[part 2 of 4: packages /Cluster to /NmConfig]
AUTOSAR XML (schema 4-3-0)
package /Cluster
  lin cluster Zone_VR_LIN12: baudrate=19200, protocol-name=LIN, protocol-version=2.0
    lin physical channel CHNL: comm-connectors=CN_Zone_VR_LIN12
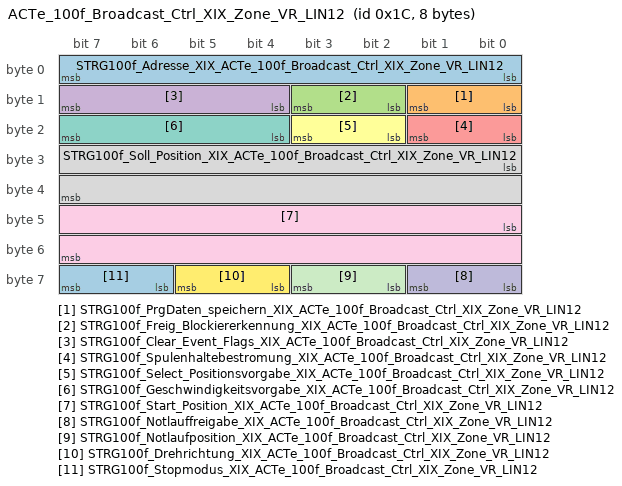
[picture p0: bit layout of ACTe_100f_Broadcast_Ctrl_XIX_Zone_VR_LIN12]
      frame ACTe_100f_Broadcast_Ctrl_XIX_Zone_VR_LIN12: id 0x1C, from Zone_VR, frame-length=8, lin-checksum=ENHANCED
        pdu ACTe_100f_Broadcast_Ctrl_XIX_Zone_VR_LIN12: length=8, unused-bit-pattern=0
          signal STRG100f_Adresse_XIX_ACTe_100f_Broadcast_Ctrl_XIX_Zone_VR_LIN12: start 0, 8 bit, little-endian, data-type-policy=OVERRIDE, i-signal-type=PRIMITIVE, init-value=0, base-type=BT_STRG100f_Adresse, invalid-value=Invalid_STRG100f_Adresse_XIX_ACTe_100f_Broadcast_Ctrl_XIX_Zone_VR_LIN12:255, compu {phys=raw for raw 0..253, 255=Cxff_Fehler, 254=Cxfe_IDLE_INIT; unit Unit_None}, range phys 0..253 Unit_None, raw 0..255, unit=Unit_None, transfer-property=PENDING  # Knotenadresse des Empfängers, 127(dez) ist "Broadcast", 128.....159 (dez) sind Gruppenadressen
          signal STRG100f_PrgDaten_speichern_XIX_ACTe_100f_Broadcast_Ctrl_XIX_Zone_VR_LIN12: start 8, 2 bit, little-endian, data-type-policy=OVERRIDE, i-signal-type=PRIMITIVE, init-value=0, base-type=BT_STRG100f_PrgDaten_speichern, invalid-value=Invalid_STRG100f_PrgDaten_speichern_XIX_ACTe_100f_Broadcast_Ctrl_XIX_Zone_VR_LIN12:3, compu {3=Cx3_Fehler, 2=Cx2_reserviert, 0=Cx0_nicht_speichern, 1=Cx1_speichern}, range raw 0..3, transfer-property=PENDING  # Speicherung der Programmierdaten
          signal STRG100f_Freig_Blockiererkennung_XIX_ACTe_100f_Broadcast_Ctrl_XIX_Zone_VR_LIN12: start 10, 2 bit, little-endian, data-type-policy=OVERRIDE, i-signal-type=PRIMITIVE, init-value=0, base-type=BT_STRG100f_Freig_Blockiererkennung, invalid-value=Invalid_STRG100f_Freig_Blockiererkennung_XIX_ACTe_100f_Broadcast_Ctrl_XIX_Zone_VR_LIN12:3, compu {3=Cx3_Fehler, 1=Cx1_Blockiererkennung_ein, 0=Cx0_Blockiererkennung_aus, 2=Cx2_reserviert}, range raw 0..3, transfer-property=PENDING  # Das Master-SG gibt eine aktive oder inaktive Blockiererkennung vor
          signal STRG100f_Clear_Event_Flags_XIX_ACTe_100f_Broadcast_Ctrl_XIX_Zone_VR_LIN12: start 12, 4 bit, little-endian, data-type-policy=OVERRIDE, i-signal-type=PRIMITIVE, init-value=0, base-type=BT_STRG100f_Clear_Event_Flags, invalid-value=Invalid_STRG100f_Clear_Event_Flags_XIX_ACTe_100f_Broadcast_Ctrl_XIX_Zone_VR_LIN12:15, compu {15=Cxf_Fehler, 4=Cx4_Clear_BL, 12=Cxc_Clear_BL_Reset, 0=Cx0_Event_Flags_nicht_zuruecksetzen, 14=Cxe_Clear_NL_BL_Reset, 6=Cx6_Clear_NL_BL, 8=Cx8_Clear_Reset, 2=Cx2_Clear_NL, 10=Cxa_Clear_NL_Reset}, range raw 0..15, transfer-property=PENDING  # Das Steuergerät löscht die Event-Flags NL: Notlauf aufgetreten, BL: Blockierung aufgetreten
          signal STRG100f_Spulenhaltebestromung_XIX_ACTe_100f_Broadcast_Ctrl_XIX_Zone_VR_LIN12: start 16, 2 bit, little-endian, data-type-policy=OVERRIDE, i-signal-type=PRIMITIVE, init-value=0, base-type=BT_STRG100f_Spulenhaltebestromung, invalid-value=Invalid_STRG100f_Spulenhaltebestromung_XIX_ACTe_100f_Broadcast_Ctrl_XIX_Zone_VR_LIN12:3, compu {3=Cx3_Fehler, 1=Cx1_Motorspulen_bestromt, 0=Cx0_Motorspulen_unbestromt, 2=Cx2_reserviert}, range raw 0..3, transfer-property=PENDING  # Vorgabe für die Spulenhaltebestromung im STOP-Mode
          signal STRG100f_Select_Positionsvorgabe_XIX_ACTe_100f_Broadcast_Ctrl_XIX_Zone_VR_LIN12: start 18, 2 bit, little-endian, data-type-policy=OVERRIDE, i-signal-type=PRIMITIVE, init-value=0, base-type=BT_STRG100f_Select_Positionsvorgabe, invalid-value=Invalid_STRG100f_Select_Positionsvorgabe_XIX_ACTe_100f_Broadcast_Ctrl_XIX_Zone_VR_LIN12:3, compu {3=Cx3_Fehler, 2=Cx2_keine_Positionsvorgabe_gueltig, 1=Cx1_Start_Position_gueltig, 0=Cx0_Soll_Position_gueltig}, range raw 0..3, transfer-property=PENDING  # Vorgabe der Gültigkeit der Positionsvorgaben
          signal STRG100f_Geschwindigkeitsvorgabe_XIX_ACTe_100f_Broadcast_Ctrl_XIX_Zone_VR_LIN12: start 20, 4 bit, little-endian, data-type-policy=OVERRIDE, i-signal-type=PRIMITIVE, init-value=0, base-type=BT_STRG100f_Geschwindigkeitsvorgabe, invalid-value=Invalid_STRG100f_Geschwindigkeitsvorgabe_XIX_ACTe_100f_Broadcast_Ctrl_XIX_Zone_VR_LIN12:15, compu {15=Cxf_Fehler, 4=Cx4_Geschwindigkeitsstufe_4, 3=Cx3_Geschwindigkeitsstufe_3, 2=Cx2_Geschwindigkeitsstufe_2, 1=Cx1_Geschwindigkeitsstufe_1, 5=Cx5_Autospeed, 0=Cx0_reserviert}, range raw 0..15, transfer-property=PENDING  # Vorgabe der Geschwindigkeitsstufe
          signal STRG100f_Soll_Position_XIX_ACTe_100f_Broadcast_Ctrl_XIX_Zone_VR_LIN12: start 24, 16 bit, little-endian, data-type-policy=OVERRIDE, i-signal-type=PRIMITIVE, init-value=0, base-type=BT_STRG100f_Soll_Position, invalid-value=Invalid_STRG100f_Soll_Position_XIX_ACTe_100f_Broadcast_Ctrl_XIX_Zone_VR_LIN12:65535, compu {phys=raw for raw 0..65534, 65535=Cxffff_Fehler; unit Unit_None}, range phys 0..65534 Unit_None, raw 0..65535, unit=Unit_None, transfer-property=PENDING  # Vorgabe der Sollposition
          signal STRG100f_Start_Position_XIX_ACTe_100f_Broadcast_Ctrl_XIX_Zone_VR_LIN12: start 40, 16 bit, little-endian, data-type-policy=OVERRIDE, i-signal-type=PRIMITIVE, init-value=0, base-type=BT_STRG100f_Start_Position, invalid-value=Invalid_STRG100f_Start_Position_XIX_ACTe_100f_Broadcast_Ctrl_XIX_Zone_VR_LIN12:65535, compu {phys=raw for raw 0..65534, 65535=Cxffff_Fehler; unit Unit_None}, range phys 0..65534 Unit_None, raw 0..65535, unit=Unit_None, transfer-property=PENDING  # Vorgabe der Startposition
          signal STRG100f_Notlauffreigabe_XIX_ACTe_100f_Broadcast_Ctrl_XIX_Zone_VR_LIN12: start 56, 2 bit, little-endian, data-type-policy=OVERRIDE, i-signal-type=PRIMITIVE, init-value=0, base-type=BT_STRG100f_Notlauffreigabe, invalid-value=Invalid_STRG100f_Notlauffreigabe_XIX_ACTe_100f_Broadcast_Ctrl_XIX_Zone_VR_LIN12:3, compu {3=Cx3_Fehler, 2=Cx2_reserviert, 0=Cx0_Notlauf_aus, 1=Cx1_Notlauf_ein}, range raw 0..3, transfer-property=PENDING  # Freigabe des Notlaufs
          signal STRG100f_Notlaufposition_XIX_ACTe_100f_Broadcast_Ctrl_XIX_Zone_VR_LIN12: start 58, 2 bit, little-endian, data-type-policy=OVERRIDE, i-signal-type=PRIMITIVE, init-value=0, base-type=BT_STRG100f_Notlaufposition, invalid-value=Invalid_STRG100f_Notlaufposition_XIX_ACTe_100f_Broadcast_Ctrl_XIX_Zone_VR_LIN12:3, compu {3=Cx3_Fehler, 1=Cx1_oberer_Anschlag, 2=Cx2_reserviert, 0=Cx0_unterer_Anschlag}, range raw 0..3, transfer-property=PENDING  # Positionsvorgabe, welche bei aktiven Notlauf angelaufen wird
          signal STRG100f_Drehrichtung_XIX_ACTe_100f_Broadcast_Ctrl_XIX_Zone_VR_LIN12: start 60, 2 bit, little-endian, data-type-policy=OVERRIDE, i-signal-type=PRIMITIVE, init-value=0, base-type=BT_STRG100f_Drehrichtung, invalid-value=Invalid_STRG100f_Drehrichtung_XIX_ACTe_100f_Broadcast_Ctrl_XIX_Zone_VR_LIN12:3, compu {3=Cx3_Fehler, 2=Cx2_reserviert, 0=Cx0_Bewegung_in_Richtung_CW, 1=Cx1_Bewegung_in_Richtung_CCW}, range raw 0..3, transfer-property=PENDING  # Vorgabe der Drehrichtung
          signal STRG100f_Stopmodus_XIX_ACTe_100f_Broadcast_Ctrl_XIX_Zone_VR_LIN12: start 62, 2 bit, little-endian, data-type-policy=OVERRIDE, i-signal-type=PRIMITIVE, init-value=0, base-type=BT_STRG100f_Stopmodus, invalid-value=Invalid_STRG100f_Stopmodus_XIX_ACTe_100f_Broadcast_Ctrl_XIX_Zone_VR_LIN12:3, compu {3=Cx3_Fehler, 0=Cx0_normal_mode, 1=Cx1_stop_mode, 2=Cx2_Status_Adresse_als_Gruppenadr}, range raw 0..3, transfer-property=PENDING  # Vorgabe des StopModus
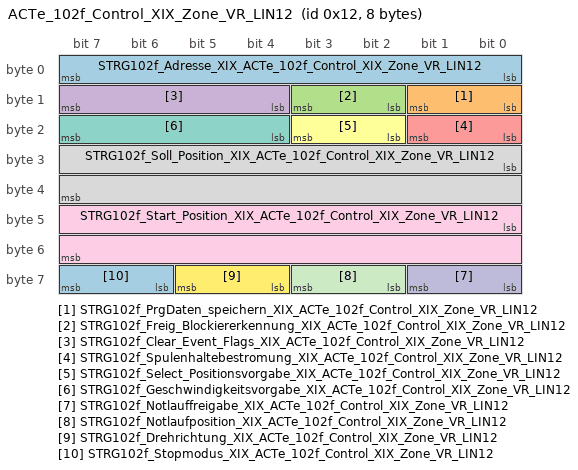
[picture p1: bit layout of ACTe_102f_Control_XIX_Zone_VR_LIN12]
      frame ACTe_102f_Control_XIX_Zone_VR_LIN12: id 0x12, from Zone_VR, frame-length=8, lin-checksum=ENHANCED
        pdu ACTe_102f_Control_XIX_Zone_VR_LIN12: length=8, unused-bit-pattern=0
          signal STRG102f_Adresse_XIX_ACTe_102f_Control_XIX_Zone_VR_LIN12: start 0, 8 bit, little-endian, data-type-policy=OVERRIDE, i-signal-type=PRIMITIVE, init-value=254, base-type=BT_STRG102f_Adresse, invalid-value=Invalid_STRG102f_Adresse_XIX_ACTe_102f_Control_XIX_Zone_VR_LIN12:255, compu {phys=raw for raw 0..253, 255=Cxff_Fehler, 254=Cxfe_IDLE_INIT; unit Unit_None}, range phys 0..253 Unit_None, raw 0..255, unit=Unit_None, transfer-property=PENDING  # Knotenadresse des Empfängers, 127(dez) ist "Broadcast", 128.....159 (dez) sind Gruppenadressen
          signal STRG102f_PrgDaten_speichern_XIX_ACTe_102f_Control_XIX_Zone_VR_LIN12: start 8, 2 bit, little-endian, data-type-policy=OVERRIDE, i-signal-type=PRIMITIVE, init-value=0, base-type=BT_STRG102f_PrgDaten_speichern, compu {2=Cx2_reserviert, 0=Cx0_nicht_speichern, 1=Cx1_speichern}, range raw 0..2, transfer-property=PENDING  # Speicherung der Programmierdaten
          signal STRG102f_Freig_Blockiererkennung_XIX_ACTe_102f_Control_XIX_Zone_VR_LIN12: start 10, 2 bit, little-endian, data-type-policy=OVERRIDE, i-signal-type=PRIMITIVE, init-value=0, base-type=BT_STRG102f_Freig_Blockiererkennung, compu {1=Cx1_Blockiererkennung_ein, 2=Cx2_reserviert, 0=Cx0_Blockiererkennung_aus}, range raw 0..2, transfer-property=PENDING  # Das Master-SG gibt eine aktive oder inaktive Blockiererkennung vor
          signal STRG102f_Clear_Event_Flags_XIX_ACTe_102f_Control_XIX_Zone_VR_LIN12: start 12, 4 bit, little-endian, data-type-policy=OVERRIDE, i-signal-type=PRIMITIVE, init-value=0, base-type=BT_STRG102f_Clear_Event_Flags, compu {6=Cx6_Clear_NL_BL, 14=Cxe_Clear_NL_BL_Reset, 0=Cx0_Event_Flags_nicht_zuruecksetzen, 2=Cx2_Clear_NL, 4=Cx4_Clear_BL, 12=Cxc_Clear_BL_Reset, 10=Cxa_Clear_NL_Reset, 8=Cx8_Clear_Reset}, range raw 0..14, transfer-property=PENDING  # Das Steuergerät löscht die Event-Flags NL: Notlauf aufgetreten, BL: Blockierung aufgetreten
          signal STRG102f_Spulenhaltebestromung_XIX_ACTe_102f_Control_XIX_Zone_VR_LIN12: start 16, 2 bit, little-endian, data-type-policy=OVERRIDE, i-signal-type=PRIMITIVE, init-value=0, base-type=BT_STRG102f_Spulenhaltebestromung, compu {1=Cx1_Motorspulen_bestromt, 0=Cx0_Motorspulen_unbestromt, 2=Cx2_reserviert}, range raw 0..2, transfer-property=PENDING  # Vorgabe für die Spulenhaltebestromung im STOP-Mode
          signal STRG102f_Select_Positionsvorgabe_XIX_ACTe_102f_Control_XIX_Zone_VR_LIN12: start 18, 2 bit, little-endian, data-type-policy=OVERRIDE, i-signal-type=PRIMITIVE, init-value=0, base-type=BT_STRG102f_Select_Positionsvorgabe, compu {0=Cx0_Soll_Position_gueltig, 2=Cx2_keine_Positionsvorgabe_gueltig, 1=Cx1_Start_Position_gueltig}, range raw 0..2, transfer-property=PENDING  # Vorgabe der Gültigkeit der Positionsvorgaben
          signal STRG102f_Geschwindigkeitsvorgabe_XIX_ACTe_102f_Control_XIX_Zone_VR_LIN12: start 20, 4 bit, little-endian, data-type-policy=OVERRIDE, i-signal-type=PRIMITIVE, init-value=0, base-type=BT_STRG102f_Geschwindigkeitsvorgabe, compu {2=Cx2_Geschwindigkeitsstufe_2, 4=Cx4_Geschwindigkeitsstufe_4, 3=Cx3_Geschwindigkeitsstufe_3, 1=Cx1_Geschwindigkeitsstufe_1, 5=Cx5_Autospeed, 0=Cx0_reserviert}, range raw 0..5, transfer-property=PENDING  # Vorgabe der Geschwindigkeitsstufe
          signal STRG102f_Soll_Position_XIX_ACTe_102f_Control_XIX_Zone_VR_LIN12: start 24, 16 bit, little-endian, data-type-policy=OVERRIDE, i-signal-type=PRIMITIVE, init-value=0, base-type=BT_STRG102f_Soll_Position, compu {phys=raw for raw 0..65534; unit Unit_None}, range phys 0..65534 Unit_None, raw 0..65534, unit=Unit_None, transfer-property=PENDING  # Vorgabe der Sollposition
          signal STRG102f_Start_Position_XIX_ACTe_102f_Control_XIX_Zone_VR_LIN12: start 40, 16 bit, little-endian, data-type-policy=OVERRIDE, i-signal-type=PRIMITIVE, init-value=0, base-type=BT_STRG102f_Start_Position, compu {phys=raw for raw 0..65534; unit Unit_None}, range phys 0..65534 Unit_None, raw 0..65534, unit=Unit_None, transfer-property=PENDING  # Vorgabe der Startposition
          signal STRG102f_Notlauffreigabe_XIX_ACTe_102f_Control_XIX_Zone_VR_LIN12: start 56, 2 bit, little-endian, data-type-policy=OVERRIDE, i-signal-type=PRIMITIVE, init-value=0, base-type=BT_STRG102f_Notlauffreigabe, compu {2=Cx2_reserviert, 1=Cx1_Notlauf_ein, 0=Cx0_Notlauf_aus}, range raw 0..2, transfer-property=PENDING  # Freigabe des Notlaufs
          signal STRG102f_Notlaufposition_XIX_ACTe_102f_Control_XIX_Zone_VR_LIN12: start 58, 2 bit, little-endian, data-type-policy=OVERRIDE, i-signal-type=PRIMITIVE, init-value=0, base-type=BT_STRG102f_Notlaufposition, compu {0=Cx0_unterer_Anschlag, 2=Cx2_reserviert, 1=Cx1_oberer_Anschlag}, range raw 0..2, transfer-property=PENDING  # Positionsvorgabe, welche bei aktiven Notlauf angelaufen wird
          signal STRG102f_Drehrichtung_XIX_ACTe_102f_Control_XIX_Zone_VR_LIN12: start 60, 2 bit, little-endian, data-type-policy=OVERRIDE, i-signal-type=PRIMITIVE, init-value=0, base-type=BT_STRG102f_Drehrichtung, compu {2=Cx2_reserviert, 0=Cx0_Bewegung_in_Richtung_CW, 1=Cx1_Bewegung_in_Richtung_CCW}, range raw 0..2, transfer-property=PENDING  # Vorgabe der Drehrichtung
          signal STRG102f_Stopmodus_XIX_ACTe_102f_Control_XIX_Zone_VR_LIN12: start 62, 2 bit, little-endian, data-type-policy=OVERRIDE, i-signal-type=PRIMITIVE, init-value=0, base-type=BT_STRG102f_Stopmodus, compu {0=Cx0_normal_mode, 1=Cx1_stop_mode, 2=Cx2_Status_Adresse_als_Gruppenadr}, range raw 0..2, transfer-property=PENDING  # Vorgabe des StopModus
      frame ACTs_102f_Status_XIX_Zone_VR_LIN12: id 0x19, to Zone_VR, frame-length=8, lin-checksum=ENHANCED
        pdu ACTs_102f_Status_XIX_Zone_VR_LIN12: length=8, unused-bit-pattern=0
          signal ACT102f_ResponseError_XIX_ACTs_102f_Status_XIX_Zone_VR_LIN12: start 0, 1 bit, little-endian, data-type-policy=OVERRIDE, i-signal-type=PRIMITIVE, init-value=0, base-type=BT_ACT102f_ResponseError, invalid-value=Invalid_ACT102f_ResponseError_XIX_ACTs_102f_Status_XIX_Zone_VR_LIN12:1, compu {1=Cx1_Fehler, 0=Cx0_normal}, range raw 0..1, transfer-property=PENDING  # siehe LIN2.0-Specification (Darf nicht über ein Fehlergueltigkeitsbit abgesichtert werden!)
          signal ACT102f_Uebertemperatur_XIX_ACTs_102f_Status_XIX_Zone_VR_LIN12: start 2, 2 bit, little-endian, data-type-policy=OVERRIDE, i-signal-type=PRIMITIVE, init-value=0, base-type=BT_ACT102f_Uebertemperatur, invalid-value=Invalid_ACT102f_Uebertemperatur_XIX_ACTs_102f_Status_XIX_Zone_VR_LIN12:3, compu {3=Cx3_Fehler, 1=Cx1_Uebertemperatur, 0=Cx0_keine_Uebertemperatur, 2=Cx2_reserviert}, range raw 0..3, transfer-property=PENDING, to Zone_VR(timeout 3.5 s)  # Anzeige einer Übertemperatur im Stellmotoren-ASIC
          signal ACT102f_el_Defekt_XIX_ACTs_102f_Status_XIX_Zone_VR_LIN12: start 4, 2 bit, little-endian, data-type-policy=OVERRIDE, i-signal-type=PRIMITIVE, init-value=0, base-type=BT_ACT102f_el_Defekt, invalid-value=Invalid_ACT102f_el_Defekt_XIX_ACTs_102f_Status_XIX_Zone_VR_LIN12:3, compu {3=Cx3_Fehler, 1=Cx1_el_Fehler_1, 0=Cx0_kein_Fehler, 2=Cx2_el_Fehler_2}, range raw 0..3, transfer-property=PENDING, to Zone_VR(timeout 3.5 s)  # Anzeige für einen elektrischen Fehler im Stellmotor
          signal ACT102f_Versorgungsspannung_XIX_ACTs_102f_Status_XIX_Zone_VR_LIN12: start 6, 2 bit, little-endian, data-type-policy=OVERRIDE, i-signal-type=PRIMITIVE, init-value=0, base-type=BT_ACT102f_Versorgungsspannung, invalid-value=Invalid_ACT102f_Versorgungsspannung_XIX_ACTs_102f_Status_XIX_Zone_VR_LIN12:3, compu {3=Cx3_Fehler, 0=Cx0_Spannung_im_zulaessigen_Bereich, 1=Cx1_Unterspannung, 2=Cx2_Ueberspanung}, range raw 0..3, transfer-property=PENDING, to Zone_VR(timeout 3.5 s)  # Versorgungsspannung des Aktuators
          signal ACT102f_Notlauf_aufgetreten_XIX_ACTs_102f_Status_XIX_Zone_VR_LIN12: start 8, 2 bit, little-endian, data-type-policy=OVERRIDE, i-signal-type=PRIMITIVE, init-value=0, base-type=BT_ACT102f_Notlauf_aufgetreten, invalid-value=Invalid_ACT102f_Notlauf_aufgetreten_XIX_ACTs_102f_Status_XIX_Zone_VR_LIN12:3, compu {3=Cx3_Fehler, 0=Cx0_kein_Notlauf_aufgetreten, 2=Cx2_reserviert, 1=Cx1_Notlauf_aufgetreten}, range raw 0..3, transfer-property=PENDING, to Zone_VR(timeout 3.5 s)  # Anzeige eines aufgetretenen Notlaufs seit dem letzten Reset oder "Clear Notlauf aufgetreten"
          signal ACT102f_Blockierung_aufgetreten_XIX_ACTs_102f_Status_XIX_Zone_VR_LIN12: start 12, 2 bit, little-endian, data-type-policy=OVERRIDE, i-signal-type=PRIMITIVE, init-value=0, base-type=BT_ACT102f_Blockierung_aufgetreten, invalid-value=Invalid_ACT102f_Blockierung_aufgetreten_XIX_ACTs_102f_Status_XIX_Zone_VR_LIN12:3, compu {3=Cx3_Fehler, 0=Cx0_keine_Blockierung, 2=Cx2_reserviert, 1=Cx1_Blockierung_erkannt}, range raw 0..3, transfer-property=PENDING, to Zone_VR(timeout 3.5 s)  # Anzeige einer aufgetretenen Blockierung seit dem letzten Reset oder "Clear Blockierung aufgetreten"
          signal ACT102f_Reset_XIX_ACTs_102f_Status_XIX_Zone_VR_LIN12: start 14, 2 bit, little-endian, data-type-policy=OVERRIDE, i-signal-type=PRIMITIVE, init-value=0, base-type=BT_ACT102f_Reset, invalid-value=Invalid_ACT102f_Reset_XIX_ACTs_102f_Status_XIX_Zone_VR_LIN12:3, compu {3=Cx3_Fehler, 1=Cx1_Reset_durchgefuehrt, 0=Cx0_kein_Reset, 2=Cx2_reserviert}, range raw 0..3, transfer-property=PENDING, to Zone_VR(timeout 3.5 s)  # Anzeige eines aufgetretenen Reset seit dem letzten ¿Clear Reset"
          signal ACT102f_Spulenbestromung_XIX_ACTs_102f_Status_XIX_Zone_VR_LIN12: start 16, 2 bit, little-endian, data-type-policy=OVERRIDE, i-signal-type=PRIMITIVE, init-value=0, base-type=BT_ACT102f_Spulenbestromung, invalid-value=Invalid_ACT102f_Spulenbestromung_XIX_ACTs_102f_Status_XIX_Zone_VR_LIN12:3, compu {3=Cx3_Fehler, 1=Cx1_Motorspulen_bestromt, 0=Cx0_Motorspulen_unbestromt, 2=Cx2_reserviert}, range raw 0..3, transfer-property=PENDING, to Zone_VR(timeout 3.5 s)  # Spulenbestromung im Haltezustand des Aktuators
          signal ACT102f_Positionsvorgabe_Status_XIX_ACTs_102f_Status_XIX_Zone_VR_LIN12: start 18, 2 bit, little-endian, data-type-policy=OVERRIDE, i-signal-type=PRIMITIVE, init-value=0, base-type=BT_ACT102f_Positionsvorgabe_Status, invalid-value=Invalid_ACT102f_Positionsvorgabe_Status_XIX_ACTs_102f_Status_XIX_Zone_VR_LIN12:3, compu {3=Cx3_Fehler, 1=Cx1_Start_Position_gueltig, 2=Cx2_keine_Positionsvorgabe_gueltig, 0=Cx0_Soll_Position_gueltig}, range raw 0..3, transfer-property=PENDING, to Zone_VR(timeout 3.5 s)  # Position des Aktuators
          signal ACT102f_Geschwindigkeitsstatus_XIX_ACTs_102f_Status_XIX_Zone_VR_LIN12: start 20, 4 bit, little-endian, data-type-policy=OVERRIDE, i-signal-type=PRIMITIVE, init-value=0, base-type=BT_ACT102f_Geschwindigkeitsstatus, invalid-value=Invalid_ACT102f_Geschwindigkeitsstatus_XIX_ACTs_102f_Status_XIX_Zone_VR_LIN12:15, compu {15=Cxf_Fehler, 3=Cx3_Geschwindigkeitsstufe_3, 5=Cx5_Autospeed, 0=Cx0_Motor_steht, 2=Cx2_Geschwindigkeitsstufe_2, 4=Cx4_Geschwindigkeitsstufe_4, 1=Cx1_Geschwindigkeitsstufe_1}, range raw 0..15, transfer-property=PENDING, to Zone_VR(timeout 3.5 s)  # Geschwindigkeitsstufe mit der die aktuelle Verfahrbewegung durchgeführt wird
          signal ACT102f_Ist_Position_Aktuator_XIX_ACTs_102f_Status_XIX_Zone_VR_LIN12: start 24, 16 bit, little-endian, data-type-policy=OVERRIDE, i-signal-type=PRIMITIVE, init-value=32767, base-type=BT_ACT102f_Ist_Position_Aktuator, invalid-value=Invalid_ACT102f_Ist_Position_Aktuator_XIX_ACTs_102f_Status_XIX_Zone_VR_LIN12:65535, compu {phys=raw for raw 0..65534, 65535=Cxffff_Fehler; unit Unit_None}, range phys 0..65534 Unit_None, raw 0..65535, unit=Unit_None, transfer-property=PENDING, to Zone_VR(timeout 3.5 s)  # IST-Position des Aktuators
          signal ACT102f_Verfahrrichtung_XIX_ACTs_102f_Status_XIX_Zone_VR_LIN12: start 40, 2 bit, little-endian, data-type-policy=OVERRIDE, i-signal-type=PRIMITIVE, init-value=2, base-type=BT_ACT102f_Verfahrrichtung, invalid-value=Invalid_ACT102f_Verfahrrichtung_XIX_ACTs_102f_Status_XIX_Zone_VR_LIN12:3, compu {3=Cx3_Fehler, 0=Cx0_Richtung_kl_Schrittpositionen, 1=Cx1_Richtung_gr_Schrittpositionen, 2=Cx2_Init}, range raw 0..3, transfer-property=PENDING, to Zone_VR(timeout 3.5 s)  # Verfahrrichtung der aktuellen oder zuletzt stattgefundenen Bewegung des Aktuators
          signal ACT102f_Selbsthaltemoment_XIX_ACTs_102f_Status_XIX_Zone_VR_LIN12: start 42, 2 bit, little-endian, data-type-policy=OVERRIDE, i-signal-type=PRIMITIVE, init-value=0, base-type=BT_ACT102f_Selbsthaltemoment, invalid-value=Invalid_ACT102f_Selbsthaltemoment_XIX_ACTs_102f_Status_XIX_Zone_VR_LIN12:3, compu {3=Cx3_Fehler, 0=Cx0_ohne_Selbsthaltemoment, 1=Cx1_mit_Selbsthaltemoment, 2=Cx2_reserviert}, range raw 0..3, transfer-property=PENDING, to Zone_VR(timeout 3.5 s)  # Das Signal gibt an ob ein selbsthemmendes Getriebe verbaut ist oder die SHB eingeschaltet ist
          signal ACT102f_Sonderfunktionen_XIX_ACTs_102f_Status_XIX_Zone_VR_LIN12: start 44, 2 bit, little-endian, data-type-policy=OVERRIDE, i-signal-type=PRIMITIVE, init-value=0, base-type=BT_ACT102f_Sonderfunktionen, invalid-value=Invalid_ACT102f_Sonderfunktionen_XIX_ACTs_102f_Status_XIX_Zone_VR_LIN12:3, compu {3=Cx3_Fehler, 0=Cx0_Keine_Sonderfunktion_aktiv, 1=Cx1_Sonderfunktion1_aktiv, 2=Cx2_Sonderfunktion2_aktiv}, range raw 0..3, transfer-property=PENDING, to Zone_VR(timeout 3.5 s)  # Funktionen des Aktuators
          signal ACT102f_Variante_XIX_ACTs_102f_Status_XIX_Zone_VR_LIN12: start 46, 2 bit, little-endian, data-type-policy=OVERRIDE, i-signal-type=PRIMITIVE, init-value=0, base-type=BT_ACT102f_Variante, compu {1=Cx1_Variante_2, 2=Cx2_Variante_3, 3=Cx3_Fehler_oder_nicht_umgesetzt, 0=Cx0_Variante_1}, range raw 0..3, transfer-property=PENDING, to Zone_VR(timeout 3.5 s)  # Das Signal gibt an welche Variante des Stellmotors verbaut ist
          signal ACT102f_Adresse_Aktuator_XIX_ACTs_102f_Status_XIX_Zone_VR_LIN12: start 48, 8 bit, little-endian, data-type-policy=OVERRIDE, i-signal-type=PRIMITIVE, init-value=255, base-type=BT_ACT102f_Adresse_Aktuator, compu {255=Cxff_Init}, range raw 255, transfer-property=PENDING, to Zone_VR(timeout 3.5 s)  # Adresse Aktuator
          signal ACT102f_Notlauffreigabe_XIX_ACTs_102f_Status_XIX_Zone_VR_LIN12: start 56, 2 bit, little-endian, data-type-policy=OVERRIDE, i-signal-type=PRIMITIVE, init-value=0, base-type=BT_ACT102f_Notlauffreigabe, invalid-value=Invalid_ACT102f_Notlauffreigabe_XIX_ACTs_102f_Status_XIX_Zone_VR_LIN12:3, compu {3=Cx3_Fehler, 1=Cx1_Notlauf_ein, 2=Cx2_reserviert, 0=Cx0_Notlauf_aus}, range raw 0..3, transfer-property=PENDING, to Zone_VR(timeout 3.5 s)  # Freigabe der Notlauffunktion des Aktuators
          signal ACT102f_Notlaufposition_XIX_ACTs_102f_Status_XIX_Zone_VR_LIN12: start 58, 2 bit, little-endian, data-type-policy=OVERRIDE, i-signal-type=PRIMITIVE, init-value=0, base-type=BT_ACT102f_Notlaufposition, invalid-value=Invalid_ACT102f_Notlaufposition_XIX_ACTs_102f_Status_XIX_Zone_VR_LIN12:3, compu {3=Cx3_Fehler, 1=Cx1_oberer_Anschlag, 0=Cx0_unterer_Anschlag, 2=Cx2_reserviert}, range raw 0..3, transfer-property=PENDING, to Zone_VR(timeout 3.5 s)  # Positionsvorgabe des Aktuators
          signal ACT102f_Drehrichtung_XIX_ACTs_102f_Status_XIX_Zone_VR_LIN12: start 60, 2 bit, little-endian, data-type-policy=OVERRIDE, i-signal-type=PRIMITIVE, init-value=0, base-type=BT_ACT102f_Drehrichtung, invalid-value=Invalid_ACT102f_Drehrichtung_XIX_ACTs_102f_Status_XIX_Zone_VR_LIN12:3, compu {3=Cx3_Fehler, 2=Cx2_reserviert, 1=Cx1_Bewegung_in_Richtung_CCW, 0=Cx0_Bewegung_in_Richtung_CW}, range raw 0..3, transfer-property=PENDING, to Zone_VR(timeout 3.5 s)  # Drehrichtung des Aktuators
          signal ACT102f_Stopmodus_XIX_ACTs_102f_Status_XIX_Zone_VR_LIN12: start 62, 2 bit, little-endian, data-type-policy=OVERRIDE, i-signal-type=PRIMITIVE, init-value=0, base-type=BT_ACT102f_Stopmodus, invalid-value=Invalid_ACT102f_Stopmodus_XIX_ACTs_102f_Status_XIX_Zone_VR_LIN12:3, compu {3=Cx3_Fehler, 2=Cx2_reserviert, 1=Cx1_Stop_Mode, 0=Cx0_Normal_Mode}, range raw 0..3, transfer-property=PENDING, to Zone_VR(timeout 3.5 s)  # Modus des Aktuators
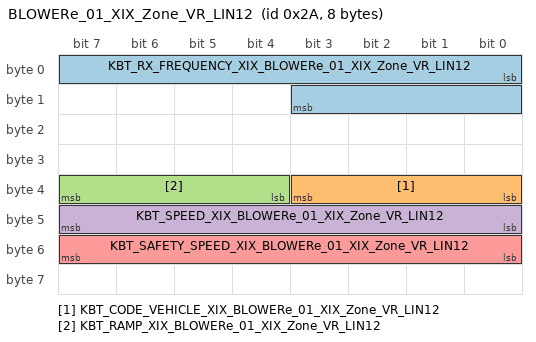
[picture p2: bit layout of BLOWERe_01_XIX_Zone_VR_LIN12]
      frame BLOWERe_01_XIX_Zone_VR_LIN12: id 0x2A, from Zone_VR, frame-length=8, lin-checksum=ENHANCED
        pdu BLOWERe_01_XIX_Zone_VR_LIN12: length=8, unused-bit-pattern=0
          signal KBT_RX_FREQUENCY_XIX_BLOWERe_01_XIX_Zone_VR_LIN12: start 0, 12 bit, little-endian, data-type-policy=OVERRIDE, i-signal-type=PRIMITIVE, init-value=0, base-type=BT_KBT_RX_FREQUENCY, compu {phys=raw+150 for raw 0..1896, 4095=Cxfff_ungueltig; unit Unit_KiloHertz}, range phys 150..2046 Unit_KiloHertz, raw 0..4095, unit=Unit_KiloHertz, transfer-property=PENDING  # Radio Empfangsfrequenz bei AM_Empfang
          signal KBT_CODE_VEHICLE_XIX_BLOWERe_01_XIX_Zone_VR_LIN12: start 32, 4 bit, little-endian, data-type-policy=OVERRIDE, i-signal-type=PRIMITIVE, init-value=0, base-type=BT_KBT_CODE_VEHICLE, compu {1=Cx1_Q7_NF, 7=Cx7_Konzern_Fahrzeug, 3=Cx3_D5, 0=Cx0_Init, 2=Cx2_B9, 4=Cx4_C8, 5=Cx5_Q5_NF, 6=Cx6_MSS}, range raw 0..7, transfer-property=PENDING  # Vorgabe des Betriebszustandes für das Frischluftgebläse BLDC
          signal KBT_RAMP_XIX_BLOWERe_01_XIX_Zone_VR_LIN12: start 36, 4 bit, little-endian, data-type-policy=OVERRIDE, i-signal-type=PRIMITIVE, init-value=0, base-type=BT_KBT_RAMP, compu {phys=raw*100+100 for raw 0..15; unit Unit_MinutInver}, range phys 100..1600 Unit_MinutInver, raw 0..15, unit=Unit_MinutInver, transfer-property=PENDING  # Vorgabe Rampenzeitkonstante für das Frischluftgebläse BLDC
          signal KBT_SPEED_XIX_BLOWERe_01_XIX_Zone_VR_LIN12: start 40, 8 bit, little-endian, data-type-policy=OVERRIDE, i-signal-type=PRIMITIVE, init-value=1, base-type=BT_KBT_SPEED, invalid-value=Invalid_KBT_SPEED_XIX_BLOWERe_01_XIX_Zone_VR_LIN12:255, compu {phys=raw*20 for raw 20..253, 255=Cxff_Fehler, 0=Cx0_Sofort_Abschaltung_ohne_Rampe, 254=Cxfe_reserviert, 1=Cx1_Abschaltung_mit_Rampe; unit Unit_MinutInver}, range phys 400..5060 Unit_MinutInver, raw 0..255, unit=Unit_MinutInver, transfer-property=PENDING  # Vorgabe Sollwert Motordrehzahl für das Frischluftgebläse BLDC
          signal KBT_SAFETY_SPEED_XIX_BLOWERe_01_XIX_Zone_VR_LIN12: start 48, 8 bit, little-endian, data-type-policy=OVERRIDE, i-signal-type=PRIMITIVE, init-value=200, base-type=BT_KBT_SAFETY_SPEED, invalid-value=Invalid_KBT_SAFETY_SPEED_XIX_BLOWERe_01_XIX_Zone_VR_LIN12:255, compu {phys=raw*20 for raw 0..253, 255=Cxff_Fehler, 254=Cxfe_reserviert; unit Unit_MinutInver}, range phys 0..5060 Unit_MinutInver, raw 0..255, unit=Unit_MinutInver, transfer-property=PENDING  # Vorgabe Sollwert Notlaufmotordrehzahl für das Frischluftgebläse BLDC
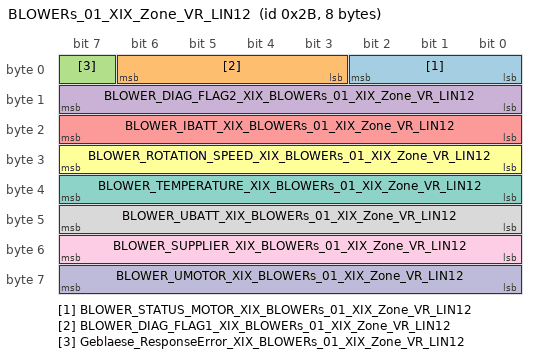
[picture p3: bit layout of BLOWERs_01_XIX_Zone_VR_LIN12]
      frame BLOWERs_01_XIX_Zone_VR_LIN12: id 0x2B, to Zone_VR, frame-length=8, lin-checksum=ENHANCED
        pdu BLOWERs_01_XIX_Zone_VR_LIN12: length=8, unused-bit-pattern=0
          signal BLOWER_STATUS_MOTOR_XIX_BLOWERs_01_XIX_Zone_VR_LIN12: start 0, 3 bit, little-endian, data-type-policy=OVERRIDE, i-signal-type=PRIMITIVE, init-value=0, base-type=BT_BLOWER_STATUS_MOTOR, compu {4=Cx4_Notlauf_aktiviert, 1=Cx1_Strombegrenzung_aktiv, 2=Cx2_Sollwert_erreicht, 0=Cx0_Init}, range raw 0..4, transfer-property=PENDING, to Zone_VR(timeout 3.5 s)  # Status Motor des Frischlufgebläse BLDC
          signal BLOWER_DIAG_FLAG1_XIX_BLOWERs_01_XIX_Zone_VR_LIN12: start 3, 4 bit, little-endian, data-type-policy=OVERRIDE, i-signal-type=PRIMITIVE, init-value=0, base-type=BT_BLOWER_DIAG_FLAG1, compu {2=Cx2_Fehler_Temperatur_Sensor, 4=Cx4_Fehler_Brueckentreiber, 0=Cx0_Init, 1=Cx1_Kurzschluss, 8=Cx8_Brueckentreiber_Uebertemperatur}, range raw 0..8, transfer-property=PENDING, to Zone_VR(timeout 3.5 s)  # Status Diagnose 1 des Frischluftgbläse BLDC
          signal Geblaese_ResponseError_XIX_BLOWERs_01_XIX_Zone_VR_LIN12: start 7, 1 bit, little-endian, data-type-policy=OVERRIDE, i-signal-type=PRIMITIVE, init-value=0, base-type=BT_Geblaese_ResponseError, invalid-value=Invalid_Geblaese_ResponseError_XIX_BLOWERs_01_XIX_Zone_VR_LIN12:1, compu {1=Cx1_Fehler, 0=Cx0_normal}, range raw 0..1, transfer-property=PENDING  # siehe LIN2.0-Specification (Darf nicht über ein Fehlergueltigkeitsbit abgesichtert werden!)
          signal BLOWER_DIAG_FLAG2_XIX_BLOWERs_01_XIX_Zone_VR_LIN12: start 8, 8 bit, little-endian, data-type-policy=OVERRIDE, i-signal-type=PRIMITIVE, init-value=0, base-type=BT_BLOWER_DIAG_FLAG2, compu {128=Cx80_Unterspannung_Abschaltung, 32=Cx20_Strom_Offset_Fehler, 8=Cx8_Ueberstrom_Motor, 1=Cx1_interner_Fehler_detektiert_Notabschaltung, 2=Cx2_Blockade_Motor, 16=Cx10_Ueberstrom_Batterie, 4=Cx4_Uebertemperatur, 64=Cx40_Ueberspannung_Abschaltung, 0=Cx0_Init}, range raw 0..128, transfer-property=PENDING, to Zone_VR(timeout 3.5 s)  # Status Diagnose 2 des Frischluftgbläse BLDC
          signal BLOWER_IBATT_XIX_BLOWERs_01_XIX_Zone_VR_LIN12: start 16, 8 bit, little-endian, data-type-policy=OVERRIDE, i-signal-type=PRIMITIVE, init-value=0, base-type=BT_BLOWER_IBATT, compu {phys=raw*0.15 for raw 0..253, 255=Cxff_Fehler_Strommesseinrichtung, 254=Cxfe_kein_Messwert_verfuegbar; unit Unit_Amper}, range phys 0..37.95 Unit_Amper, raw 0..255, unit=Unit_Amper, transfer-property=PENDING, to Zone_VR(timeout 3.5 s)  # Stromaufnahme des Frischluftgbläse BLDC
          signal BLOWER_ROTATION_SPEED_XIX_BLOWERs_01_XIX_Zone_VR_LIN12: start 24, 8 bit, little-endian, data-type-policy=OVERRIDE, i-signal-type=PRIMITIVE, init-value=0, base-type=BT_BLOWER_ROTATION_SPEED, compu {phys=raw*20 for raw 0..253, 254=Cxfe_kein_Messwert_verfuegbar, 255=Cxff_Fehler_Drehzahlmesseinrichtung; unit Unit_MinutInver}, range phys 0..5060 Unit_MinutInver, raw 0..255, unit=Unit_MinutInver, transfer-property=PENDING, to Zone_VR(timeout 3.5 s)  # Drehzahl des Frischluftgebläse BLDC
          signal BLOWER_TEMPERATURE_XIX_BLOWERs_01_XIX_Zone_VR_LIN12: start 32, 8 bit, little-endian, data-type-policy=OVERRIDE, i-signal-type=PRIMITIVE, init-value=0, base-type=BT_BLOWER_TEMPERATURE, invalid-value=Invalid_BLOWER_TEMPERATURE_XIX_BLOWERs_01_XIX_Zone_VR_LIN12:255, compu {phys=raw-40 for raw 0..190, 255=Cxff_Fehler, 254=Cxfe_kein_Messwert_verfuegbar; unit Unit_DegreCelsi}, range phys -40..150 Unit_DegreCelsi, raw 0..255, unit=Unit_DegreCelsi, transfer-property=PENDING, to Zone_VR(timeout 3.5 s)  # Temperatur des Frischluftgebläse BLDC
          signal BLOWER_UBATT_XIX_BLOWERs_01_XIX_Zone_VR_LIN12: start 40, 8 bit, little-endian, data-type-policy=OVERRIDE, i-signal-type=PRIMITIVE, init-value=0, base-type=BT_BLOWER_UBATT, compu {phys=raw*0.1 for raw 0..253, 254=Cxfe_kein_Messwert_verfuegbar, 255=Cxff_Fehler_Spannungsmesseinrichtung; unit Unit_Volt}, range phys 0..25.3 Unit_Volt, raw 0..255, unit=Unit_Volt, transfer-property=PENDING, to Zone_VR(timeout 3.5 s)  # Spannung am Frischluftgebläse BLDC Ubatt (Klemme)
          signal BLOWER_SUPPLIER_XIX_BLOWERs_01_XIX_Zone_VR_LIN12: start 48, 8 bit, little-endian, data-type-policy=OVERRIDE, i-signal-type=PRIMITIVE, init-value=0, base-type=BT_BLOWER_SUPPLIER, compu {31=Cx1f_BROSE, 0=Cx0_Init, 37=Cx25_ASMO, 64=Cx40_BOSCH}, range raw 0..64, transfer-property=PENDING, to Zone_VR(timeout 3.5 s)  # Hersteller-Nummer des Frischluftgebläse BLDC
          signal BLOWER_UMOTOR_XIX_BLOWERs_01_XIX_Zone_VR_LIN12: start 56, 8 bit, little-endian, data-type-policy=OVERRIDE, i-signal-type=PRIMITIVE, init-value=0, base-type=BT_BLOWER_UMOTOR, compu {phys=raw*0.1 for raw 0..253, 254=Cxfe_kein_Messwert_verfuegbar, 255=Cxff_Fehler_Spannungsmesseinrichtung; unit Unit_Volt}, range phys 0..25.3 Unit_Volt, raw 0..255, unit=Unit_Volt, transfer-property=PENDING, to Zone_VR(timeout 3.5 s)  # Phasenspannung Motor des Frischluftgebläse BLDC
      frame BLOWERs_02_XIX_Zone_VR_LIN12: id 0x2E, to Zone_VR, frame-length=8, lin-checksum=ENHANCED
        pdu BLOWERs_02_XIX_Zone_VR_LIN12: length=8, unused-bit-pattern=0
          signal BLOWER_TORQUE_XIX_BLOWERs_02_XIX_Zone_VR_LIN12: start 0, 10 bit, little-endian, data-type-policy=OVERRIDE, i-signal-type=PRIMITIVE, init-value=1022, base-type=BT_BLOWER_TORQUE, invalid-value=Invalid_BLOWER_TORQUE_XIX_BLOWERs_02_XIX_Zone_VR_LIN12:1023, compu {phys=raw*0.001 for raw 0..1021, 1023=Cx3ff_Fehler, 1022=Cx3fe_Init; unit Unit_NewtoMeter}, range phys 0..1.021 Unit_NewtoMeter, raw 0..1023, unit=Unit_NewtoMeter, transfer-property=PENDING, to Zone_VR(timeout 3.5 s)  # Drehmoment des Frischluftgebläse BLDC
      frame MasterReq_XIX_Zone_VR_LIN12: id 0x3C, from Zone_VR, frame-length=8, lin-checksum=CLASSIC
        n pdu MasterReq_XIX_Zone_VR_LIN12: length=8
      frame SlaveResp_XIX_Zone_VR_LIN12: id 0x3D, to Zone_VR, frame-length=8, lin-checksum=CLASSIC
        n pdu SlaveResp_XIX_Zone_VR_LIN12: length=8
      5 x lin schedule table, all with resume-position=CONTINUE-AT-IT-POSITION:
        ST1: run-mode=RUN-CONTINUOUS
          table-entrys:
            delay=0.01, position-in-table=0, frame-triggering=FT_BLOWERe_01
            delay=0.01, position-in-table=1, frame-triggering=FT_ACTe_102f_Control
            delay=0.01, position-in-table=2, frame-triggering=FT_BLOWERs_01
            delay=0.01, position-in-table=3, frame-triggering=FT_ACTs_102f_Status
            delay=0.01, position-in-table=4, frame-triggering=FT_BLOWERs_02
        Broadcast: run-mode=RUN-CONTINUOUS, application-entry{delay=0.01, position-in-table=0, frame-triggering=FT_ACTe_100f_Broadcast_Ctrl}
        Status: run-mode=RUN-CONTINUOUS, application-entry{delay=0.01, position-in-table=0, frame-triggering=FT_ACTs_102f_Status}
        DiagRequest: run-mode=RUN-ONCE, application-entry{delay=0.01, position-in-table=0, frame-triggering=CHNL/FT_MasterReq}
        DiagResponse: run-mode=RUN-ONCE, application-entry{delay=0.01, position-in-table=0, frame-triggering=CHNL/FT_SlaveResp}
  lin cluster Zone_VR_LIN11: baudrate=19200, protocol-name=LIN, protocol-version=2.0
    lin physical channel CHNL: comm-connectors=CN_Zone_VR_LIN11
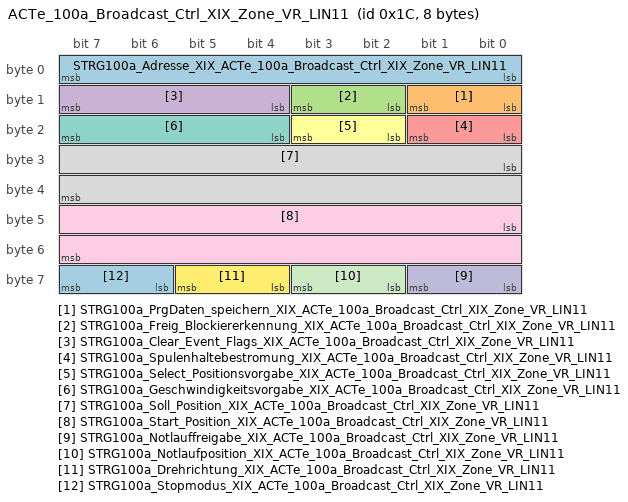
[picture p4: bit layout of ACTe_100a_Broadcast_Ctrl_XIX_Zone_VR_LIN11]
      frame ACTe_100a_Broadcast_Ctrl_XIX_Zone_VR_LIN11: id 0x1C, from Zone_VR, frame-length=8, lin-checksum=ENHANCED
        pdu ACTe_100a_Broadcast_Ctrl_XIX_Zone_VR_LIN11: length=8, unused-bit-pattern=0
          signal STRG100a_Adresse_XIX_ACTe_100a_Broadcast_Ctrl_XIX_Zone_VR_LIN11: start 0, 8 bit, little-endian, data-type-policy=OVERRIDE, i-signal-type=PRIMITIVE, init-value=0, base-type=BT_STRG100a_Adresse, invalid-value=Invalid_STRG100a_Adresse_XIX_ACTe_100a_Broadcast_Ctrl_XIX_Zone_VR_LIN11:255, compu {phys=raw for raw 0..253, 255=Cxff_Fehler, 254=Cxfe_IDLE_INIT; unit Unit_None}, range phys 0..253 Unit_None, raw 0..255, unit=Unit_None, transfer-property=PENDING  # Knotenadresse des Empfängers, 127(dez) ist "Broadcast", 128.....159 (dez) sind Gruppenadressen
          signal STRG100a_PrgDaten_speichern_XIX_ACTe_100a_Broadcast_Ctrl_XIX_Zone_VR_LIN11: start 8, 2 bit, little-endian, data-type-policy=OVERRIDE, i-signal-type=PRIMITIVE, init-value=0, base-type=BT_STRG100a_PrgDaten_speichern, invalid-value=Invalid_STRG100a_PrgDaten_speichern_XIX_ACTe_100a_Broadcast_Ctrl_XIX_Zone_VR_LIN11:3, compu {3=Cx3_Fehler, 2=Cx2_reserviert, 0=Cx0_nicht_speichern, 1=Cx1_speichern}, range raw 0..3, transfer-property=PENDING  # Speicherung der Programmierdaten
          signal STRG100a_Freig_Blockiererkennung_XIX_ACTe_100a_Broadcast_Ctrl_XIX_Zone_VR_LIN11: start 10, 2 bit, little-endian, data-type-policy=OVERRIDE, i-signal-type=PRIMITIVE, init-value=0, base-type=BT_STRG100a_Freig_Blockiererkennung, invalid-value=Invalid_STRG100a_Freig_Blockiererkennung_XIX_ACTe_100a_Broadcast_Ctrl_XIX_Zone_VR_LIN11:3, compu {3=Cx3_Fehler, 1=Cx1_Blockiererkennung_ein, 2=Cx2_reserviert, 0=Cx0_Blockiererkennung_aus}, range raw 0..3, transfer-property=PENDING  # Das Master-SG gibt eine aktive oder inaktive Blockiererkennung vor
          signal STRG100a_Clear_Event_Flags_XIX_ACTe_100a_Broadcast_Ctrl_XIX_Zone_VR_LIN11: start 12, 4 bit, little-endian, data-type-policy=OVERRIDE, i-signal-type=PRIMITIVE, init-value=0, base-type=BT_STRG100a_Clear_Event_Flags, invalid-value=Invalid_STRG100a_Clear_Event_Flags_XIX_ACTe_100a_Broadcast_Ctrl_XIX_Zone_VR_LIN11:15, compu {15=Cxf_Fehler, 6=Cx6_Clear_NL_BL, 8=Cx8_Clear_Reset, 10=Cxa_Clear_NL_Reset, 14=Cxe_Clear_NL_BL_Reset, 12=Cxc_Clear_BL_Reset, 0=Cx0_Event_Flags_nicht_zuruecksetzen, 2=Cx2_Clear_NL, 4=Cx4_Clear_BL}, range raw 0..15, transfer-property=PENDING  # Das Steuergerät löscht die Event-Flags NL: Notlauf aufgetreten, BL: Blockierung aufgetreten
          signal STRG100a_Spulenhaltebestromung_XIX_ACTe_100a_Broadcast_Ctrl_XIX_Zone_VR_LIN11: start 16, 2 bit, little-endian, data-type-policy=OVERRIDE, i-signal-type=PRIMITIVE, init-value=0, base-type=BT_STRG100a_Spulenhaltebestromung, invalid-value=Invalid_STRG100a_Spulenhaltebestromung_XIX_ACTe_100a_Broadcast_Ctrl_XIX_Zone_VR_LIN11:3, compu {3=Cx3_Fehler, 0=Cx0_Motorspulen_unbestromt, 2=Cx2_reserviert, 1=Cx1_Motorspulen_bestromt}, range raw 0..3, transfer-property=PENDING  # Vorgabe für die Spulenhaltebestromung im STOP-Mode
          signal STRG100a_Select_Positionsvorgabe_XIX_ACTe_100a_Broadcast_Ctrl_XIX_Zone_VR_LIN11: start 18, 2 bit, little-endian, data-type-policy=OVERRIDE, i-signal-type=PRIMITIVE, init-value=0, base-type=BT_STRG100a_Select_Positionsvorgabe, invalid-value=Invalid_STRG100a_Select_Positionsvorgabe_XIX_ACTe_100a_Broadcast_Ctrl_XIX_Zone_VR_LIN11:3, compu {3=Cx3_Fehler, 1=Cx1_Start_Position_gueltig, 0=Cx0_Soll_Position_gueltig, 2=Cx2_keine_Positionsvorgabe_gueltig}, range raw 0..3, transfer-property=PENDING  # Vorgabe der Gültigkeit der Positionsvorgaben
          signal STRG100a_Geschwindigkeitsvorgabe_XIX_ACTe_100a_Broadcast_Ctrl_XIX_Zone_VR_LIN11: start 20, 4 bit, little-endian, data-type-policy=OVERRIDE, i-signal-type=PRIMITIVE, init-value=0, base-type=BT_STRG100a_Geschwindigkeitsvorgabe, invalid-value=Invalid_STRG100a_Geschwindigkeitsvorgabe_XIX_ACTe_100a_Broadcast_Ctrl_XIX_Zone_VR_LIN11:15, compu {15=Cxf_Fehler, 0=Cx0_reserviert, 4=Cx4_Geschwindigkeitsstufe_4, 1=Cx1_Geschwindigkeitsstufe_1, 3=Cx3_Geschwindigkeitsstufe_3, 5=Cx5_Autospeed, 2=Cx2_Geschwindigkeitsstufe_2}, range raw 0..15, transfer-property=PENDING  # Vorgabe der Geschwindigkeitsstufe
          signal STRG100a_Soll_Position_XIX_ACTe_100a_Broadcast_Ctrl_XIX_Zone_VR_LIN11: start 24, 16 bit, little-endian, data-type-policy=OVERRIDE, i-signal-type=PRIMITIVE, init-value=0, base-type=BT_STRG100a_Soll_Position, invalid-value=Invalid_STRG100a_Soll_Position_XIX_ACTe_100a_Broadcast_Ctrl_XIX_Zone_VR_LIN11:65535, compu {phys=raw for raw 0..65534, 65535=Cxffff_Fehler; unit Unit_None}, range phys 0..65534 Unit_None, raw 0..65535, unit=Unit_None, transfer-property=PENDING  # Vorgabe der Sollposition
          signal STRG100a_Start_Position_XIX_ACTe_100a_Broadcast_Ctrl_XIX_Zone_VR_LIN11: start 40, 16 bit, little-endian, data-type-policy=OVERRIDE, i-signal-type=PRIMITIVE, init-value=0, base-type=BT_STRG100a_Start_Position, invalid-value=Invalid_STRG100a_Start_Position_XIX_ACTe_100a_Broadcast_Ctrl_XIX_Zone_VR_LIN11:65535, compu {phys=raw for raw 0..65534, 65535=Cxffff_Fehler; unit Unit_None}, range phys 0..65534 Unit_None, raw 0..65535, unit=Unit_None, transfer-property=PENDING  # Vorgabe der Startposition
          signal STRG100a_Notlauffreigabe_XIX_ACTe_100a_Broadcast_Ctrl_XIX_Zone_VR_LIN11: start 56, 2 bit, little-endian, data-type-policy=OVERRIDE, i-signal-type=PRIMITIVE, init-value=0, base-type=BT_STRG100a_Notlauffreigabe, invalid-value=Invalid_STRG100a_Notlauffreigabe_XIX_ACTe_100a_Broadcast_Ctrl_XIX_Zone_VR_LIN11:3, compu {3=Cx3_Fehler, 1=Cx1_Notlauf_ein, 2=Cx2_reserviert, 0=Cx0_Notlauf_aus}, range raw 0..3, transfer-property=PENDING  # Freigabe des Notlaufs
          signal STRG100a_Notlaufposition_XIX_ACTe_100a_Broadcast_Ctrl_XIX_Zone_VR_LIN11: start 58, 2 bit, little-endian, data-type-policy=OVERRIDE, i-signal-type=PRIMITIVE, init-value=0, base-type=BT_STRG100a_Notlaufposition, invalid-value=Invalid_STRG100a_Notlaufposition_XIX_ACTe_100a_Broadcast_Ctrl_XIX_Zone_VR_LIN11:3, compu {3=Cx3_Fehler, 2=Cx2_reserviert, 0=Cx0_unterer_Anschlag, 1=Cx1_oberer_Anschlag}, range raw 0..3, transfer-property=PENDING  # Positionsvorgabe, welche bei aktiven Notlauf angelaufen wird
          signal STRG100a_Drehrichtung_XIX_ACTe_100a_Broadcast_Ctrl_XIX_Zone_VR_LIN11: start 60, 2 bit, little-endian, data-type-policy=OVERRIDE, i-signal-type=PRIMITIVE, init-value=0, base-type=BT_STRG100a_Drehrichtung, invalid-value=Invalid_STRG100a_Drehrichtung_XIX_ACTe_100a_Broadcast_Ctrl_XIX_Zone_VR_LIN11:3, compu {3=Cx3_Fehler, 1=Cx1_Bewegung_in_Richtung_CCW, 0=Cx0_Bewegung_in_Richtung_CW, 2=Cx2_reserviert}, range raw 0..3, transfer-property=PENDING  # Vorgabe der Drehrichtung
          signal STRG100a_Stopmodus_XIX_ACTe_100a_Broadcast_Ctrl_XIX_Zone_VR_LIN11: start 62, 2 bit, little-endian, data-type-policy=OVERRIDE, i-signal-type=PRIMITIVE, init-value=0, base-type=BT_STRG100a_Stopmodus, invalid-value=Invalid_STRG100a_Stopmodus_XIX_ACTe_100a_Broadcast_Ctrl_XIX_Zone_VR_LIN11:3, compu {3=Cx3_Fehler, 2=Cx2_Status_Adresse_als_Gruppenadr, 0=Cx0_normal_mode, 1=Cx1_stop_mode}, range raw 0..3, transfer-property=PENDING  # Vorgabe des StopModus
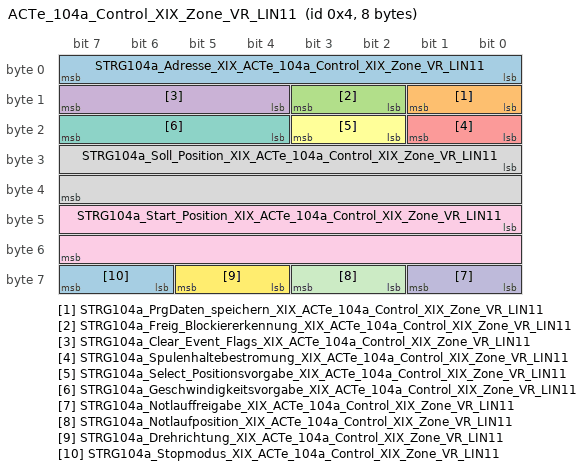
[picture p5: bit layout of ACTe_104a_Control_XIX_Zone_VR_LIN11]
      frame ACTe_104a_Control_XIX_Zone_VR_LIN11: id 0x4, from Zone_VR, frame-length=8, lin-checksum=ENHANCED
        pdu ACTe_104a_Control_XIX_Zone_VR_LIN11: length=8, unused-bit-pattern=0
          signal STRG104a_Adresse_XIX_ACTe_104a_Control_XIX_Zone_VR_LIN11: start 0, 8 bit, little-endian, data-type-policy=OVERRIDE, i-signal-type=PRIMITIVE, init-value=254, base-type=BT_STRG104a_Adresse, invalid-value=Invalid_STRG104a_Adresse_XIX_ACTe_104a_Control_XIX_Zone_VR_LIN11:255, compu {phys=raw for raw 0..253, 255=Cxff_Fehler, 254=Cxfe_IDLE_INIT; unit Unit_None}, range phys 0..253 Unit_None, raw 0..255, unit=Unit_None, transfer-property=PENDING  # Knotenadresse des Empfängers, 127(dez) ist "Broadcast", 128.....159 (dez) sind Gruppenadressen
          signal STRG104a_PrgDaten_speichern_XIX_ACTe_104a_Control_XIX_Zone_VR_LIN11: start 8, 2 bit, little-endian, data-type-policy=OVERRIDE, i-signal-type=PRIMITIVE, init-value=0, base-type=BT_STRG104a_PrgDaten_speichern, compu {0=Cx0_nicht_speichern, 2=Cx2_reserviert, 1=Cx1_speichern}, range raw 0..2, transfer-property=PENDING  # Speicherung der Programmierdaten
          signal STRG104a_Freig_Blockiererkennung_XIX_ACTe_104a_Control_XIX_Zone_VR_LIN11: start 10, 2 bit, little-endian, data-type-policy=OVERRIDE, i-signal-type=PRIMITIVE, init-value=0, base-type=BT_STRG104a_Freig_Blockiererkennung, compu {1=Cx1_Blockiererkennung_ein, 2=Cx2_reserviert, 0=Cx0_Blockiererkennung_aus}, range raw 0..2, transfer-property=PENDING  # Das Master-SG gibt eine aktive oder inaktive Blockiererkennung vor
          signal STRG104a_Clear_Event_Flags_XIX_ACTe_104a_Control_XIX_Zone_VR_LIN11: start 12, 4 bit, little-endian, data-type-policy=OVERRIDE, i-signal-type=PRIMITIVE, init-value=0, base-type=BT_STRG104a_Clear_Event_Flags, compu {0=Cx0_Event_Flags_nicht_zuruecksetzen, 4=Cx4_Clear_BL, 12=Cxc_Clear_BL_Reset, 10=Cxa_Clear_NL_Reset, 2=Cx2_Clear_NL, 14=Cxe_Clear_NL_BL_Reset, 6=Cx6_Clear_NL_BL, 8=Cx8_Clear_Reset}, range raw 0..14, transfer-property=PENDING  # Das Steuergerät löscht die Event-Flags NL: Notlauf aufgetreten, BL: Blockierung aufgetreten
          signal STRG104a_Spulenhaltebestromung_XIX_ACTe_104a_Control_XIX_Zone_VR_LIN11: start 16, 2 bit, little-endian, data-type-policy=OVERRIDE, i-signal-type=PRIMITIVE, init-value=0, base-type=BT_STRG104a_Spulenhaltebestromung, compu {1=Cx1_Motorspulen_bestromt, 2=Cx2_reserviert, 0=Cx0_Motorspulen_unbestromt}, range raw 0..2, transfer-property=PENDING  # Vorgabe für die Spulenhaltebestromung im STOP-Mode
          signal STRG104a_Select_Positionsvorgabe_XIX_ACTe_104a_Control_XIX_Zone_VR_LIN11: start 18, 2 bit, little-endian, data-type-policy=OVERRIDE, i-signal-type=PRIMITIVE, init-value=0, base-type=BT_STRG104a_Select_Positionsvorgabe, compu {2=Cx2_keine_Positionsvorgabe_gueltig, 1=Cx1_Start_Position_gueltig, 0=Cx0_Soll_Position_gueltig}, range raw 0..2, transfer-property=PENDING  # Vorgabe der Gültigkeit der Positionsvorgaben
          signal STRG104a_Geschwindigkeitsvorgabe_XIX_ACTe_104a_Control_XIX_Zone_VR_LIN11: start 20, 4 bit, little-endian, data-type-policy=OVERRIDE, i-signal-type=PRIMITIVE, init-value=0, base-type=BT_STRG104a_Geschwindigkeitsvorgabe, compu {0=Cx0_reserviert, 2=Cx2_Geschwindigkeitsstufe_2, 1=Cx1_Geschwindigkeitsstufe_1, 3=Cx3_Geschwindigkeitsstufe_3, 5=Cx5_Autospeed, 4=Cx4_Geschwindigkeitsstufe_4}, range raw 0..5, transfer-property=PENDING  # Vorgabe der Geschwindigkeitsstufe
          signal STRG104a_Soll_Position_XIX_ACTe_104a_Control_XIX_Zone_VR_LIN11: start 24, 16 bit, little-endian, data-type-policy=OVERRIDE, i-signal-type=PRIMITIVE, init-value=0, base-type=BT_STRG104a_Soll_Position, compu {phys=raw for raw 0..65534; unit Unit_None}, range phys 0..65534 Unit_None, raw 0..65534, unit=Unit_None, transfer-property=PENDING  # Vorgabe der Sollposition
          signal STRG104a_Start_Position_XIX_ACTe_104a_Control_XIX_Zone_VR_LIN11: start 40, 16 bit, little-endian, data-type-policy=OVERRIDE, i-signal-type=PRIMITIVE, init-value=0, base-type=BT_STRG104a_Start_Position, compu {phys=raw for raw 0..65534; unit Unit_None}, range phys 0..65534 Unit_None, raw 0..65534, unit=Unit_None, transfer-property=PENDING  # Vorgabe der Startposition
          signal STRG104a_Notlauffreigabe_XIX_ACTe_104a_Control_XIX_Zone_VR_LIN11: start 56, 2 bit, little-endian, data-type-policy=OVERRIDE, i-signal-type=PRIMITIVE, init-value=0, base-type=BT_STRG104a_Notlauffreigabe, compu {1=Cx1_Notlauf_ein, 0=Cx0_Notlauf_aus, 2=Cx2_reserviert}, range raw 0..2, transfer-property=PENDING  # Freigabe des Notlaufs
          signal STRG104a_Notlaufposition_XIX_ACTe_104a_Control_XIX_Zone_VR_LIN11: start 58, 2 bit, little-endian, data-type-policy=OVERRIDE, i-signal-type=PRIMITIVE, init-value=0, base-type=BT_STRG104a_Notlaufposition, compu {0=Cx0_unterer_Anschlag, 2=Cx2_reserviert, 1=Cx1_oberer_Anschlag}, range raw 0..2, transfer-property=PENDING  # Positionsvorgabe, welche bei aktiven Notlauf angelaufen wird
          signal STRG104a_Drehrichtung_XIX_ACTe_104a_Control_XIX_Zone_VR_LIN11: start 60, 2 bit, little-endian, data-type-policy=OVERRIDE, i-signal-type=PRIMITIVE, init-value=0, base-type=BT_STRG104a_Drehrichtung, compu {2=Cx2_reserviert, 1=Cx1_Bewegung_in_Richtung_CCW, 0=Cx0_Bewegung_in_Richtung_CW}, range raw 0..2, transfer-property=PENDING  # Vorgabe der Drehrichtung
          signal STRG104a_Stopmodus_XIX_ACTe_104a_Control_XIX_Zone_VR_LIN11: start 62, 2 bit, little-endian, data-type-policy=OVERRIDE, i-signal-type=PRIMITIVE, init-value=0, base-type=BT_STRG104a_Stopmodus, compu {0=Cx0_normal_mode, 2=Cx2_Status_Adresse_als_Gruppenadr, 1=Cx1_stop_mode}, range raw 0..2, transfer-property=PENDING  # Vorgabe des StopModus
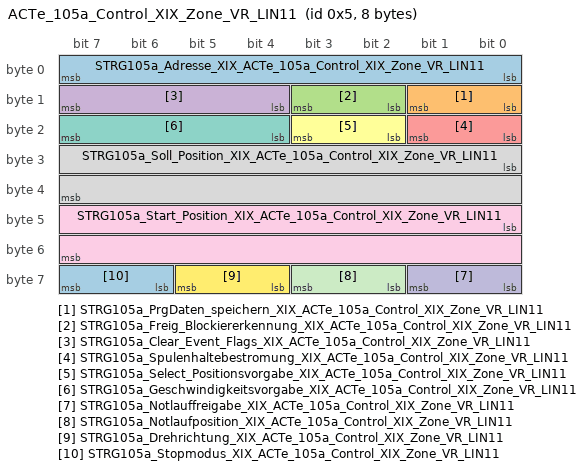
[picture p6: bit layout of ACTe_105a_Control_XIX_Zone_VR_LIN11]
      frame ACTe_105a_Control_XIX_Zone_VR_LIN11: id 0x5, from Zone_VR, frame-length=8, lin-checksum=ENHANCED
        pdu ACTe_105a_Control_XIX_Zone_VR_LIN11: length=8, unused-bit-pattern=0
          signal STRG105a_Adresse_XIX_ACTe_105a_Control_XIX_Zone_VR_LIN11: start 0, 8 bit, little-endian, data-type-policy=OVERRIDE, i-signal-type=PRIMITIVE, init-value=254, base-type=BT_STRG105a_Adresse, invalid-value=Invalid_STRG105a_Adresse_XIX_ACTe_105a_Control_XIX_Zone_VR_LIN11:255, compu {phys=raw for raw 0..253, 255=Cxff_Fehler, 254=Cxfe_IDLE_INIT; unit Unit_None}, range phys 0..253 Unit_None, raw 0..255, unit=Unit_None, transfer-property=PENDING  # Knotenadresse des Empfängers, 127(dez) ist "Broadcast", 128.....159 (dez) sind Gruppenadressen
          signal STRG105a_PrgDaten_speichern_XIX_ACTe_105a_Control_XIX_Zone_VR_LIN11: start 8, 2 bit, little-endian, data-type-policy=OVERRIDE, i-signal-type=PRIMITIVE, init-value=0, base-type=BT_STRG105a_PrgDaten_speichern, compu {2=Cx2_reserviert, 0=Cx0_nicht_speichern, 1=Cx1_speichern}, range raw 0..2, transfer-property=PENDING  # Speicherung der Programmierdaten
          signal STRG105a_Freig_Blockiererkennung_XIX_ACTe_105a_Control_XIX_Zone_VR_LIN11: start 10, 2 bit, little-endian, data-type-policy=OVERRIDE, i-signal-type=PRIMITIVE, init-value=0, base-type=BT_STRG105a_Freig_Blockiererkennung, compu {0=Cx0_Blockiererkennung_aus, 1=Cx1_Blockiererkennung_ein, 2=Cx2_reserviert}, range raw 0..2, transfer-property=PENDING  # Das Master-SG gibt eine aktive oder inaktive Blockiererkennung vor
          signal STRG105a_Clear_Event_Flags_XIX_ACTe_105a_Control_XIX_Zone_VR_LIN11: start 12, 4 bit, little-endian, data-type-policy=OVERRIDE, i-signal-type=PRIMITIVE, init-value=0, base-type=BT_STRG105a_Clear_Event_Flags, compu {14=Cxe_Clear_NL_BL_Reset, 2=Cx2_Clear_NL, 6=Cx6_Clear_NL_BL, 10=Cxa_Clear_NL_Reset, 12=Cxc_Clear_BL_Reset, 4=Cx4_Clear_BL, 0=Cx0_Event_Flags_nicht_zuruecksetzen, 8=Cx8_Clear_Reset}, range raw 0..14, transfer-property=PENDING  # Das Steuergerät löscht die Event-Flags NL: Notlauf aufgetreten, BL: Blockierung aufgetreten
          signal STRG105a_Spulenhaltebestromung_XIX_ACTe_105a_Control_XIX_Zone_VR_LIN11: start 16, 2 bit, little-endian, data-type-policy=OVERRIDE, i-signal-type=PRIMITIVE, init-value=0, base-type=BT_STRG105a_Spulenhaltebestromung, compu {0=Cx0_Motorspulen_unbestromt, 1=Cx1_Motorspulen_bestromt, 2=Cx2_reserviert}, range raw 0..2, transfer-property=PENDING  # Vorgabe für die Spulenhaltebestromung im STOP-Mode
          signal STRG105a_Select_Positionsvorgabe_XIX_ACTe_105a_Control_XIX_Zone_VR_LIN11: start 18, 2 bit, little-endian, data-type-policy=OVERRIDE, i-signal-type=PRIMITIVE, init-value=0, base-type=BT_STRG105a_Select_Positionsvorgabe, compu {0=Cx0_Soll_Position_gueltig, 2=Cx2_keine_Positionsvorgabe_gueltig, 1=Cx1_Start_Position_gueltig}, range raw 0..2, transfer-property=PENDING  # Vorgabe der Gültigkeit der Positionsvorgaben
          signal STRG105a_Geschwindigkeitsvorgabe_XIX_ACTe_105a_Control_XIX_Zone_VR_LIN11: start 20, 4 bit, little-endian, data-type-policy=OVERRIDE, i-signal-type=PRIMITIVE, init-value=0, base-type=BT_STRG105a_Geschwindigkeitsvorgabe, compu {0=Cx0_reserviert, 5=Cx5_Autospeed, 4=Cx4_Geschwindigkeitsstufe_4, 2=Cx2_Geschwindigkeitsstufe_2, 1=Cx1_Geschwindigkeitsstufe_1, 3=Cx3_Geschwindigkeitsstufe_3}, range raw 0..5, transfer-property=PENDING  # Vorgabe der Geschwindigkeitsstufe
          signal STRG105a_Soll_Position_XIX_ACTe_105a_Control_XIX_Zone_VR_LIN11: start 24, 16 bit, little-endian, data-type-policy=OVERRIDE, i-signal-type=PRIMITIVE, init-value=0, base-type=BT_STRG105a_Soll_Position, compu {phys=raw for raw 0..65534; unit Unit_None}, range phys 0..65534 Unit_None, raw 0..65534, unit=Unit_None, transfer-property=PENDING  # Vorgabe der Sollposition
          signal STRG105a_Start_Position_XIX_ACTe_105a_Control_XIX_Zone_VR_LIN11: start 40, 16 bit, little-endian, data-type-policy=OVERRIDE, i-signal-type=PRIMITIVE, init-value=0, base-type=BT_STRG105a_Start_Position, compu {phys=raw for raw 0..65534; unit Unit_None}, range phys 0..65534 Unit_None, raw 0..65534, unit=Unit_None, transfer-property=PENDING  # Vorgabe der Startposition
          signal STRG105a_Notlauffreigabe_XIX_ACTe_105a_Control_XIX_Zone_VR_LIN11: start 56, 2 bit, little-endian, data-type-policy=OVERRIDE, i-signal-type=PRIMITIVE, init-value=0, base-type=BT_STRG105a_Notlauffreigabe, compu {1=Cx1_Notlauf_ein, 2=Cx2_reserviert, 0=Cx0_Notlauf_aus}, range raw 0..2, transfer-property=PENDING  # Freigabe des Notlaufs
          signal STRG105a_Notlaufposition_XIX_ACTe_105a_Control_XIX_Zone_VR_LIN11: start 58, 2 bit, little-endian, data-type-policy=OVERRIDE, i-signal-type=PRIMITIVE, init-value=0, base-type=BT_STRG105a_Notlaufposition, compu {1=Cx1_oberer_Anschlag, 0=Cx0_unterer_Anschlag, 2=Cx2_reserviert}, range raw 0..2, transfer-property=PENDING  # Positionsvorgabe, welche bei aktiven Notlauf angelaufen wird
          signal STRG105a_Drehrichtung_XIX_ACTe_105a_Control_XIX_Zone_VR_LIN11: start 60, 2 bit, little-endian, data-type-policy=OVERRIDE, i-signal-type=PRIMITIVE, init-value=0, base-type=BT_STRG105a_Drehrichtung, compu {0=Cx0_Bewegung_in_Richtung_CW, 2=Cx2_reserviert, 1=Cx1_Bewegung_in_Richtung_CCW}, range raw 0..2, transfer-property=PENDING  # Vorgabe der Drehrichtung
          signal STRG105a_Stopmodus_XIX_ACTe_105a_Control_XIX_Zone_VR_LIN11: start 62, 2 bit, little-endian, data-type-policy=OVERRIDE, i-signal-type=PRIMITIVE, init-value=0, base-type=BT_STRG105a_Stopmodus, compu {1=Cx1_stop_mode, 0=Cx0_normal_mode, 2=Cx2_Status_Adresse_als_Gruppenadr}, range raw 0..2, transfer-property=PENDING  # Vorgabe des StopModus
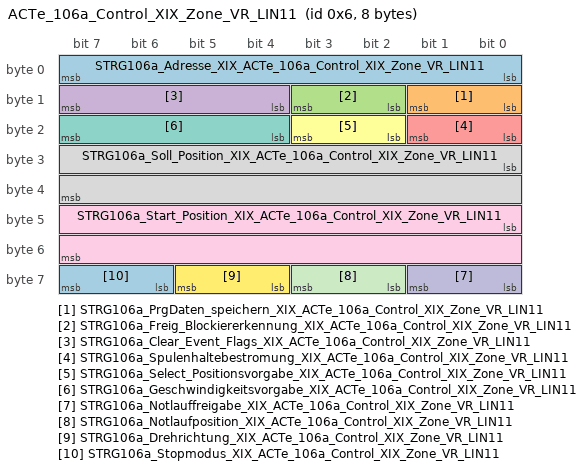
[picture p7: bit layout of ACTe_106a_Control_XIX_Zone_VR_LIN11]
      frame ACTe_106a_Control_XIX_Zone_VR_LIN11: id 0x6, from Zone_VR, frame-length=8, lin-checksum=ENHANCED
        pdu ACTe_106a_Control_XIX_Zone_VR_LIN11: length=8, unused-bit-pattern=0
          signal STRG106a_Adresse_XIX_ACTe_106a_Control_XIX_Zone_VR_LIN11: start 0, 8 bit, little-endian, data-type-policy=OVERRIDE, i-signal-type=PRIMITIVE, init-value=254, base-type=BT_STRG106a_Adresse, invalid-value=Invalid_STRG106a_Adresse_XIX_ACTe_106a_Control_XIX_Zone_VR_LIN11:255, compu {phys=raw for raw 0..253, 255=Cxff_Fehler, 254=Cxfe_IDLE_INIT; unit Unit_None}, range phys 0..253 Unit_None, raw 0..255, unit=Unit_None, transfer-property=PENDING  # Knotenadresse des Empfängers, 127(dez) ist "Broadcast", 128.....159 (dez) sind Gruppenadressen
          signal STRG106a_PrgDaten_speichern_XIX_ACTe_106a_Control_XIX_Zone_VR_LIN11: start 8, 2 bit, little-endian, data-type-policy=OVERRIDE, i-signal-type=PRIMITIVE, init-value=0, base-type=BT_STRG106a_PrgDaten_speichern, compu {2=Cx2_reserviert, 0=Cx0_nicht_speichern, 1=Cx1_speichern}, range raw 0..2, transfer-property=PENDING  # Speicherung der Programmierdaten
          signal STRG106a_Freig_Blockiererkennung_XIX_ACTe_106a_Control_XIX_Zone_VR_LIN11: start 10, 2 bit, little-endian, data-type-policy=OVERRIDE, i-signal-type=PRIMITIVE, init-value=0, base-type=BT_STRG106a_Freig_Blockiererkennung, compu {2=Cx2_reserviert, 0=Cx0_Blockiererkennung_aus, 1=Cx1_Blockiererkennung_ein}, range raw 0..2, transfer-property=PENDING  # Das Master-SG gibt eine aktive oder inaktive Blockiererkennung vor
          signal STRG106a_Clear_Event_Flags_XIX_ACTe_106a_Control_XIX_Zone_VR_LIN11: start 12, 4 bit, little-endian, data-type-policy=OVERRIDE, i-signal-type=PRIMITIVE, init-value=0, base-type=BT_STRG106a_Clear_Event_Flags, compu {2=Cx2_Clear_NL, 10=Cxa_Clear_NL_Reset, 8=Cx8_Clear_Reset, 14=Cxe_Clear_NL_BL_Reset, 12=Cxc_Clear_BL_Reset, 6=Cx6_Clear_NL_BL, 4=Cx4_Clear_BL, 0=Cx0_Event_Flags_nicht_zuruecksetzen}, range raw 0..14, transfer-property=PENDING  # Das Steuergerät löscht die Event-Flags NL: Notlauf aufgetreten, BL: Blockierung aufgetreten
          signal STRG106a_Spulenhaltebestromung_XIX_ACTe_106a_Control_XIX_Zone_VR_LIN11: start 16, 2 bit, little-endian, data-type-policy=OVERRIDE, i-signal-type=PRIMITIVE, init-value=0, base-type=BT_STRG106a_Spulenhaltebestromung, compu {1=Cx1_Motorspulen_bestromt, 0=Cx0_Motorspulen_unbestromt, 2=Cx2_reserviert}, range raw 0..2, transfer-property=PENDING  # Vorgabe für die Spulenhaltebestromung im STOP-Mode
          signal STRG106a_Select_Positionsvorgabe_XIX_ACTe_106a_Control_XIX_Zone_VR_LIN11: start 18, 2 bit, little-endian, data-type-policy=OVERRIDE, i-signal-type=PRIMITIVE, init-value=0, base-type=BT_STRG106a_Select_Positionsvorgabe, compu {1=Cx1_Start_Position_gueltig, 0=Cx0_Soll_Position_gueltig, 2=Cx2_keine_Positionsvorgabe_gueltig}, range raw 0..2, transfer-property=PENDING  # Vorgabe der Gültigkeit der Positionsvorgaben
          signal STRG106a_Geschwindigkeitsvorgabe_XIX_ACTe_106a_Control_XIX_Zone_VR_LIN11: start 20, 4 bit, little-endian, data-type-policy=OVERRIDE, i-signal-type=PRIMITIVE, init-value=0, base-type=BT_STRG106a_Geschwindigkeitsvorgabe, compu {3=Cx3_Geschwindigkeitsstufe_3, 5=Cx5_Autospeed, 0=Cx0_reserviert, 4=Cx4_Geschwindigkeitsstufe_4, 1=Cx1_Geschwindigkeitsstufe_1, 2=Cx2_Geschwindigkeitsstufe_2}, range raw 0..5, transfer-property=PENDING  # Vorgabe der Geschwindigkeitsstufe
          signal STRG106a_Soll_Position_XIX_ACTe_106a_Control_XIX_Zone_VR_LIN11: start 24, 16 bit, little-endian, data-type-policy=OVERRIDE, i-signal-type=PRIMITIVE, init-value=0, base-type=BT_STRG106a_Soll_Position, compu {phys=raw for raw 0..65534; unit Unit_None}, range phys 0..65534 Unit_None, raw 0..65534, unit=Unit_None, transfer-property=PENDING  # Vorgabe der Sollposition
          signal STRG106a_Start_Position_XIX_ACTe_106a_Control_XIX_Zone_VR_LIN11: start 40, 16 bit, little-endian, data-type-policy=OVERRIDE, i-signal-type=PRIMITIVE, init-value=0, base-type=BT_STRG106a_Start_Position, compu {phys=raw for raw 0..65534; unit Unit_None}, range phys 0..65534 Unit_None, raw 0..65534, unit=Unit_None, transfer-property=PENDING  # Vorgabe der Startposition
          signal STRG106a_Notlauffreigabe_XIX_ACTe_106a_Control_XIX_Zone_VR_LIN11: start 56, 2 bit, little-endian, data-type-policy=OVERRIDE, i-signal-type=PRIMITIVE, init-value=0, base-type=BT_STRG106a_Notlauffreigabe, compu {1=Cx1_Notlauf_ein, 0=Cx0_Notlauf_aus, 2=Cx2_reserviert}, range raw 0..2, transfer-property=PENDING  # Freigabe des Notlaufs
          signal STRG106a_Notlaufposition_XIX_ACTe_106a_Control_XIX_Zone_VR_LIN11: start 58, 2 bit, little-endian, data-type-policy=OVERRIDE, i-signal-type=PRIMITIVE, init-value=0, base-type=BT_STRG106a_Notlaufposition, compu {0=Cx0_unterer_Anschlag, 1=Cx1_oberer_Anschlag, 2=Cx2_reserviert}, range raw 0..2, transfer-property=PENDING  # Positionsvorgabe, welche bei aktiven Notlauf angelaufen wird
          signal STRG106a_Drehrichtung_XIX_ACTe_106a_Control_XIX_Zone_VR_LIN11: start 60, 2 bit, little-endian, data-type-policy=OVERRIDE, i-signal-type=PRIMITIVE, init-value=0, base-type=BT_STRG106a_Drehrichtung, compu {1=Cx1_Bewegung_in_Richtung_CCW, 2=Cx2_reserviert, 0=Cx0_Bewegung_in_Richtung_CW}, range raw 0..2, transfer-property=PENDING  # Vorgabe der Drehrichtung
          signal STRG106a_Stopmodus_XIX_ACTe_106a_Control_XIX_Zone_VR_LIN11: start 62, 2 bit, little-endian, data-type-policy=OVERRIDE, i-signal-type=PRIMITIVE, init-value=0, base-type=BT_STRG106a_Stopmodus, compu {0=Cx0_normal_mode, 2=Cx2_Status_Adresse_als_Gruppenadr, 1=Cx1_stop_mode}, range raw 0..2, transfer-property=PENDING  # Vorgabe des StopModus
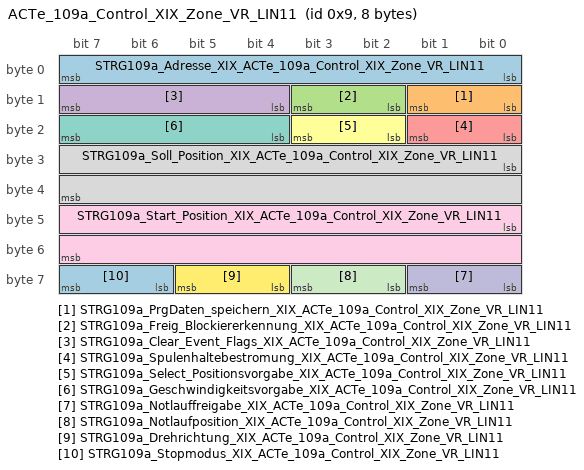
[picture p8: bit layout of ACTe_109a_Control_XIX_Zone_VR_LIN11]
      frame ACTe_109a_Control_XIX_Zone_VR_LIN11: id 0x9, from Zone_VR, frame-length=8, lin-checksum=ENHANCED
        pdu ACTe_109a_Control_XIX_Zone_VR_LIN11: length=8, unused-bit-pattern=0
          signal STRG109a_Adresse_XIX_ACTe_109a_Control_XIX_Zone_VR_LIN11: start 0, 8 bit, little-endian, data-type-policy=OVERRIDE, i-signal-type=PRIMITIVE, init-value=254, base-type=BT_STRG109a_Adresse, invalid-value=Invalid_STRG109a_Adresse_XIX_ACTe_109a_Control_XIX_Zone_VR_LIN11:255, compu {phys=raw for raw 0..253, 255=Cxff_Fehler, 254=Cxfe_IDLE_INIT; unit Unit_None}, range phys 0..253 Unit_None, raw 0..255, unit=Unit_None, transfer-property=PENDING  # Knotenadresse des Empfängers, 127(dez) ist "Broadcast", 128.....159 (dez) sind Gruppenadressen
          signal STRG109a_PrgDaten_speichern_XIX_ACTe_109a_Control_XIX_Zone_VR_LIN11: start 8, 2 bit, little-endian, data-type-policy=OVERRIDE, i-signal-type=PRIMITIVE, init-value=0, base-type=BT_STRG109a_PrgDaten_speichern, compu {2=Cx2_reserviert, 1=Cx1_speichern, 0=Cx0_nicht_speichern}, range raw 0..2, transfer-property=PENDING  # Speicherung der Programmierdaten
          signal STRG109a_Freig_Blockiererkennung_XIX_ACTe_109a_Control_XIX_Zone_VR_LIN11: start 10, 2 bit, little-endian, data-type-policy=OVERRIDE, i-signal-type=PRIMITIVE, init-value=0, base-type=BT_STRG109a_Freig_Blockiererkennung, compu {1=Cx1_Blockiererkennung_ein, 2=Cx2_reserviert, 0=Cx0_Blockiererkennung_aus}, range raw 0..2, transfer-property=PENDING  # Das Master-SG gibt eine aktive oder inaktive Blockiererkennung vor
          signal STRG109a_Clear_Event_Flags_XIX_ACTe_109a_Control_XIX_Zone_VR_LIN11: start 12, 4 bit, little-endian, data-type-policy=OVERRIDE, i-signal-type=PRIMITIVE, init-value=0, base-type=BT_STRG109a_Clear_Event_Flags, compu {8=Cx8_Clear_Reset, 0=Cx0_Event_Flags_nicht_zuruecksetzen, 2=Cx2_Clear_NL, 4=Cx4_Clear_BL, 12=Cxc_Clear_BL_Reset, 14=Cxe_Clear_NL_BL_Reset, 10=Cxa_Clear_NL_Reset, 6=Cx6_Clear_NL_BL}, range raw 0..14, transfer-property=PENDING  # Das Steuergerät löscht die Event-Flags NL: Notlauf aufgetreten, BL: Blockierung aufgetreten
          signal STRG109a_Spulenhaltebestromung_XIX_ACTe_109a_Control_XIX_Zone_VR_LIN11: start 16, 2 bit, little-endian, data-type-policy=OVERRIDE, i-signal-type=PRIMITIVE, init-value=0, base-type=BT_STRG109a_Spulenhaltebestromung, compu {1=Cx1_Motorspulen_bestromt, 2=Cx2_reserviert, 0=Cx0_Motorspulen_unbestromt}, range raw 0..2, transfer-property=PENDING  # Vorgabe für die Spulenhaltebestromung im STOP-Mode
          signal STRG109a_Select_Positionsvorgabe_XIX_ACTe_109a_Control_XIX_Zone_VR_LIN11: start 18, 2 bit, little-endian, data-type-policy=OVERRIDE, i-signal-type=PRIMITIVE, init-value=0, base-type=BT_STRG109a_Select_Positionsvorgabe, compu {2=Cx2_keine_Positionsvorgabe_gueltig, 0=Cx0_Soll_Position_gueltig, 1=Cx1_Start_Position_gueltig}, range raw 0..2, transfer-property=PENDING  # Vorgabe der Gültigkeit der Positionsvorgaben
          signal STRG109a_Geschwindigkeitsvorgabe_XIX_ACTe_109a_Control_XIX_Zone_VR_LIN11: start 20, 4 bit, little-endian, data-type-policy=OVERRIDE, i-signal-type=PRIMITIVE, init-value=0, base-type=BT_STRG109a_Geschwindigkeitsvorgabe, compu {1=Cx1_Geschwindigkeitsstufe_1, 3=Cx3_Geschwindigkeitsstufe_3, 5=Cx5_Autospeed, 0=Cx0_reserviert, 2=Cx2_Geschwindigkeitsstufe_2, 4=Cx4_Geschwindigkeitsstufe_4}, range raw 0..5, transfer-property=PENDING  # Vorgabe der Geschwindigkeitsstufe
          signal STRG109a_Soll_Position_XIX_ACTe_109a_Control_XIX_Zone_VR_LIN11: start 24, 16 bit, little-endian, data-type-policy=OVERRIDE, i-signal-type=PRIMITIVE, init-value=0, base-type=BT_STRG109a_Soll_Position, compu {phys=raw for raw 0..65534; unit Unit_None}, range phys 0..65534 Unit_None, raw 0..65534, unit=Unit_None, transfer-property=PENDING  # Vorgabe der Sollposition
          signal STRG109a_Start_Position_XIX_ACTe_109a_Control_XIX_Zone_VR_LIN11: start 40, 16 bit, little-endian, data-type-policy=OVERRIDE, i-signal-type=PRIMITIVE, init-value=0, base-type=BT_STRG109a_Start_Position, compu {phys=raw for raw 0..65534; unit Unit_None}, range phys 0..65534 Unit_None, raw 0..65534, unit=Unit_None, transfer-property=PENDING  # Vorgabe der Startposition
          signal STRG109a_Notlauffreigabe_XIX_ACTe_109a_Control_XIX_Zone_VR_LIN11: start 56, 2 bit, little-endian, data-type-policy=OVERRIDE, i-signal-type=PRIMITIVE, init-value=0, base-type=BT_STRG109a_Notlauffreigabe, compu {2=Cx2_reserviert, 0=Cx0_Notlauf_aus, 1=Cx1_Notlauf_ein}, range raw 0..2, transfer-property=PENDING  # Freigabe des Notlaufs
          signal STRG109a_Notlaufposition_XIX_ACTe_109a_Control_XIX_Zone_VR_LIN11: start 58, 2 bit, little-endian, data-type-policy=OVERRIDE, i-signal-type=PRIMITIVE, init-value=0, base-type=BT_STRG109a_Notlaufposition, compu {2=Cx2_reserviert, 0=Cx0_unterer_Anschlag, 1=Cx1_oberer_Anschlag}, range raw 0..2, transfer-property=PENDING  # Positionsvorgabe, welche bei aktiven Notlauf angelaufen wird
          signal STRG109a_Drehrichtung_XIX_ACTe_109a_Control_XIX_Zone_VR_LIN11: start 60, 2 bit, little-endian, data-type-policy=OVERRIDE, i-signal-type=PRIMITIVE, init-value=0, base-type=BT_STRG109a_Drehrichtung, compu {1=Cx1_Bewegung_in_Richtung_CCW, 2=Cx2_reserviert, 0=Cx0_Bewegung_in_Richtung_CW}, range raw 0..2, transfer-property=PENDING  # Vorgabe der Drehrichtung
          signal STRG109a_Stopmodus_XIX_ACTe_109a_Control_XIX_Zone_VR_LIN11: start 62, 2 bit, little-endian, data-type-policy=OVERRIDE, i-signal-type=PRIMITIVE, init-value=0, base-type=BT_STRG109a_Stopmodus, compu {2=Cx2_Status_Adresse_als_Gruppenadr, 0=Cx0_normal_mode, 1=Cx1_stop_mode}, range raw 0..2, transfer-property=PENDING  # Vorgabe des StopModus
      frame ACTs_104a_Status_XIX_Zone_VR_LIN11: id 0x1B, to Zone_VR, frame-length=8, lin-checksum=ENHANCED
        pdu ACTs_104a_Status_XIX_Zone_VR_LIN11: length=8, unused-bit-pattern=0
          signal ACT104a_ResponseError_XIX_ACTs_104a_Status_XIX_Zone_VR_LIN11: start 0, 1 bit, little-endian, data-type-policy=OVERRIDE, i-signal-type=PRIMITIVE, init-value=0, base-type=BT_ACT104a_ResponseError, invalid-value=Invalid_ACT104a_ResponseError_XIX_ACTs_104a_Status_XIX_Zone_VR_LIN11:1, compu {1=Cx1_Fehler, 0=Cx0_normal}, range raw 0..1, transfer-property=PENDING  # siehe LIN2.0-Specification (Darf nicht über ein Fehlergueltigkeitsbit abgesichtert werden!)
          signal ACT104a_Uebertemperatur_XIX_ACTs_104a_Status_XIX_Zone_VR_LIN11: start 2, 2 bit, little-endian, data-type-policy=OVERRIDE, i-signal-type=PRIMITIVE, init-value=0, base-type=BT_ACT104a_Uebertemperatur, invalid-value=Invalid_ACT104a_Uebertemperatur_XIX_ACTs_104a_Status_XIX_Zone_VR_LIN11:3, compu {3=Cx3_Fehler, 2=Cx2_reserviert, 0=Cx0_keine_Uebertemperatur, 1=Cx1_Uebertemperatur}, range raw 0..3, transfer-property=PENDING, to Zone_VR(timeout 3.5 s)  # Anzeige einer Übertemperatur im Stellmotoren-ASIC
          signal ACT104a_el_Defekt_XIX_ACTs_104a_Status_XIX_Zone_VR_LIN11: start 4, 2 bit, little-endian, data-type-policy=OVERRIDE, i-signal-type=PRIMITIVE, init-value=0, base-type=BT_ACT104a_el_Defekt, invalid-value=Invalid_ACT104a_el_Defekt_XIX_ACTs_104a_Status_XIX_Zone_VR_LIN11:3, compu {3=Cx3_Fehler, 1=Cx1_el_Fehler_1, 0=Cx0_kein_Fehler, 2=Cx2_el_Fehler_2}, range raw 0..3, transfer-property=PENDING, to Zone_VR(timeout 3.5 s)  # Anzeige für einen elektrischen Fehler im Stellmotor
          signal ACT104a_Versorgungsspannung_XIX_ACTs_104a_Status_XIX_Zone_VR_LIN11: start 6, 2 bit, little-endian, data-type-policy=OVERRIDE, i-signal-type=PRIMITIVE, init-value=0, base-type=BT_ACT104a_Versorgungsspannung, invalid-value=Invalid_ACT104a_Versorgungsspannung_XIX_ACTs_104a_Status_XIX_Zone_VR_LIN11:3, compu {3=Cx3_Fehler, 1=Cx1_Unterspannung, 2=Cx2_Ueberspanung, 0=Cx0_Spannung_im_zulaessigen_Bereich}, range raw 0..3, transfer-property=PENDING, to Zone_VR(timeout 3.5 s)  # Versorgungsspannung des Aktuators
          signal ACT104a_Notlauf_aufgetreten_XIX_ACTs_104a_Status_XIX_Zone_VR_LIN11: start 8, 2 bit, little-endian, data-type-policy=OVERRIDE, i-signal-type=PRIMITIVE, init-value=0, base-type=BT_ACT104a_Notlauf_aufgetreten, invalid-value=Invalid_ACT104a_Notlauf_aufgetreten_XIX_ACTs_104a_Status_XIX_Zone_VR_LIN11:3, compu {3=Cx3_Fehler, 2=Cx2_reserviert, 0=Cx0_kein_Notlauf_aufgetreten, 1=Cx1_Notlauf_aufgetreten}, range raw 0..3, transfer-property=PENDING, to Zone_VR(timeout 3.5 s)  # Anzeige eines aufgetretenen Notlaufs seit dem letzten Reset oder "Clear Notlauf aufgetreten"
          signal ACT104a_Blockierung_aufgetreten_XIX_ACTs_104a_Status_XIX_Zone_VR_LIN11: start 12, 2 bit, little-endian, data-type-policy=OVERRIDE, i-signal-type=PRIMITIVE, init-value=0, base-type=BT_ACT104a_Blockierung_aufgetreten, invalid-value=Invalid_ACT104a_Blockierung_aufgetreten_XIX_ACTs_104a_Status_XIX_Zone_VR_LIN11:3, compu {3=Cx3_Fehler, 0=Cx0_keine_Blockierung, 2=Cx2_reserviert, 1=Cx1_Blockierung_erkannt}, range raw 0..3, transfer-property=PENDING, to Zone_VR(timeout 3.5 s)  # Anzeige einer aufgetretenen Blockierung seit dem letzten Reset oder "Clear Blockierung aufgetreten"
          signal ACT104a_Reset_XIX_ACTs_104a_Status_XIX_Zone_VR_LIN11: start 14, 2 bit, little-endian, data-type-policy=OVERRIDE, i-signal-type=PRIMITIVE, init-value=0, base-type=BT_ACT104a_Reset, invalid-value=Invalid_ACT104a_Reset_XIX_ACTs_104a_Status_XIX_Zone_VR_LIN11:3, compu {3=Cx3_Fehler, 2=Cx2_reserviert, 1=Cx1_Reset_durchgefuehrt, 0=Cx0_kein_Reset}, range raw 0..3, transfer-property=PENDING, to Zone_VR(timeout 3.5 s)  # Anzeige eines aufgetretenen Reset seit dem letzten ¿Clear Reset"
          signal ACT104a_Spulenbestromung_XIX_ACTs_104a_Status_XIX_Zone_VR_LIN11: start 16, 2 bit, little-endian, data-type-policy=OVERRIDE, i-signal-type=PRIMITIVE, init-value=0, base-type=BT_ACT104a_Spulenbestromung, invalid-value=Invalid_ACT104a_Spulenbestromung_XIX_ACTs_104a_Status_XIX_Zone_VR_LIN11:3, compu {3=Cx3_Fehler, 1=Cx1_Motorspulen_bestromt, 0=Cx0_Motorspulen_unbestromt, 2=Cx2_reserviert}, range raw 0..3, transfer-property=PENDING, to Zone_VR(timeout 3.5 s)  # Spulenbestromung im Haltezustand des Aktuators
          signal ACT104a_Positionsvorgabe_Status_XIX_ACTs_104a_Status_XIX_Zone_VR_LIN11: start 18, 2 bit, little-endian, data-type-policy=OVERRIDE, i-signal-type=PRIMITIVE, init-value=0, base-type=BT_ACT104a_Positionsvorgabe_Status, invalid-value=Invalid_ACT104a_Positionsvorgabe_Status_XIX_ACTs_104a_Status_XIX_Zone_VR_LIN11:3, compu {3=Cx3_Fehler, 1=Cx1_Start_Position_gueltig, 0=Cx0_Soll_Position_gueltig, 2=Cx2_keine_Positionsvorgabe_gueltig}, range raw 0..3, transfer-property=PENDING, to Zone_VR(timeout 3.5 s)  # Position des Aktuators
          signal ACT104a_Geschwindigkeitsstatus_XIX_ACTs_104a_Status_XIX_Zone_VR_LIN11: start 20, 4 bit, little-endian, data-type-policy=OVERRIDE, i-signal-type=PRIMITIVE, init-value=0, base-type=BT_ACT104a_Geschwindigkeitsstatus, invalid-value=Invalid_ACT104a_Geschwindigkeitsstatus_XIX_ACTs_104a_Status_XIX_Zone_VR_LIN11:15, compu {15=Cxf_Fehler, 4=Cx4_Geschwindigkeitsstufe_4, 5=Cx5_Autospeed, 0=Cx0_Motor_steht, 3=Cx3_Geschwindigkeitsstufe_3, 1=Cx1_Geschwindigkeitsstufe_1, 2=Cx2_Geschwindigkeitsstufe_2}, range raw 0..15, transfer-property=PENDING, to Zone_VR(timeout 3.5 s)  # Geschwindigkeitsstufe mit der die aktuelle Verfahrbewegung durchgeführt wird
          signal ACT104a_Ist_Position_Aktuator_XIX_ACTs_104a_Status_XIX_Zone_VR_LIN11: start 24, 16 bit, little-endian, data-type-policy=OVERRIDE, i-signal-type=PRIMITIVE, init-value=32767, base-type=BT_ACT104a_Ist_Position_Aktuator, invalid-value=Invalid_ACT104a_Ist_Position_Aktuator_XIX_ACTs_104a_Status_XIX_Zone_VR_LIN11:65535, compu {phys=raw for raw 0..65534, 65535=Cxffff_Fehler; unit Unit_None}, range phys 0..65534 Unit_None, raw 0..65535, unit=Unit_None, transfer-property=PENDING, to Zone_VR(timeout 3.5 s)  # IST-Position des Aktuators
          signal ACT104a_Verfahrrichtung_XIX_ACTs_104a_Status_XIX_Zone_VR_LIN11: start 40, 2 bit, little-endian, data-type-policy=OVERRIDE, i-signal-type=PRIMITIVE, init-value=2, base-type=BT_ACT104a_Verfahrrichtung, invalid-value=Invalid_ACT104a_Verfahrrichtung_XIX_ACTs_104a_Status_XIX_Zone_VR_LIN11:3, compu {3=Cx3_Fehler, 2=Cx2_Init, 0=Cx0_Richtung_kl_Schrittpositionen, 1=Cx1_Richtung_gr_Schrittpositionen}, range raw 0..3, transfer-property=PENDING, to Zone_VR(timeout 3.5 s)  # Verfahrrichtung der aktuellen oder zuletzt stattgefundenen Bewegung des Aktuators
          signal ACT104a_Selbsthaltemoment_XIX_ACTs_104a_Status_XIX_Zone_VR_LIN11: start 42, 2 bit, little-endian, data-type-policy=OVERRIDE, i-signal-type=PRIMITIVE, init-value=0, base-type=BT_ACT104a_Selbsthaltemoment, invalid-value=Invalid_ACT104a_Selbsthaltemoment_XIX_ACTs_104a_Status_XIX_Zone_VR_LIN11:3, compu {3=Cx3_Fehler, 0=Cx0_ohne_Selbsthaltemoment, 1=Cx1_mit_Selbsthaltemoment, 2=Cx2_reserviert}, range raw 0..3, transfer-property=PENDING, to Zone_VR(timeout 3.5 s)  # Das Signal gibt an ob ein selbsthemmendes Getriebe verbaut ist oder die SHB eingeschaltet ist
          signal ACT104a_Sonderfunktionen_XIX_ACTs_104a_Status_XIX_Zone_VR_LIN11: start 44, 2 bit, little-endian, data-type-policy=OVERRIDE, i-signal-type=PRIMITIVE, init-value=0, base-type=BT_ACT104a_Sonderfunktionen, invalid-value=Invalid_ACT104a_Sonderfunktionen_XIX_ACTs_104a_Status_XIX_Zone_VR_LIN11:3, compu {3=Cx3_Fehler, 2=Cx2_Sonderfunktion2_aktiv, 1=Cx1_Sonderfunktion1_aktiv, 0=Cx0_Keine_Sonderfunktion_aktiv}, range raw 0..3, transfer-property=PENDING, to Zone_VR(timeout 3.5 s)  # Funktionen des Aktuators
          signal ACT104a_Variante_XIX_ACTs_104a_Status_XIX_Zone_VR_LIN11: start 46, 2 bit, little-endian, data-type-policy=OVERRIDE, i-signal-type=PRIMITIVE, init-value=0, base-type=BT_ACT104a_Variante, compu {0=Cx0_Variante_1, 3=Cx3_Fehler_oder_nicht_umgesetzt, 1=Cx1_Variante_2, 2=Cx2_Variante_3}, range raw 0..3, transfer-property=PENDING, to Zone_VR(timeout 3.5 s)  # Das Signal gibt an welche Variante des Stellmotors verbaut ist
          signal ACT104a_Adresse_Aktuator_XIX_ACTs_104a_Status_XIX_Zone_VR_LIN11: start 48, 8 bit, little-endian, data-type-policy=OVERRIDE, i-signal-type=PRIMITIVE, init-value=255, base-type=BT_ACT104a_Adresse_Aktuator, compu {255=Cxff_Init}, range raw 255, transfer-property=PENDING, to Zone_VR(timeout 3.5 s)  # Adresse Aktuator
          signal ACT104a_Notlauffreigabe_XIX_ACTs_104a_Status_XIX_Zone_VR_LIN11: start 56, 2 bit, little-endian, data-type-policy=OVERRIDE, i-signal-type=PRIMITIVE, init-value=0, base-type=BT_ACT104a_Notlauffreigabe, invalid-value=Invalid_ACT104a_Notlauffreigabe_XIX_ACTs_104a_Status_XIX_Zone_VR_LIN11:3, compu {3=Cx3_Fehler, 2=Cx2_reserviert, 0=Cx0_Notlauf_aus, 1=Cx1_Notlauf_ein}, range raw 0..3, transfer-property=PENDING, to Zone_VR(timeout 3.5 s)  # Freigabe der Notlauffunktion des Aktuators
          signal ACT104a_Notlaufposition_XIX_ACTs_104a_Status_XIX_Zone_VR_LIN11: start 58, 2 bit, little-endian, data-type-policy=OVERRIDE, i-signal-type=PRIMITIVE, init-value=0, base-type=BT_ACT104a_Notlaufposition, invalid-value=Invalid_ACT104a_Notlaufposition_XIX_ACTs_104a_Status_XIX_Zone_VR_LIN11:3, compu {3=Cx3_Fehler, 2=Cx2_reserviert, 0=Cx0_unterer_Anschlag, 1=Cx1_oberer_Anschlag}, range raw 0..3, transfer-property=PENDING, to Zone_VR(timeout 3.5 s)  # Positionsvorgabe des Aktuators
          signal ACT104a_Drehrichtung_XIX_ACTs_104a_Status_XIX_Zone_VR_LIN11: start 60, 2 bit, little-endian, data-type-policy=OVERRIDE, i-signal-type=PRIMITIVE, init-value=0, base-type=BT_ACT104a_Drehrichtung, invalid-value=Invalid_ACT104a_Drehrichtung_XIX_ACTs_104a_Status_XIX_Zone_VR_LIN11:3, compu {3=Cx3_Fehler, 1=Cx1_Bewegung_in_Richtung_CCW, 2=Cx2_reserviert, 0=Cx0_Bewegung_in_Richtung_CW}, range raw 0..3, transfer-property=PENDING, to Zone_VR(timeout 3.5 s)  # Drehrichtung des Aktuators
          signal ACT104a_Stopmodus_XIX_ACTs_104a_Status_XIX_Zone_VR_LIN11: start 62, 2 bit, little-endian, data-type-policy=OVERRIDE, i-signal-type=PRIMITIVE, init-value=0, base-type=BT_ACT104a_Stopmodus, invalid-value=Invalid_ACT104a_Stopmodus_XIX_ACTs_104a_Status_XIX_Zone_VR_LIN11:3, compu {3=Cx3_Fehler, 2=Cx2_reserviert, 1=Cx1_Stop_Mode, 0=Cx0_Normal_Mode}, range raw 0..3, transfer-property=PENDING, to Zone_VR(timeout 3.5 s)  # Modus des Aktuators
      frame ACTs_105a_Status_XIX_Zone_VR_LIN11: id 0x20, to Zone_VR, frame-length=8, lin-checksum=ENHANCED
        pdu ACTs_105a_Status_XIX_Zone_VR_LIN11: length=8, unused-bit-pattern=0
          signal ACT105a_ResponseError_XIX_ACTs_105a_Status_XIX_Zone_VR_LIN11: start 0, 1 bit, little-endian, data-type-policy=OVERRIDE, i-signal-type=PRIMITIVE, init-value=0, base-type=BT_ACT105a_ResponseError, invalid-value=Invalid_ACT105a_ResponseError_XIX_ACTs_105a_Status_XIX_Zone_VR_LIN11:1, compu {1=Cx1_Fehler, 0=Cx0_normal}, range raw 0..1, transfer-property=PENDING  # siehe LIN2.0-Specification (Darf nicht über ein Fehlergueltigkeitsbit abgesichtert werden!)
          signal ACT105a_Uebertemperatur_XIX_ACTs_105a_Status_XIX_Zone_VR_LIN11: start 2, 2 bit, little-endian, data-type-policy=OVERRIDE, i-signal-type=PRIMITIVE, init-value=0, base-type=BT_ACT105a_Uebertemperatur, invalid-value=Invalid_ACT105a_Uebertemperatur_XIX_ACTs_105a_Status_XIX_Zone_VR_LIN11:3, compu {3=Cx3_Fehler, 1=Cx1_Uebertemperatur, 0=Cx0_keine_Uebertemperatur, 2=Cx2_reserviert}, range raw 0..3, transfer-property=PENDING, to Zone_VR(timeout 3.5 s)  # Anzeige einer Übertemperatur im Stellmotoren-ASIC
          signal ACT105a_el_Defekt_XIX_ACTs_105a_Status_XIX_Zone_VR_LIN11: start 4, 2 bit, little-endian, data-type-policy=OVERRIDE, i-signal-type=PRIMITIVE, init-value=0, base-type=BT_ACT105a_el_Defekt, invalid-value=Invalid_ACT105a_el_Defekt_XIX_ACTs_105a_Status_XIX_Zone_VR_LIN11:3, compu {3=Cx3_Fehler, 0=Cx0_kein_Fehler, 2=Cx2_el_Fehler_2, 1=Cx1_el_Fehler_1}, range raw 0..3, transfer-property=PENDING, to Zone_VR(timeout 3.5 s)  # Anzeige für einen elektrischen Fehler im Stellmotor
          signal ACT105a_Versorgungsspannung_XIX_ACTs_105a_Status_XIX_Zone_VR_LIN11: start 6, 2 bit, little-endian, data-type-policy=OVERRIDE, i-signal-type=PRIMITIVE, init-value=0, base-type=BT_ACT105a_Versorgungsspannung, invalid-value=Invalid_ACT105a_Versorgungsspannung_XIX_ACTs_105a_Status_XIX_Zone_VR_LIN11:3, compu {3=Cx3_Fehler, 0=Cx0_Spannung_im_zulaessigen_Bereich, 2=Cx2_Ueberspanung, 1=Cx1_Unterspannung}, range raw 0..3, transfer-property=PENDING, to Zone_VR(timeout 3.5 s)  # Versorgungsspannung des Aktuators
          signal ACT105a_Notlauf_aufgetreten_XIX_ACTs_105a_Status_XIX_Zone_VR_LIN11: start 8, 2 bit, little-endian, data-type-policy=OVERRIDE, i-signal-type=PRIMITIVE, init-value=0, base-type=BT_ACT105a_Notlauf_aufgetreten, invalid-value=Invalid_ACT105a_Notlauf_aufgetreten_XIX_ACTs_105a_Status_XIX_Zone_VR_LIN11:3, compu {3=Cx3_Fehler, 0=Cx0_kein_Notlauf_aufgetreten, 1=Cx1_Notlauf_aufgetreten, 2=Cx2_reserviert}, range raw 0..3, transfer-property=PENDING, to Zone_VR(timeout 3.5 s)  # Anzeige eines aufgetretenen Notlaufs seit dem letzten Reset oder "Clear Notlauf aufgetreten"
          signal ACT105a_Blockierung_aufgetreten_XIX_ACTs_105a_Status_XIX_Zone_VR_LIN11: start 12, 2 bit, little-endian, data-type-policy=OVERRIDE, i-signal-type=PRIMITIVE, init-value=0, base-type=BT_ACT105a_Blockierung_aufgetreten, invalid-value=Invalid_ACT105a_Blockierung_aufgetreten_XIX_ACTs_105a_Status_XIX_Zone_VR_LIN11:3, compu {3=Cx3_Fehler, 1=Cx1_Blockierung_erkannt, 2=Cx2_reserviert, 0=Cx0_keine_Blockierung}, range raw 0..3, transfer-property=PENDING, to Zone_VR(timeout 3.5 s)  # Anzeige einer aufgetretenen Blockierung seit dem letzten Reset oder "Clear Blockierung aufgetreten"
          signal ACT105a_Reset_XIX_ACTs_105a_Status_XIX_Zone_VR_LIN11: start 14, 2 bit, little-endian, data-type-policy=OVERRIDE, i-signal-type=PRIMITIVE, init-value=0, base-type=BT_ACT105a_Reset, invalid-value=Invalid_ACT105a_Reset_XIX_ACTs_105a_Status_XIX_Zone_VR_LIN11:3, compu {3=Cx3_Fehler, 0=Cx0_kein_Reset, 2=Cx2_reserviert, 1=Cx1_Reset_durchgefuehrt}, range raw 0..3, transfer-property=PENDING, to Zone_VR(timeout 3.5 s)  # Anzeige eines aufgetretenen Reset seit dem letzten ¿Clear Reset"
          signal ACT105a_Spulenbestromung_XIX_ACTs_105a_Status_XIX_Zone_VR_LIN11: start 16, 2 bit, little-endian, data-type-policy=OVERRIDE, i-signal-type=PRIMITIVE, init-value=0, base-type=BT_ACT105a_Spulenbestromung, invalid-value=Invalid_ACT105a_Spulenbestromung_XIX_ACTs_105a_Status_XIX_Zone_VR_LIN11:3, compu {3=Cx3_Fehler, 0=Cx0_Motorspulen_unbestromt, 2=Cx2_reserviert, 1=Cx1_Motorspulen_bestromt}, range raw 0..3, transfer-property=PENDING, to Zone_VR(timeout 3.5 s)  # Spulenbestromung im Haltezustand des Aktuators
          signal ACT105a_Positionsvorgabe_Status_XIX_ACTs_105a_Status_XIX_Zone_VR_LIN11: start 18, 2 bit, little-endian, data-type-policy=OVERRIDE, i-signal-type=PRIMITIVE, init-value=0, base-type=BT_ACT105a_Positionsvorgabe_Status, invalid-value=Invalid_ACT105a_Positionsvorgabe_Status_XIX_ACTs_105a_Status_XIX_Zone_VR_LIN11:3, compu {3=Cx3_Fehler, 2=Cx2_keine_Positionsvorgabe_gueltig, 0=Cx0_Soll_Position_gueltig, 1=Cx1_Start_Position_gueltig}, range raw 0..3, transfer-property=PENDING, to Zone_VR(timeout 3.5 s)  # Position des Aktuators
          signal ACT105a_Geschwindigkeitsstatus_XIX_ACTs_105a_Status_XIX_Zone_VR_LIN11: start 20, 4 bit, little-endian, data-type-policy=OVERRIDE, i-signal-type=PRIMITIVE, init-value=0, base-type=BT_ACT105a_Geschwindigkeitsstatus, invalid-value=Invalid_ACT105a_Geschwindigkeitsstatus_XIX_ACTs_105a_Status_XIX_Zone_VR_LIN11:15, compu {15=Cxf_Fehler, 5=Cx5_Autospeed, 4=Cx4_Geschwindigkeitsstufe_4, 0=Cx0_Motor_steht, 1=Cx1_Geschwindigkeitsstufe_1, 3=Cx3_Geschwindigkeitsstufe_3, 2=Cx2_Geschwindigkeitsstufe_2}, range raw 0..15, transfer-property=PENDING, to Zone_VR(timeout 3.5 s)  # Geschwindigkeitsstufe mit der die aktuelle Verfahrbewegung durchgeführt wird
          signal ACT105a_Ist_Position_Aktuator_XIX_ACTs_105a_Status_XIX_Zone_VR_LIN11: start 24, 16 bit, little-endian, data-type-policy=OVERRIDE, i-signal-type=PRIMITIVE, init-value=32767, base-type=BT_ACT105a_Ist_Position_Aktuator, invalid-value=Invalid_ACT105a_Ist_Position_Aktuator_XIX_ACTs_105a_Status_XIX_Zone_VR_LIN11:65535, compu {phys=raw for raw 0..65534, 65535=Cxffff_Fehler; unit Unit_None}, range phys 0..65534 Unit_None, raw 0..65535, unit=Unit_None, transfer-property=PENDING, to Zone_VR(timeout 3.5 s)  # IST-Position des Aktuators
          signal ACT105a_Verfahrrichtung_XIX_ACTs_105a_Status_XIX_Zone_VR_LIN11: start 40, 2 bit, little-endian, data-type-policy=OVERRIDE, i-signal-type=PRIMITIVE, init-value=2, base-type=BT_ACT105a_Verfahrrichtung, invalid-value=Invalid_ACT105a_Verfahrrichtung_XIX_ACTs_105a_Status_XIX_Zone_VR_LIN11:3, compu {3=Cx3_Fehler, 0=Cx0_Richtung_kl_Schrittpositionen, 2=Cx2_Init, 1=Cx1_Richtung_gr_Schrittpositionen}, range raw 0..3, transfer-property=PENDING, to Zone_VR(timeout 3.5 s)  # Verfahrrichtung der aktuellen oder zuletzt stattgefundenen Bewegung des Aktuators
          signal ACT105a_Selbsthaltemoment_XIX_ACTs_105a_Status_XIX_Zone_VR_LIN11: start 42, 2 bit, little-endian, data-type-policy=OVERRIDE, i-signal-type=PRIMITIVE, init-value=0, base-type=BT_ACT105a_Selbsthaltemoment, invalid-value=Invalid_ACT105a_Selbsthaltemoment_XIX_ACTs_105a_Status_XIX_Zone_VR_LIN11:3, compu {3=Cx3_Fehler, 0=Cx0_ohne_Selbsthaltemoment, 2=Cx2_reserviert, 1=Cx1_mit_Selbsthaltemoment}, range raw 0..3, transfer-property=PENDING, to Zone_VR(timeout 3.5 s)  # Das Signal gibt an ob ein selbsthemmendes Getriebe verbaut ist oder die SHB eingeschaltet ist
          signal ACT105a_Sonderfunktionen_XIX_ACTs_105a_Status_XIX_Zone_VR_LIN11: start 44, 2 bit, little-endian, data-type-policy=OVERRIDE, i-signal-type=PRIMITIVE, init-value=0, base-type=BT_ACT105a_Sonderfunktionen, invalid-value=Invalid_ACT105a_Sonderfunktionen_XIX_ACTs_105a_Status_XIX_Zone_VR_LIN11:3, compu {3=Cx3_Fehler, 0=Cx0_Keine_Sonderfunktion_aktiv, 1=Cx1_Sonderfunktion1_aktiv, 2=Cx2_Sonderfunktion2_aktiv}, range raw 0..3, transfer-property=PENDING, to Zone_VR(timeout 3.5 s)  # Funktionen des Aktuators
          signal ACT105a_Variante_XIX_ACTs_105a_Status_XIX_Zone_VR_LIN11: start 46, 2 bit, little-endian, data-type-policy=OVERRIDE, i-signal-type=PRIMITIVE, init-value=0, base-type=BT_ACT105a_Variante, compu {1=Cx1_Variante_2, 2=Cx2_Variante_3, 0=Cx0_Variante_1, 3=Cx3_Fehler_oder_nicht_umgesetzt}, range raw 0..3, transfer-property=PENDING, to Zone_VR(timeout 3.5 s)  # Das Signal gibt an welche Variante des Stellmotors verbaut ist
          signal ACT105a_Adresse_Aktuator_XIX_ACTs_105a_Status_XIX_Zone_VR_LIN11: start 48, 8 bit, little-endian, data-type-policy=OVERRIDE, i-signal-type=PRIMITIVE, init-value=255, base-type=BT_ACT105a_Adresse_Aktuator, compu {255=Cxff_Init}, range raw 255, transfer-property=PENDING, to Zone_VR(timeout 3.5 s)  # Adresse Aktuator
          signal ACT105a_Notlauffreigabe_XIX_ACTs_105a_Status_XIX_Zone_VR_LIN11: start 56, 2 bit, little-endian, data-type-policy=OVERRIDE, i-signal-type=PRIMITIVE, init-value=0, base-type=BT_ACT105a_Notlauffreigabe, invalid-value=Invalid_ACT105a_Notlauffreigabe_XIX_ACTs_105a_Status_XIX_Zone_VR_LIN11:3, compu {3=Cx3_Fehler, 2=Cx2_reserviert, 0=Cx0_Notlauf_aus, 1=Cx1_Notlauf_ein}, range raw 0..3, transfer-property=PENDING, to Zone_VR(timeout 3.5 s)  # Freigabe der Notlauffunktion des Aktuators
          signal ACT105a_Notlaufposition_XIX_ACTs_105a_Status_XIX_Zone_VR_LIN11: start 58, 2 bit, little-endian, data-type-policy=OVERRIDE, i-signal-type=PRIMITIVE, init-value=0, base-type=BT_ACT105a_Notlaufposition, invalid-value=Invalid_ACT105a_Notlaufposition_XIX_ACTs_105a_Status_XIX_Zone_VR_LIN11:3, compu {3=Cx3_Fehler, 1=Cx1_oberer_Anschlag, 2=Cx2_reserviert, 0=Cx0_unterer_Anschlag}, range raw 0..3, transfer-property=PENDING, to Zone_VR(timeout 3.5 s)  # Positionsvorgabe des Aktuators
          signal ACT105a_Drehrichtung_XIX_ACTs_105a_Status_XIX_Zone_VR_LIN11: start 60, 2 bit, little-endian, data-type-policy=OVERRIDE, i-signal-type=PRIMITIVE, init-value=0, base-type=BT_ACT105a_Drehrichtung, invalid-value=Invalid_ACT105a_Drehrichtung_XIX_ACTs_105a_Status_XIX_Zone_VR_LIN11:3, compu {3=Cx3_Fehler, 2=Cx2_reserviert, 1=Cx1_Bewegung_in_Richtung_CCW, 0=Cx0_Bewegung_in_Richtung_CW}, range raw 0..3, transfer-property=PENDING, to Zone_VR(timeout 3.5 s)  # Drehrichtung des Aktuators
          signal ACT105a_Stopmodus_XIX_ACTs_105a_Status_XIX_Zone_VR_LIN11: start 62, 2 bit, little-endian, data-type-policy=OVERRIDE, i-signal-type=PRIMITIVE, init-value=0, base-type=BT_ACT105a_Stopmodus, invalid-value=Invalid_ACT105a_Stopmodus_XIX_ACTs_105a_Status_XIX_Zone_VR_LIN11:3, compu {3=Cx3_Fehler, 0=Cx0_Normal_Mode, 1=Cx1_Stop_Mode, 2=Cx2_reserviert}, range raw 0..3, transfer-property=PENDING, to Zone_VR(timeout 3.5 s)  # Modus des Aktuators
      frame ACTs_106a_Status_XIX_Zone_VR_LIN11: id 0x21, to Zone_VR, frame-length=8, lin-checksum=ENHANCED
        pdu ACTs_106a_Status_XIX_Zone_VR_LIN11: length=8, unused-bit-pattern=0
          signal ACT106a_ResponseError_XIX_ACTs_106a_Status_XIX_Zone_VR_LIN11: start 0, 1 bit, little-endian, data-type-policy=OVERRIDE, i-signal-type=PRIMITIVE, init-value=0, base-type=BT_ACT106a_ResponseError, invalid-value=Invalid_ACT106a_ResponseError_XIX_ACTs_106a_Status_XIX_Zone_VR_LIN11:1, compu {1=Cx1_Fehler, 0=Cx0_normal}, range raw 0..1, transfer-property=PENDING  # siehe LIN2.0-Specification (Darf nicht über ein Fehlergueltigkeitsbit abgesichtert werden!)
          signal ACT106a_Uebertemperatur_XIX_ACTs_106a_Status_XIX_Zone_VR_LIN11: start 2, 2 bit, little-endian, data-type-policy=OVERRIDE, i-signal-type=PRIMITIVE, init-value=0, base-type=BT_ACT106a_Uebertemperatur, invalid-value=Invalid_ACT106a_Uebertemperatur_XIX_ACTs_106a_Status_XIX_Zone_VR_LIN11:3, compu {3=Cx3_Fehler, 0=Cx0_keine_Uebertemperatur, 1=Cx1_Uebertemperatur, 2=Cx2_reserviert}, range raw 0..3, transfer-property=PENDING, to Zone_VR(timeout 3.5 s)  # Anzeige einer Übertemperatur im Stellmotoren-ASIC
          signal ACT106a_el_Defekt_XIX_ACTs_106a_Status_XIX_Zone_VR_LIN11: start 4, 2 bit, little-endian, data-type-policy=OVERRIDE, i-signal-type=PRIMITIVE, init-value=0, base-type=BT_ACT106a_el_Defekt, invalid-value=Invalid_ACT106a_el_Defekt_XIX_ACTs_106a_Status_XIX_Zone_VR_LIN11:3, compu {3=Cx3_Fehler, 1=Cx1_el_Fehler_1, 2=Cx2_el_Fehler_2, 0=Cx0_kein_Fehler}, range raw 0..3, transfer-property=PENDING, to Zone_VR(timeout 3.5 s)  # Anzeige für einen elektrischen Fehler im Stellmotor
          signal ACT106a_Versorgungsspannung_XIX_ACTs_106a_Status_XIX_Zone_VR_LIN11: start 6, 2 bit, little-endian, data-type-policy=OVERRIDE, i-signal-type=PRIMITIVE, init-value=0, base-type=BT_ACT106a_Versorgungsspannung, invalid-value=Invalid_ACT106a_Versorgungsspannung_XIX_ACTs_106a_Status_XIX_Zone_VR_LIN11:3, compu {3=Cx3_Fehler, 2=Cx2_Ueberspanung, 0=Cx0_Spannung_im_zulaessigen_Bereich, 1=Cx1_Unterspannung}, range raw 0..3, transfer-property=PENDING, to Zone_VR(timeout 3.5 s)  # Versorgungsspannung des Aktuators
          signal ACT106a_Notlauf_aufgetreten_XIX_ACTs_106a_Status_XIX_Zone_VR_LIN11: start 8, 2 bit, little-endian, data-type-policy=OVERRIDE, i-signal-type=PRIMITIVE, init-value=0, base-type=BT_ACT106a_Notlauf_aufgetreten, invalid-value=Invalid_ACT106a_Notlauf_aufgetreten_XIX_ACTs_106a_Status_XIX_Zone_VR_LIN11:3, compu {3=Cx3_Fehler, 0=Cx0_kein_Notlauf_aufgetreten, 2=Cx2_reserviert, 1=Cx1_Notlauf_aufgetreten}, range raw 0..3, transfer-property=PENDING, to Zone_VR(timeout 3.5 s)  # Anzeige eines aufgetretenen Notlaufs seit dem letzten Reset oder "Clear Notlauf aufgetreten"
          signal ACT106a_Blockierung_aufgetreten_XIX_ACTs_106a_Status_XIX_Zone_VR_LIN11: start 12, 2 bit, little-endian, data-type-policy=OVERRIDE, i-signal-type=PRIMITIVE, init-value=0, base-type=BT_ACT106a_Blockierung_aufgetreten, invalid-value=Invalid_ACT106a_Blockierung_aufgetreten_XIX_ACTs_106a_Status_XIX_Zone_VR_LIN11:3, compu {3=Cx3_Fehler, 2=Cx2_reserviert, 1=Cx1_Blockierung_erkannt, 0=Cx0_keine_Blockierung}, range raw 0..3, transfer-property=PENDING, to Zone_VR(timeout 3.5 s)  # Anzeige einer aufgetretenen Blockierung seit dem letzten Reset oder "Clear Blockierung aufgetreten"
          signal ACT106a_Reset_XIX_ACTs_106a_Status_XIX_Zone_VR_LIN11: start 14, 2 bit, little-endian, data-type-policy=OVERRIDE, i-signal-type=PRIMITIVE, init-value=0, base-type=BT_ACT106a_Reset, invalid-value=Invalid_ACT106a_Reset_XIX_ACTs_106a_Status_XIX_Zone_VR_LIN11:3, compu {3=Cx3_Fehler, 1=Cx1_Reset_durchgefuehrt, 2=Cx2_reserviert, 0=Cx0_kein_Reset}, range raw 0..3, transfer-property=PENDING, to Zone_VR(timeout 3.5 s)  # Anzeige eines aufgetretenen Reset seit dem letzten ¿Clear Reset"
          signal ACT106a_Spulenbestromung_XIX_ACTs_106a_Status_XIX_Zone_VR_LIN11: start 16, 2 bit, little-endian, data-type-policy=OVERRIDE, i-signal-type=PRIMITIVE, init-value=0, base-type=BT_ACT106a_Spulenbestromung, invalid-value=Invalid_ACT106a_Spulenbestromung_XIX_ACTs_106a_Status_XIX_Zone_VR_LIN11:3, compu {3=Cx3_Fehler, 0=Cx0_Motorspulen_unbestromt, 1=Cx1_Motorspulen_bestromt, 2=Cx2_reserviert}, range raw 0..3, transfer-property=PENDING, to Zone_VR(timeout 3.5 s)  # Spulenbestromung im Haltezustand des Aktuators
          signal ACT106a_Positionsvorgabe_Status_XIX_ACTs_106a_Status_XIX_Zone_VR_LIN11: start 18, 2 bit, little-endian, data-type-policy=OVERRIDE, i-signal-type=PRIMITIVE, init-value=0, base-type=BT_ACT106a_Positionsvorgabe_Status, invalid-value=Invalid_ACT106a_Positionsvorgabe_Status_XIX_ACTs_106a_Status_XIX_Zone_VR_LIN11:3, compu {3=Cx3_Fehler, 2=Cx2_keine_Positionsvorgabe_gueltig, 1=Cx1_Start_Position_gueltig, 0=Cx0_Soll_Position_gueltig}, range raw 0..3, transfer-property=PENDING, to Zone_VR(timeout 3.5 s)  # Position des Aktuators
          signal ACT106a_Geschwindigkeitsstatus_XIX_ACTs_106a_Status_XIX_Zone_VR_LIN11: start 20, 4 bit, little-endian, data-type-policy=OVERRIDE, i-signal-type=PRIMITIVE, init-value=0, base-type=BT_ACT106a_Geschwindigkeitsstatus, invalid-value=Invalid_ACT106a_Geschwindigkeitsstatus_XIX_ACTs_106a_Status_XIX_Zone_VR_LIN11:15, compu {15=Cxf_Fehler, 3=Cx3_Geschwindigkeitsstufe_3, 1=Cx1_Geschwindigkeitsstufe_1, 2=Cx2_Geschwindigkeitsstufe_2, 4=Cx4_Geschwindigkeitsstufe_4, 0=Cx0_Motor_steht, 5=Cx5_Autospeed}, range raw 0..15, transfer-property=PENDING, to Zone_VR(timeout 3.5 s)  # Geschwindigkeitsstufe mit der die aktuelle Verfahrbewegung durchgeführt wird
          signal ACT106a_Ist_Position_Aktuator_XIX_ACTs_106a_Status_XIX_Zone_VR_LIN11: start 24, 16 bit, little-endian, data-type-policy=OVERRIDE, i-signal-type=PRIMITIVE, init-value=32767, base-type=BT_ACT106a_Ist_Position_Aktuator, invalid-value=Invalid_ACT106a_Ist_Position_Aktuator_XIX_ACTs_106a_Status_XIX_Zone_VR_LIN11:65535, compu {phys=raw for raw 0..65534, 65535=Cxffff_Fehler; unit Unit_None}, range phys 0..65534 Unit_None, raw 0..65535, unit=Unit_None, transfer-property=PENDING, to Zone_VR(timeout 3.5 s)  # IST-Position des Aktuators
          signal ACT106a_Verfahrrichtung_XIX_ACTs_106a_Status_XIX_Zone_VR_LIN11: start 40, 2 bit, little-endian, data-type-policy=OVERRIDE, i-signal-type=PRIMITIVE, init-value=2, base-type=BT_ACT106a_Verfahrrichtung, invalid-value=Invalid_ACT106a_Verfahrrichtung_XIX_ACTs_106a_Status_XIX_Zone_VR_LIN11:3, compu {3=Cx3_Fehler, 2=Cx2_Init, 0=Cx0_Richtung_kl_Schrittpositionen, 1=Cx1_Richtung_gr_Schrittpositionen}, range raw 0..3, transfer-property=PENDING, to Zone_VR(timeout 3.5 s)  # Verfahrrichtung der aktuellen oder zuletzt stattgefundenen Bewegung des Aktuators
          signal ACT106a_Selbsthaltemoment_XIX_ACTs_106a_Status_XIX_Zone_VR_LIN11: start 42, 2 bit, little-endian, data-type-policy=OVERRIDE, i-signal-type=PRIMITIVE, init-value=0, base-type=BT_ACT106a_Selbsthaltemoment, invalid-value=Invalid_ACT106a_Selbsthaltemoment_XIX_ACTs_106a_Status_XIX_Zone_VR_LIN11:3, compu {3=Cx3_Fehler, 1=Cx1_mit_Selbsthaltemoment, 2=Cx2_reserviert, 0=Cx0_ohne_Selbsthaltemoment}, range raw 0..3, transfer-property=PENDING, to Zone_VR(timeout 3.5 s)  # Das Signal gibt an ob ein selbsthemmendes Getriebe verbaut ist oder die SHB eingeschaltet ist
          signal ACT106a_Sonderfunktionen_XIX_ACTs_106a_Status_XIX_Zone_VR_LIN11: start 44, 2 bit, little-endian, data-type-policy=OVERRIDE, i-signal-type=PRIMITIVE, init-value=0, base-type=BT_ACT106a_Sonderfunktionen, invalid-value=Invalid_ACT106a_Sonderfunktionen_XIX_ACTs_106a_Status_XIX_Zone_VR_LIN11:3, compu {3=Cx3_Fehler, 2=Cx2_Sonderfunktion2_aktiv, 0=Cx0_Keine_Sonderfunktion_aktiv, 1=Cx1_Sonderfunktion1_aktiv}, range raw 0..3, transfer-property=PENDING, to Zone_VR(timeout 3.5 s)  # Funktionen des Aktuators
          signal ACT106a_Variante_XIX_ACTs_106a_Status_XIX_Zone_VR_LIN11: start 46, 2 bit, little-endian, data-type-policy=OVERRIDE, i-signal-type=PRIMITIVE, init-value=0, base-type=BT_ACT106a_Variante, compu {1=Cx1_Variante_2, 3=Cx3_Fehler_oder_nicht_umgesetzt, 2=Cx2_Variante_3, 0=Cx0_Variante_1}, range raw 0..3, transfer-property=PENDING, to Zone_VR(timeout 3.5 s)  # Das Signal gibt an welche Variante des Stellmotors verbaut ist
          signal ACT106a_Adresse_Aktuator_XIX_ACTs_106a_Status_XIX_Zone_VR_LIN11: start 48, 8 bit, little-endian, data-type-policy=OVERRIDE, i-signal-type=PRIMITIVE, init-value=255, base-type=BT_ACT106a_Adresse_Aktuator, compu {255=Cxff_Init}, range raw 255, transfer-property=PENDING, to Zone_VR(timeout 3.5 s)  # Adresse Aktuator
          signal ACT106a_Notlauffreigabe_XIX_ACTs_106a_Status_XIX_Zone_VR_LIN11: start 56, 2 bit, little-endian, data-type-policy=OVERRIDE, i-signal-type=PRIMITIVE, init-value=0, base-type=BT_ACT106a_Notlauffreigabe, invalid-value=Invalid_ACT106a_Notlauffreigabe_XIX_ACTs_106a_Status_XIX_Zone_VR_LIN11:3, compu {3=Cx3_Fehler, 0=Cx0_Notlauf_aus, 2=Cx2_reserviert, 1=Cx1_Notlauf_ein}, range raw 0..3, transfer-property=PENDING, to Zone_VR(timeout 3.5 s)  # Freigabe der Notlauffunktion des Aktuators
          signal ACT106a_Notlaufposition_XIX_ACTs_106a_Status_XIX_Zone_VR_LIN11: start 58, 2 bit, little-endian, data-type-policy=OVERRIDE, i-signal-type=PRIMITIVE, init-value=0, base-type=BT_ACT106a_Notlaufposition, invalid-value=Invalid_ACT106a_Notlaufposition_XIX_ACTs_106a_Status_XIX_Zone_VR_LIN11:3, compu {3=Cx3_Fehler, 1=Cx1_oberer_Anschlag, 2=Cx2_reserviert, 0=Cx0_unterer_Anschlag}, range raw 0..3, transfer-property=PENDING, to Zone_VR(timeout 3.5 s)  # Positionsvorgabe des Aktuators
          signal ACT106a_Drehrichtung_XIX_ACTs_106a_Status_XIX_Zone_VR_LIN11: start 60, 2 bit, little-endian, data-type-policy=OVERRIDE, i-signal-type=PRIMITIVE, init-value=0, base-type=BT_ACT106a_Drehrichtung, invalid-value=Invalid_ACT106a_Drehrichtung_XIX_ACTs_106a_Status_XIX_Zone_VR_LIN11:3, compu {3=Cx3_Fehler, 2=Cx2_reserviert, 1=Cx1_Bewegung_in_Richtung_CCW, 0=Cx0_Bewegung_in_Richtung_CW}, range raw 0..3, transfer-property=PENDING, to Zone_VR(timeout 3.5 s)  # Drehrichtung des Aktuators
          signal ACT106a_Stopmodus_XIX_ACTs_106a_Status_XIX_Zone_VR_LIN11: start 62, 2 bit, little-endian, data-type-policy=OVERRIDE, i-signal-type=PRIMITIVE, init-value=0, base-type=BT_ACT106a_Stopmodus, invalid-value=Invalid_ACT106a_Stopmodus_XIX_ACTs_106a_Status_XIX_Zone_VR_LIN11:3, compu {3=Cx3_Fehler, 1=Cx1_Stop_Mode, 2=Cx2_reserviert, 0=Cx0_Normal_Mode}, range raw 0..3, transfer-property=PENDING, to Zone_VR(timeout 3.5 s)  # Modus des Aktuators
      frame ACTs_109a_Status_XIX_Zone_VR_LIN11: id 0x26, to Zone_VR, frame-length=8, lin-checksum=ENHANCED
        pdu ACTs_109a_Status_XIX_Zone_VR_LIN11: length=8, unused-bit-pattern=0
          signal ACT109a_ResponseError_XIX_ACTs_109a_Status_XIX_Zone_VR_LIN11: start 0, 1 bit, little-endian, data-type-policy=OVERRIDE, i-signal-type=PRIMITIVE, init-value=0, base-type=BT_ACT109a_ResponseError, invalid-value=Invalid_ACT109a_ResponseError_XIX_ACTs_109a_Status_XIX_Zone_VR_LIN11:1, compu {1=Cx1_Fehler, 0=Cx0_normal}, range raw 0..1, transfer-property=PENDING  # siehe LIN2.0-Specification (Darf nicht über ein Fehlergueltigkeitsbit abgesichtert werden!)
          signal ACT109a_Uebertemperatur_XIX_ACTs_109a_Status_XIX_Zone_VR_LIN11: start 2, 2 bit, little-endian, data-type-policy=OVERRIDE, i-signal-type=PRIMITIVE, init-value=0, base-type=BT_ACT109a_Uebertemperatur, invalid-value=Invalid_ACT109a_Uebertemperatur_XIX_ACTs_109a_Status_XIX_Zone_VR_LIN11:3, compu {3=Cx3_Fehler, 0=Cx0_keine_Uebertemperatur, 2=Cx2_reserviert, 1=Cx1_Uebertemperatur}, range raw 0..3, transfer-property=PENDING, to Zone_VR(timeout 3.5 s)  # Anzeige einer Übertemperatur im Stellmotoren-ASIC
          signal ACT109a_el_Defekt_XIX_ACTs_109a_Status_XIX_Zone_VR_LIN11: start 4, 2 bit, little-endian, data-type-policy=OVERRIDE, i-signal-type=PRIMITIVE, init-value=0, base-type=BT_ACT109a_el_Defekt, invalid-value=Invalid_ACT109a_el_Defekt_XIX_ACTs_109a_Status_XIX_Zone_VR_LIN11:3, compu {3=Cx3_Fehler, 1=Cx1_el_Fehler_1, 2=Cx2_el_Fehler_2, 0=Cx0_kein_Fehler}, range raw 0..3, transfer-property=PENDING, to Zone_VR(timeout 3.5 s)  # Anzeige für einen elektrischen Fehler im Stellmotor
          signal ACT109a_Versorgungsspannung_XIX_ACTs_109a_Status_XIX_Zone_VR_LIN11: start 6, 2 bit, little-endian, data-type-policy=OVERRIDE, i-signal-type=PRIMITIVE, init-value=0, base-type=BT_ACT109a_Versorgungsspannung, invalid-value=Invalid_ACT109a_Versorgungsspannung_XIX_ACTs_109a_Status_XIX_Zone_VR_LIN11:3, compu {3=Cx3_Fehler, 0=Cx0_Spannung_im_zulaessigen_Bereich, 2=Cx2_Ueberspanung, 1=Cx1_Unterspannung}, range raw 0..3, transfer-property=PENDING, to Zone_VR(timeout 3.5 s)  # Versorgungsspannung des Aktuators
          signal ACT109a_Notlauf_aufgetreten_XIX_ACTs_109a_Status_XIX_Zone_VR_LIN11: start 8, 2 bit, little-endian, data-type-policy=OVERRIDE, i-signal-type=PRIMITIVE, init-value=0, base-type=BT_ACT109a_Notlauf_aufgetreten, invalid-value=Invalid_ACT109a_Notlauf_aufgetreten_XIX_ACTs_109a_Status_XIX_Zone_VR_LIN11:3, compu {3=Cx3_Fehler, 2=Cx2_reserviert, 1=Cx1_Notlauf_aufgetreten, 0=Cx0_kein_Notlauf_aufgetreten}, range raw 0..3, transfer-property=PENDING, to Zone_VR(timeout 3.5 s)  # Anzeige eines aufgetretenen Notlaufs seit dem letzten Reset oder "Clear Notlauf aufgetreten"
          signal ACT109a_Blockierung_aufgetreten_XIX_ACTs_109a_Status_XIX_Zone_VR_LIN11: start 12, 2 bit, little-endian, data-type-policy=OVERRIDE, i-signal-type=PRIMITIVE, init-value=0, base-type=BT_ACT109a_Blockierung_aufgetreten, invalid-value=Invalid_ACT109a_Blockierung_aufgetreten_XIX_ACTs_109a_Status_XIX_Zone_VR_LIN11:3, compu {3=Cx3_Fehler, 2=Cx2_reserviert, 1=Cx1_Blockierung_erkannt, 0=Cx0_keine_Blockierung}, range raw 0..3, transfer-property=PENDING, to Zone_VR(timeout 3.5 s)  # Anzeige einer aufgetretenen Blockierung seit dem letzten Reset oder "Clear Blockierung aufgetreten"
          signal ACT109a_Reset_XIX_ACTs_109a_Status_XIX_Zone_VR_LIN11: start 14, 2 bit, little-endian, data-type-policy=OVERRIDE, i-signal-type=PRIMITIVE, init-value=0, base-type=BT_ACT109a_Reset, invalid-value=Invalid_ACT109a_Reset_XIX_ACTs_109a_Status_XIX_Zone_VR_LIN11:3, compu {3=Cx3_Fehler, 0=Cx0_kein_Reset, 2=Cx2_reserviert, 1=Cx1_Reset_durchgefuehrt}, range raw 0..3, transfer-property=PENDING, to Zone_VR(timeout 3.5 s)  # Anzeige eines aufgetretenen Reset seit dem letzten ¿Clear Reset"
          signal ACT109a_Spulenbestromung_XIX_ACTs_109a_Status_XIX_Zone_VR_LIN11: start 16, 2 bit, little-endian, data-type-policy=OVERRIDE, i-signal-type=PRIMITIVE, init-value=0, base-type=BT_ACT109a_Spulenbestromung, invalid-value=Invalid_ACT109a_Spulenbestromung_XIX_ACTs_109a_Status_XIX_Zone_VR_LIN11:3, compu {3=Cx3_Fehler, 1=Cx1_Motorspulen_bestromt, 0=Cx0_Motorspulen_unbestromt, 2=Cx2_reserviert}, range raw 0..3, transfer-property=PENDING, to Zone_VR(timeout 3.5 s)  # Spulenbestromung im Haltezustand des Aktuators
          signal ACT109a_Positionsvorgabe_Status_XIX_ACTs_109a_Status_XIX_Zone_VR_LIN11: start 18, 2 bit, little-endian, data-type-policy=OVERRIDE, i-signal-type=PRIMITIVE, init-value=0, base-type=BT_ACT109a_Positionsvorgabe_Status, invalid-value=Invalid_ACT109a_Positionsvorgabe_Status_XIX_ACTs_109a_Status_XIX_Zone_VR_LIN11:3, compu {3=Cx3_Fehler, 2=Cx2_keine_Positionsvorgabe_gueltig, 0=Cx0_Soll_Position_gueltig, 1=Cx1_Start_Position_gueltig}, range raw 0..3, transfer-property=PENDING, to Zone_VR(timeout 3.5 s)  # Position des Aktuators
          signal ACT109a_Geschwindigkeitsstatus_XIX_ACTs_109a_Status_XIX_Zone_VR_LIN11: start 20, 4 bit, little-endian, data-type-policy=OVERRIDE, i-signal-type=PRIMITIVE, init-value=0, base-type=BT_ACT109a_Geschwindigkeitsstatus, invalid-value=Invalid_ACT109a_Geschwindigkeitsstatus_XIX_ACTs_109a_Status_XIX_Zone_VR_LIN11:15, compu {15=Cxf_Fehler, 0=Cx0_Motor_steht, 4=Cx4_Geschwindigkeitsstufe_4, 1=Cx1_Geschwindigkeitsstufe_1, 3=Cx3_Geschwindigkeitsstufe_3, 5=Cx5_Autospeed, 2=Cx2_Geschwindigkeitsstufe_2}, range raw 0..15, transfer-property=PENDING, to Zone_VR(timeout 3.5 s)  # Geschwindigkeitsstufe mit der die aktuelle Verfahrbewegung durchgeführt wird
          signal ACT109a_Ist_Position_Aktuator_XIX_ACTs_109a_Status_XIX_Zone_VR_LIN11: start 24, 16 bit, little-endian, data-type-policy=OVERRIDE, i-signal-type=PRIMITIVE, init-value=32767, base-type=BT_ACT109a_Ist_Position_Aktuator, invalid-value=Invalid_ACT109a_Ist_Position_Aktuator_XIX_ACTs_109a_Status_XIX_Zone_VR_LIN11:65535, compu {phys=raw for raw 0..65534, 65535=Cxffff_Fehler; unit Unit_None}, range phys 0..65534 Unit_None, raw 0..65535, unit=Unit_None, transfer-property=PENDING, to Zone_VR(timeout 3.5 s)  # IST-Position des Aktuators
          signal ACT109a_Verfahrrichtung_XIX_ACTs_109a_Status_XIX_Zone_VR_LIN11: start 40, 2 bit, little-endian, data-type-policy=OVERRIDE, i-signal-type=PRIMITIVE, init-value=2, base-type=BT_ACT109a_Verfahrrichtung, invalid-value=Invalid_ACT109a_Verfahrrichtung_XIX_ACTs_109a_Status_XIX_Zone_VR_LIN11:3, compu {3=Cx3_Fehler, 0=Cx0_Richtung_kl_Schrittpositionen, 2=Cx2_Init, 1=Cx1_Richtung_gr_Schrittpositionen}, range raw 0..3, transfer-property=PENDING, to Zone_VR(timeout 3.5 s)  # Verfahrrichtung der aktuellen oder zuletzt stattgefundenen Bewegung des Aktuators
          signal ACT109a_Selbsthaltemoment_XIX_ACTs_109a_Status_XIX_Zone_VR_LIN11: start 42, 2 bit, little-endian, data-type-policy=OVERRIDE, i-signal-type=PRIMITIVE, init-value=0, base-type=BT_ACT109a_Selbsthaltemoment, invalid-value=Invalid_ACT109a_Selbsthaltemoment_XIX_ACTs_109a_Status_XIX_Zone_VR_LIN11:3, compu {3=Cx3_Fehler, 1=Cx1_mit_Selbsthaltemoment, 0=Cx0_ohne_Selbsthaltemoment, 2=Cx2_reserviert}, range raw 0..3, transfer-property=PENDING, to Zone_VR(timeout 3.5 s)  # Das Signal gibt an ob ein selbsthemmendes Getriebe verbaut ist oder die SHB eingeschaltet ist
          signal ACT109a_Sonderfunktionen_XIX_ACTs_109a_Status_XIX_Zone_VR_LIN11: start 44, 2 bit, little-endian, data-type-policy=OVERRIDE, i-signal-type=PRIMITIVE, init-value=0, base-type=BT_ACT109a_Sonderfunktionen, invalid-value=Invalid_ACT109a_Sonderfunktionen_XIX_ACTs_109a_Status_XIX_Zone_VR_LIN11:3, compu {3=Cx3_Fehler, 0=Cx0_Keine_Sonderfunktion_aktiv, 2=Cx2_Sonderfunktion2_aktiv, 1=Cx1_Sonderfunktion1_aktiv}, range raw 0..3, transfer-property=PENDING, to Zone_VR(timeout 3.5 s)  # Funktionen des Aktuators
          signal ACT109a_Variante_XIX_ACTs_109a_Status_XIX_Zone_VR_LIN11: start 46, 2 bit, little-endian, data-type-policy=OVERRIDE, i-signal-type=PRIMITIVE, init-value=0, base-type=BT_ACT109a_Variante, compu {1=Cx1_Variante_2, 0=Cx0_Variante_1, 2=Cx2_Variante_3, 3=Cx3_Fehler_oder_nicht_umgesetzt}, range raw 0..3, transfer-property=PENDING, to Zone_VR(timeout 3.5 s)  # Das Signal gibt an welche Variante des Stellmotors verbaut ist
          signal ACT109a_Adresse_Aktuator_XIX_ACTs_109a_Status_XIX_Zone_VR_LIN11: start 48, 8 bit, little-endian, data-type-policy=OVERRIDE, i-signal-type=PRIMITIVE, init-value=255, base-type=BT_ACT109a_Adresse_Aktuator, compu {255=Cxff_Init}, range raw 255, transfer-property=PENDING, to Zone_VR(timeout 3.5 s)  # Adresse Aktuator
          signal ACT109a_Notlauffreigabe_XIX_ACTs_109a_Status_XIX_Zone_VR_LIN11: start 56, 2 bit, little-endian, data-type-policy=OVERRIDE, i-signal-type=PRIMITIVE, init-value=0, base-type=BT_ACT109a_Notlauffreigabe, invalid-value=Invalid_ACT109a_Notlauffreigabe_XIX_ACTs_109a_Status_XIX_Zone_VR_LIN11:3, compu {3=Cx3_Fehler, 1=Cx1_Notlauf_ein, 0=Cx0_Notlauf_aus, 2=Cx2_reserviert}, range raw 0..3, transfer-property=PENDING, to Zone_VR(timeout 3.5 s)  # Freigabe der Notlauffunktion des Aktuators
          signal ACT109a_Notlaufposition_XIX_ACTs_109a_Status_XIX_Zone_VR_LIN11: start 58, 2 bit, little-endian, data-type-policy=OVERRIDE, i-signal-type=PRIMITIVE, init-value=0, base-type=BT_ACT109a_Notlaufposition, invalid-value=Invalid_ACT109a_Notlaufposition_XIX_ACTs_109a_Status_XIX_Zone_VR_LIN11:3, compu {3=Cx3_Fehler, 2=Cx2_reserviert, 0=Cx0_unterer_Anschlag, 1=Cx1_oberer_Anschlag}, range raw 0..3, transfer-property=PENDING, to Zone_VR(timeout 3.5 s)  # Positionsvorgabe des Aktuators
          signal ACT109a_Drehrichtung_XIX_ACTs_109a_Status_XIX_Zone_VR_LIN11: start 60, 2 bit, little-endian, data-type-policy=OVERRIDE, i-signal-type=PRIMITIVE, init-value=0, base-type=BT_ACT109a_Drehrichtung, invalid-value=Invalid_ACT109a_Drehrichtung_XIX_ACTs_109a_Status_XIX_Zone_VR_LIN11:3, compu {3=Cx3_Fehler, 0=Cx0_Bewegung_in_Richtung_CW, 1=Cx1_Bewegung_in_Richtung_CCW, 2=Cx2_reserviert}, range raw 0..3, transfer-property=PENDING, to Zone_VR(timeout 3.5 s)  # Drehrichtung des Aktuators
          signal ACT109a_Stopmodus_XIX_ACTs_109a_Status_XIX_Zone_VR_LIN11: start 62, 2 bit, little-endian, data-type-policy=OVERRIDE, i-signal-type=PRIMITIVE, init-value=0, base-type=BT_ACT109a_Stopmodus, invalid-value=Invalid_ACT109a_Stopmodus_XIX_ACTs_109a_Status_XIX_Zone_VR_LIN11:3, compu {3=Cx3_Fehler, 2=Cx2_reserviert, 0=Cx0_Normal_Mode, 1=Cx1_Stop_Mode}, range raw 0..3, transfer-property=PENDING, to Zone_VR(timeout 3.5 s)  # Modus des Aktuators
      frame MasterReq_XIX_Zone_VR_LIN11: id 0x3C, from Zone_VR, frame-length=8, lin-checksum=CLASSIC
        n pdu MasterReq_XIX_Zone_VR_LIN11: length=8
      frame SlaveResp_XIX_Zone_VR_LIN11: id 0x3D, to Zone_VR, frame-length=8, lin-checksum=CLASSIC
        n pdu SlaveResp_XIX_Zone_VR_LIN11: length=8
      7 x lin schedule table, all with resume-position=CONTINUE-AT-IT-POSITION:
        ST1: run-mode=RUN-CONTINUOUS
          table-entrys:
            delay=0.01, position-in-table=0, frame-triggering=FT_ACTe_104a_Control
            delay=0.01, position-in-table=1, frame-triggering=FT_ACTs_109a_Status
            delay=0.01, position-in-table=2, frame-triggering=FT_ACTe_105a_Control
            delay=0.01, position-in-table=3, frame-triggering=FT_ACTs_104a_Status
            delay=0.01, position-in-table=4, frame-triggering=FT_ACTe_106a_Control
            delay=0.01, position-in-table=5, frame-triggering=FT_ACTs_105a_Status
            delay=0.01, position-in-table=6, frame-triggering=FT_ACTe_109a_Control
            delay=0.01, position-in-table=7, frame-triggering=FT_ACTs_106a_Status
        Status: run-mode=RUN-CONTINUOUS
          table-entrys:
            delay=0.01, position-in-table=0, frame-triggering=FT_ACTs_104a_Status
            delay=0.01, position-in-table=1, frame-triggering=FT_ACTs_105a_Status
            delay=0.01, position-in-table=2, frame-triggering=FT_ACTs_106a_Status
            delay=0.01, position-in-table=3, frame-triggering=FT_ACTs_109a_Status
        Broadcast: run-mode=RUN-CONTINUOUS, application-entry{delay=0.01, position-in-table=0, frame-triggering=FT_ACTe_100a_Broadcast_Ctrl}
        DiagRequest: run-mode=RUN-ONCE, application-entry{delay=0.01, position-in-table=0, frame-triggering=CHNL/FT_MasterReq}
        DiagResponse: run-mode=RUN-ONCE, application-entry{delay=0.01, position-in-table=0, frame-triggering=CHNL/FT_SlaveResp}
        FlashRequest: run-mode=RUN-ONCE, application-entry{delay=0.01, position-in-table=0, frame-triggering=CHNL/FT_MasterReq}
        FlashResponse: run-mode=RUN-ONCE, application-entry{delay=0.01, position-in-table=0, frame-triggering=CHNL/FT_SlaveResp}
  lin cluster Zone_VR_LIN06: baudrate=19200, protocol-name=LIN, protocol-version=2.0
    lin physical channel CHNL: comm-connectors=CN_Zone_VR_LIN06
      frame KPHe_01_XIX_Zone_VR_LIN06: id 0x9, from Zone_VR, frame-length=8, lin-checksum=ENHANCED
        pdu KPHe_01_XIX_Zone_VR_LIN06: length=8, unused-bit-pattern=0
          signal KPHe_Funktion_Off_XIX_KPHe_01_XIX_Zone_VR_LIN06: start 0, 1 bit, little-endian, data-type-policy=OVERRIDE, i-signal-type=PRIMITIVE, init-value=0, base-type=BT_KPHe_Funktion_Off, compu {0=Cx0_inaktiv, 1=Cx1_aktiv}, range raw 0..1, transfer-property=PENDING  # Status für Funktion Off
          signal KPHe_Funktion_Frontbedienung_XIX_KPHe_01_XIX_Zone_VR_LIN06: start 1, 1 bit, little-endian, data-type-policy=OVERRIDE, i-signal-type=PRIMITIVE, init-value=0, base-type=BT_KPHe_Funktion_Frontbedienung, compu {0=Cx0_inaktiv, 1=Cx1_aktiv}, range raw 0..1, transfer-property=PENDING  # Status für Funktion Frontbedienung
          signal KPHe_Funktion_Umluft_XIX_KPHe_01_XIX_Zone_VR_LIN06: start 2, 1 bit, little-endian, data-type-policy=OVERRIDE, i-signal-type=PRIMITIVE, init-value=0, base-type=BT_KPHe_Funktion_Umluft, compu {0=Cx0_inaktiv, 1=Cx1_aktiv}, range raw 0..1, transfer-property=PENDING  # Status für Funktion Umluft
          signal KPHe_Funktion_AC_XIX_KPHe_01_XIX_Zone_VR_LIN06: start 3, 1 bit, little-endian, data-type-policy=OVERRIDE, i-signal-type=PRIMITIVE, init-value=0, base-type=BT_KPHe_Funktion_AC, compu {0=Cx0_inaktiv, 1=Cx1_aktiv}, range raw 0..1, transfer-property=PENDING  # Status für Funktion AC
          signal KPHe_Funktion_AC_max_XIX_KPHe_01_XIX_Zone_VR_LIN06: start 4, 1 bit, little-endian, data-type-policy=OVERRIDE, i-signal-type=PRIMITIVE, init-value=0, base-type=BT_KPHe_Funktion_AC_max, compu {0=Cx0_inaktiv, 1=Cx1_aktiv}, range raw 0..1, transfer-property=PENDING  # Status für Funktion AC max
          signal KPHe_Funktion_ECO_XIX_KPHe_01_XIX_Zone_VR_LIN06: start 5, 1 bit, little-endian, data-type-policy=OVERRIDE, i-signal-type=PRIMITIVE, init-value=0, base-type=BT_KPHe_Funktion_ECO, compu {0=Cx0_inaktiv, 1=Cx1_aktiv}, range raw 0..1, transfer-property=PENDING  # Status für Funktion ECO
          signal KPHe_Lenker_Position_XIX_KPHe_01_XIX_Zone_VR_LIN06: start 6, 1 bit, little-endian, data-type-policy=OVERRIDE, i-signal-type=PRIMITIVE, init-value=0, base-type=BT_KPHe_Lenker_Position, compu {1=Cx1_Rechtslenker, 0=Cx0_Linkslenker}, range raw 0..1, transfer-property=PENDING  # Lenker Position
          signal KPHe_Funktion_Auto_li_XIX_KPHe_01_XIX_Zone_VR_LIN06: start 7, 1 bit, little-endian, data-type-policy=OVERRIDE, i-signal-type=PRIMITIVE, init-value=0, base-type=BT_KPHe_Funktion_Auto_li, compu {0=Cx0_inaktiv, 1=Cx1_aktiv}, range raw 0..1, transfer-property=PENDING  # Status für Funktion Auto li
          signal KPHe_Funktion_Auto_re_XIX_KPHe_01_XIX_Zone_VR_LIN06: start 8, 1 bit, little-endian, data-type-policy=OVERRIDE, i-signal-type=PRIMITIVE, init-value=0, base-type=BT_KPHe_Funktion_Auto_re, compu {0=Cx0_inaktiv, 1=Cx1_aktiv}, range raw 0..1, transfer-property=PENDING  # Status für Funktion Auto re
          signal KPHe_Stellgliedtest_XIX_KPHe_01_XIX_Zone_VR_LIN06: start 9, 1 bit, little-endian, data-type-policy=OVERRIDE, i-signal-type=PRIMITIVE, init-value=0, base-type=BT_KPHe_Stellgliedtest, compu {0=Cx0_inaktiv, 1=Cx1_aktiv}, range raw 0..1, transfer-property=PENDING  # Status für Diagnose Funktion Stellgliedtest
          signal KPHe_Einheit_XIX_KPHe_01_XIX_Zone_VR_LIN06: start 10, 1 bit, little-endian, data-type-policy=OVERRIDE, i-signal-type=PRIMITIVE, init-value=0, base-type=BT_KPHe_Einheit, compu {1=Cx1_Fahrenheit, 0=Cx0_Celsius}, range raw 0..1, transfer-property=PENDING  # Einheit der Temperaturdarstellung
          signal KL_KST_KL_15_XIX_KPHe_01_XIX_Zone_VR_LIN06: start 11, 1 bit, little-endian, data-type-policy=OVERRIDE, i-signal-type=PRIMITIVE, init-value=0, base-type=BT_KL_KST_KL_15, compu {0=Cx0_Aus, 1=Cx1_Ein}, range raw 0..1, transfer-property=PENDING  # Klemme 15: Zuendung (SW-Kl.15) (geroutet)
          signal KPHe_Funktion_Ionisator_XIX_KPHe_01_XIX_Zone_VR_LIN06: start 12, 1 bit, little-endian, data-type-policy=OVERRIDE, i-signal-type=PRIMITIVE, init-value=0, base-type=BT_KPHe_Funktion_Ionisator, compu {0=Cx0_inaktiv, 1=Cx1_aktiv}, range raw 0..1, transfer-property=PENDING  # Status für Funktion Ionisator
          signal KPHe_Funktion_Beduftung_XIX_KPHe_01_XIX_Zone_VR_LIN06: start 13, 1 bit, little-endian, data-type-policy=OVERRIDE, i-signal-type=PRIMITIVE, init-value=0, base-type=BT_KPHe_Funktion_Beduftung, compu {0=Cx0_inaktiv, 1=Cx1_aktiv}, range raw 0..1, transfer-property=PENDING  # Status für Funktion Beduftung
          signal KPHe_Funktion_Flaechenheizung_XIX_KPHe_01_XIX_Zone_VR_LIN06: start 14, 1 bit, little-endian, data-type-policy=OVERRIDE, i-signal-type=PRIMITIVE, init-value=0, base-type=BT_KPHe_Funktion_Flaechenheizung, compu {0=Cx0_inaktiv, 1=Cx1_aktiv}, range raw 0..1, transfer-property=PENDING  # Status für Funktion Flächenheizung
          signal KPHe_Funktion_Kindersicherung_XIX_KPHe_01_XIX_Zone_VR_LIN06: start 16, 1 bit, little-endian, data-type-policy=OVERRIDE, i-signal-type=PRIMITIVE, init-value=0, base-type=BT_KPHe_Funktion_Kindersicherung, compu {0=Cx0_inaktiv, 1=Cx1_aktiv}, range raw 0..1, transfer-property=PENDING  # Status der Funktion Kindersicherung
          signal KPHe_Funktion_Sync_XIX_KPHe_01_XIX_Zone_VR_LIN06: start 17, 1 bit, little-endian, data-type-policy=OVERRIDE, i-signal-type=PRIMITIVE, init-value=0, base-type=BT_KPHe_Funktion_Sync, compu {0=Cx0_inaktiv, 1=Cx1_aktiv}, range raw 0..1, transfer-property=PENDING  # Status für Funktion Sync
          signal KPHe_Fondbedienung_XIX_KPHe_01_XIX_Zone_VR_LIN06: start 18, 1 bit, little-endian, data-type-policy=OVERRIDE, i-signal-type=PRIMITIVE, init-value=0, base-type=BT_KPHe_Fondbedienung, compu {0=Cx0_inaktiv, 1=Cx1_aktiv}, range raw 0..1, transfer-property=PENDING  # Status für Fondbedienung
          signal KPHe_Radio_Frequenz_XIX_KPHe_01_XIX_Zone_VR_LIN06: start 19, 5 bit, little-endian, data-type-policy=OVERRIDE, i-signal-type=PRIMITIVE, init-value=30, base-type=BT_KPHe_Radio_Frequenz, compu {18=Cx12_RA_Frequenzbereich_18, 29=Cx1d_Radio_mute_oder_aus, 17=Cx11_RA_Frequenzbereich_17, 31=Cx1f_Fehler_oder_nicht_umgesetzt, 16=Cx10_RA_Frequenzbereich_16, 1=Cx1_RA_Frequenzbereich_01, 10=Cxa_RA_Frequenzbereich_10, 21=Cx15_RA_Frequenzbereich_21, 13=Cxd_RA_Frequenzbereich_13, 8=Cx8_RA_Frequenzbereich_08, 7=Cx7_RA_Frequenzbereich_07, 23=Cx17_RA_Frequenzbereich_23, 4=Cx4_RA_Frequenzbereich_04, 25=Cx19_RA_Frequenzbereich_25, 3=Cx3_RA_Frequenzbereich_03, 24=Cx18_RA_Frequenzbereich_24, 11=Cxb_RA_Frequenzbereich_11, 9=Cx9_RA_Frequenzbereich_09, 2=Cx2_RA_Frequenzbereich_02, 0=Cx0_RA_Frequenzbereich_00, 26=Cx1a_RA_Frequenzbereich_26, 6=Cx6_RA_Frequenzbereich_06, 19=Cx13_RA_Frequenzbereich_19, 15=Cxf_RA_Frequenzbereich_15, 20=Cx14_RA_Frequenzbereich_20, 14=Cxe_RA_Frequenzbereich_14, 22=Cx16_RA_Frequenzbereich_22, 12=Cxc_RA_Frequenzbereich_12, 28=Cx1c_Suchlauf_aktiv, 27=Cx1b_RA_Frequenzbereich_27, 30=Cx1e_Init, 5=Cx5_RA_Frequenzbereich_05}, range raw 0..31, transfer-property=PENDING  # aktuelle Radiofrequenz
          signal KPHe_Suchbeleuchtung_XIX_KPHe_01_XIX_Zone_VR_LIN06: start 24, 1 bit, little-endian, data-type-policy=OVERRIDE, i-signal-type=PRIMITIVE, init-value=0, base-type=BT_KPHe_Suchbeleuchtung, compu {0=Cx0_Aus, 1=Cx1_Ein}, range raw 0..1, transfer-property=PENDING  # Status für Suchbeleuchtung
          signal KPHe_Funktionsbeleuchtung_XIX_KPHe_01_XIX_Zone_VR_LIN06: start 25, 1 bit, little-endian, data-type-policy=OVERRIDE, i-signal-type=PRIMITIVE, init-value=0, base-type=BT_KPHe_Funktionsbeleuchtung, compu {0=Cx0_Aus, 1=Cx1_Ein}, range raw 0..1, transfer-property=PENDING  # Status für Funktionsbeleuchtung
          signal KPHe_Symbol_Sitzheizung_li_XIX_KPHe_01_XIX_Zone_VR_LIN06: start 26, 1 bit, little-endian, data-type-policy=OVERRIDE, i-signal-type=PRIMITIVE, init-value=0, base-type=BT_KPHe_Symbol_Sitzheizung_li, compu {0=Cx0_Aus, 1=Cx1_Ein}, range raw 0..1, transfer-property=PENDING  # Status für Symbol Sitzheizung links
          signal KPHe_Symbol_Sitzheizung_re_XIX_KPHe_01_XIX_Zone_VR_LIN06: start 27, 1 bit, little-endian, data-type-policy=OVERRIDE, i-signal-type=PRIMITIVE, init-value=0, base-type=BT_KPHe_Symbol_Sitzheizung_re, compu {1=Cx1_Ein, 0=Cx0_Aus}, range raw 0..1, transfer-property=PENDING  # Status für Symbol Sitzheizung rechts
          signal KPHe_Symbol_Sitzlueftung_li_XIX_KPHe_01_XIX_Zone_VR_LIN06: start 28, 1 bit, little-endian, data-type-policy=OVERRIDE, i-signal-type=PRIMITIVE, init-value=0, base-type=BT_KPHe_Symbol_Sitzlueftung_li, compu {1=Cx1_Ein, 0=Cx0_Aus}, range raw 0..1, transfer-property=PENDING  # Status für Symbol Sitzlüftung links
          signal KPHe_Symbol_Sitzlueftung_re_XIX_KPHe_01_XIX_Zone_VR_LIN06: start 29, 1 bit, little-endian, data-type-policy=OVERRIDE, i-signal-type=PRIMITIVE, init-value=0, base-type=BT_KPHe_Symbol_Sitzlueftung_re, compu {0=Cx0_Aus, 1=Cx1_Ein}, range raw 0..1, transfer-property=PENDING  # Status für Symbol Sitzlüftung rechts
          signal KPHe_Funktion_ECO_Zone_XIX_KPHe_01_XIX_Zone_VR_LIN06: start 30, 2 bit, little-endian, data-type-policy=OVERRIDE, i-signal-type=PRIMITIVE, init-value=0, base-type=BT_KPHe_Funktion_ECO_Zone, compu {1=Cx1_hinten_rechts, 2=Cx2_hinten_links, 0=Cx0_Init, 3=Cx3_hinten_links_und_rechts}, range raw 0..3, transfer-property=PENDING  # Status für Anzeige ECO am Klimapanel
          signal KPHe_Funktion_Halbkreis_li_XIX_KPHe_01_XIX_Zone_VR_LIN06: start 32, 1 bit, little-endian, data-type-policy=OVERRIDE, i-signal-type=PRIMITIVE, init-value=0, base-type=BT_KPHe_Funktion_Halbkreis_li, compu {0=Cx0_inaktiv, 1=Cx1_aktiv}, range raw 0..1, transfer-property=PENDING  # Status für Funktion Halbkreis li
          signal KPHe_Funktion_Halbkreis_re_XIX_KPHe_01_XIX_Zone_VR_LIN06: start 33, 1 bit, little-endian, data-type-policy=OVERRIDE, i-signal-type=PRIMITIVE, init-value=0, base-type=BT_KPHe_Funktion_Halbkreis_re, compu {0=Cx0_inaktiv, 1=Cx1_aktiv}, range raw 0..1, transfer-property=PENDING  # Status für Funktion Halbkreis re
          signal KPHe_Sitzheizung_li_XIX_KPHe_01_XIX_Zone_VR_LIN06: start 34, 3 bit, little-endian, data-type-policy=OVERRIDE, i-signal-type=PRIMITIVE, init-value=0, base-type=BT_KPHe_Sitzheizung_li, compu {3=Cx3_Stufe_3, 5=Cx5_Stufe_5, 4=Cx4_Stufe_4, 0=Cx0_Stufe_0, 6=Cx6_Stufe_6, 2=Cx2_Stufe_2, 1=Cx1_Stufe_1}, range raw 0..6, transfer-property=PENDING  # Status der Sitzheizung li
          signal KPHe_Sitzheizung_re_XIX_KPHe_01_XIX_Zone_VR_LIN06: start 37, 3 bit, little-endian, data-type-policy=OVERRIDE, i-signal-type=PRIMITIVE, init-value=0, base-type=BT_KPHe_Sitzheizung_re, compu {0=Cx0_Stufe_0, 3=Cx3_Stufe_3, 2=Cx2_Stufe_2, 6=Cx6_Stufe_6, 5=Cx5_Stufe_5, 1=Cx1_Stufe_1, 4=Cx4_Stufe_4}, range raw 0..6, transfer-property=PENDING  # Status der Sitzheizung re
          signal KPHe_LCD_XIX_KPHe_01_XIX_Zone_VR_LIN06: start 40, 1 bit, little-endian, data-type-policy=OVERRIDE, i-signal-type=PRIMITIVE, init-value=0, base-type=BT_KPHe_LCD, compu {0=Cx0_Aus, 1=Cx1_Ein}, range raw 0..1, transfer-property=PENDING  # Status für LCD
          signal KPHe_TFT_XIX_KPHe_01_XIX_Zone_VR_LIN06: start 41, 1 bit, little-endian, data-type-policy=OVERRIDE, i-signal-type=PRIMITIVE, init-value=0, base-type=BT_KPHe_TFT, compu {0=Cx0_Aus, 1=Cx1_Ein}, range raw 0..1, transfer-property=PENDING  # Status für TFT
          signal KPHe_Sitzlueftung_li_XIX_KPHe_01_XIX_Zone_VR_LIN06: start 42, 3 bit, little-endian, data-type-policy=OVERRIDE, i-signal-type=PRIMITIVE, init-value=0, base-type=BT_KPHe_Sitzlueftung_li, compu {1=Cx1_Stufe_1, 5=Cx5_Stufe_5, 3=Cx3_Stufe_3, 0=Cx0_Stufe_0, 2=Cx2_Stufe_2, 6=Cx6_Stufe_6, 4=Cx4_Stufe_4}, range raw 0..6, transfer-property=PENDING  # Status der Sitzlüftung li
          signal KPHe_Sitzlueftung_re_XIX_KPHe_01_XIX_Zone_VR_LIN06: start 45, 3 bit, little-endian, data-type-policy=OVERRIDE, i-signal-type=PRIMITIVE, init-value=0, base-type=BT_KPHe_Sitzlueftung_re, compu {6=Cx6_Stufe_6, 5=Cx5_Stufe_5, 2=Cx2_Stufe_2, 4=Cx4_Stufe_4, 3=Cx3_Stufe_3, 1=Cx1_Stufe_1, 0=Cx0_Stufe_0}, range raw 0..6, transfer-property=PENDING  # Status der Sitzlüftung re
          signal KPHe_Temp_li_XIX_KPHe_01_XIX_Zone_VR_LIN06: start 48, 8 bit, little-endian, data-type-policy=OVERRIDE, i-signal-type=PRIMITIVE, init-value=0, base-type=BT_KPHe_Temp_li, invalid-value=Invalid_KPHe_Temp_li_XIX_KPHe_01_XIX_Zone_VR_LIN06:255, compu {phys=raw*0.1+10 for raw 0..254, 255=Cxff_Fehler; unit Unit_DegreCelsi}, range phys 10..35.4 Unit_DegreCelsi, raw 0..255, unit=Unit_DegreCelsi, transfer-property=PENDING  # Eingestellte Temperatur links
          signal KPHe_Temp_re_XIX_KPHe_01_XIX_Zone_VR_LIN06: start 56, 8 bit, little-endian, data-type-policy=OVERRIDE, i-signal-type=PRIMITIVE, init-value=0, base-type=BT_KPHe_Temp_re, invalid-value=Invalid_KPHe_Temp_re_XIX_KPHe_01_XIX_Zone_VR_LIN06:255, compu {phys=raw*0.1+10 for raw 0..254, 255=Cxff_Fehler; unit Unit_DegreCelsi}, range phys 10..35.4 Unit_DegreCelsi, raw 0..255, unit=Unit_DegreCelsi, transfer-property=PENDING  # Eingestellte Temperatur rechts
      frame KPHe_02_XIX_Zone_VR_LIN06: id 0xA, from Zone_VR, frame-length=8, lin-checksum=ENHANCED
        pdu KPHe_02_XIX_Zone_VR_LIN06: length=8, unused-bit-pattern=0
          signal KPHe_Symbol_Luftmenge_li_XIX_KPHe_02_XIX_Zone_VR_LIN06: start 0, 1 bit, little-endian, data-type-policy=OVERRIDE, i-signal-type=PRIMITIVE, init-value=0, base-type=BT_KPHe_Symbol_Luftmenge_li, compu {0=Cx0_Aus, 1=Cx1_Ein}, range raw 0..1, transfer-property=PENDING  # Status für Symbol Luftmenge li
          signal KPHe_Symbol_Luftmenge_re_XIX_KPHe_02_XIX_Zone_VR_LIN06: start 1, 1 bit, little-endian, data-type-policy=OVERRIDE, i-signal-type=PRIMITIVE, init-value=0, base-type=BT_KPHe_Symbol_Luftmenge_re, compu {0=Cx0_Aus, 1=Cx1_Ein}, range raw 0..1, transfer-property=PENDING  # Status für Symbol Luftmenge re
          signal KPHe_Symbol_Luftverteilung_li_XIX_KPHe_02_XIX_Zone_VR_LIN06: start 2, 1 bit, little-endian, data-type-policy=OVERRIDE, i-signal-type=PRIMITIVE, init-value=0, base-type=BT_KPHe_Symbol_Luftverteilung_li, compu {0=Cx0_Aus, 1=Cx1_Ein}, range raw 0..1, transfer-property=PENDING  # Status für Symbol Luftverteilung li
          signal KPHe_Symbol_Luftverteilung_re_XIX_KPHe_02_XIX_Zone_VR_LIN06: start 3, 1 bit, little-endian, data-type-policy=OVERRIDE, i-signal-type=PRIMITIVE, init-value=0, base-type=BT_KPHe_Symbol_Luftverteilung_re, compu {0=Cx0_Aus, 1=Cx1_Ein}, range raw 0..1, transfer-property=PENDING  # Status für Symbol Luftverteilung re
          signal KPHe_Geblaese_Stufe_li_XIX_KPHe_02_XIX_Zone_VR_LIN06: start 4, 4 bit, little-endian, data-type-policy=OVERRIDE, i-signal-type=PRIMITIVE, init-value=0, base-type=BT_KPHe_Geblaese_Stufe_li, compu {2=Cx2_Geblaese_Stufe_2, 10=Cxa_Geblaese_Stufe_10, 3=Cx3_Geblaese_Stufe_3, 11=Cxb_Geblaese_Stufe_11, 12=Cxc_Geblaese_Stufe_12, 0=Cx0_Geblaese_Stufe_0, 9=Cx9_Geblaese_Stufe_9, 7=Cx7_Geblaese_Stufe_7, 6=Cx6_Geblaese_Stufe_6, 1=Cx1_Geblaese_Stufe_1, 8=Cx8_Geblaese_Stufe_8, 4=Cx4_Geblaese_Stufe_4, 5=Cx5_Geblaese_Stufe_5}, range raw 0..12, transfer-property=PENDING  # Status Geblaese Stufe links am Klimapanel
          signal KPHe_Geblaese_Stufe_re_XIX_KPHe_02_XIX_Zone_VR_LIN06: start 8, 4 bit, little-endian, data-type-policy=OVERRIDE, i-signal-type=PRIMITIVE, init-value=0, base-type=BT_KPHe_Geblaese_Stufe_re, compu {10=Cxa_Geblaese_Stufe_10, 4=Cx4_Geblaese_Stufe_4, 5=Cx5_Geblaese_Stufe_5, 11=Cxb_Geblaese_Stufe_11, 1=Cx1_Geblaese_Stufe_1, 9=Cx9_Geblaese_Stufe_9, 7=Cx7_Geblaese_Stufe_7, 0=Cx0_Geblaese_Stufe_0, 12=Cxc_Geblaese_Stufe_12, 2=Cx2_Geblaese_Stufe_2, 8=Cx8_Geblaese_Stufe_8, 6=Cx6_Geblaese_Stufe_6, 3=Cx3_Geblaese_Stufe_3}, range raw 0..12, transfer-property=PENDING  # Status Geblaese Stufe rechts am Klimapanel
          signal KPHe_Luftverteilung_Oben_li_XIX_KPHe_02_XIX_Zone_VR_LIN06: start 12, 1 bit, little-endian, data-type-policy=OVERRIDE, i-signal-type=PRIMITIVE, init-value=0, base-type=BT_KPHe_Luftverteilung_Oben_li, compu {0=Cx0_inaktiv, 1=Cx1_aktiv}, range raw 0..1, transfer-property=PENDING  # Status für Luftverteilung Oben li
          signal KPHe_Luftverteilung_Mitte_li_XIX_KPHe_02_XIX_Zone_VR_LIN06: start 13, 1 bit, little-endian, data-type-policy=OVERRIDE, i-signal-type=PRIMITIVE, init-value=0, base-type=BT_KPHe_Luftverteilung_Mitte_li, compu {0=Cx0_inaktiv, 1=Cx1_aktiv}, range raw 0..1, transfer-property=PENDING  # Status für Luftverteilung Mitte li
          signal KPHe_Luftverteilung_Unten_li_XIX_KPHe_02_XIX_Zone_VR_LIN06: start 14, 1 bit, little-endian, data-type-policy=OVERRIDE, i-signal-type=PRIMITIVE, init-value=0, base-type=BT_KPHe_Luftverteilung_Unten_li, compu {0=Cx0_inaktiv, 1=Cx1_aktiv}, range raw 0..1, transfer-property=PENDING  # Status für Luftverteilung Unten li
          signal KPHe_Luftverteilung_Auto_li_XIX_KPHe_02_XIX_Zone_VR_LIN06: start 15, 1 bit, little-endian, data-type-policy=OVERRIDE, i-signal-type=PRIMITIVE, init-value=0, base-type=BT_KPHe_Luftverteilung_Auto_li, compu {0=Cx0_inaktiv, 1=Cx1_aktiv}, range raw 0..1, transfer-property=PENDING  # Status für Luftverteilung Auto li
          signal KPHe_Luftverteilung_Oben_re_XIX_KPHe_02_XIX_Zone_VR_LIN06: start 16, 1 bit, little-endian, data-type-policy=OVERRIDE, i-signal-type=PRIMITIVE, init-value=0, base-type=BT_KPHe_Luftverteilung_Oben_re, compu {0=Cx0_inaktiv, 1=Cx1_aktiv}, range raw 0..1, transfer-property=PENDING  # Status für Luftverteilung Oben re
          signal KPHe_Luftverteilung_Mitte_re_XIX_KPHe_02_XIX_Zone_VR_LIN06: start 17, 1 bit, little-endian, data-type-policy=OVERRIDE, i-signal-type=PRIMITIVE, init-value=0, base-type=BT_KPHe_Luftverteilung_Mitte_re, compu {0=Cx0_inaktiv, 1=Cx1_aktiv}, range raw 0..1, transfer-property=PENDING  # Status für Luftverteilung Mitte re
          signal KPHe_Luftverteilung_Unten_re_XIX_KPHe_02_XIX_Zone_VR_LIN06: start 18, 1 bit, little-endian, data-type-policy=OVERRIDE, i-signal-type=PRIMITIVE, init-value=0, base-type=BT_KPHe_Luftverteilung_Unten_re, compu {0=Cx0_inaktiv, 1=Cx1_aktiv}, range raw 0..1, transfer-property=PENDING  # Status für Luftverteilung Unten re
          signal KPHe_Luftverteilung_Auto_re_XIX_KPHe_02_XIX_Zone_VR_LIN06: start 19, 1 bit, little-endian, data-type-policy=OVERRIDE, i-signal-type=PRIMITIVE, init-value=0, base-type=BT_KPHe_Luftverteilung_Auto_re, compu {0=Cx0_inaktiv, 1=Cx1_aktiv}, range raw 0..1, transfer-property=PENDING  # Status für Luftverteilung Auto re
          signal KPHe_Fzg_Steigung_XIX_KPHe_02_XIX_Zone_VR_LIN06: start 24, 8 bit, little-endian, data-type-policy=OVERRIDE, i-signal-type=PRIMITIVE, init-value=0, base-type=BT_KPHe_Fzg_Steigung, invalid-value=Invalid_KPHe_Fzg_Steigung_XIX_KPHe_02_XIX_Zone_VR_LIN06:255, compu {phys=raw*0.8-101.6 for raw 1..254, 255=Cxff_Fehler, 0=Cx0_Init_oder_nicht_verbaut; unit Unit_PerCent}, range phys -100.8..101.6 Unit_PerCent, raw 0..255, unit=Unit_PerCent, transfer-property=PENDING  # Steigung in % Berg, Positive Werte > bergauf; Negative Werte < bergab
          signal KL_DI_KL_58xd_XIX_KPHe_02_XIX_Zone_VR_LIN06: start 32, 8 bit, little-endian, data-type-policy=OVERRIDE, i-signal-type=PRIMITIVE, init-value=254, base-type=BT_KL_DI_KL_58xd, invalid-value=Invalid_KL_DI_KL_58xd_XIX_KPHe_02_XIX_Zone_VR_LIN06:255, compu {phys=raw for raw 0..253, 255=Cxff_Fehler, 254=Cxfe_Init}, range phys 0..253, raw 0..255, transfer-property=PENDING  # Klemme 58xd Display- und Funkltionsbeleuchtung
          signal KL_DI_KL_58xs_XIX_KPHe_02_XIX_Zone_VR_LIN06: start 40, 7 bit, little-endian, data-type-policy=OVERRIDE, i-signal-type=PRIMITIVE, init-value=126, base-type=BT_KL_DI_KL_58xs, invalid-value=Invalid_KL_DI_KL_58xs_XIX_KPHe_02_XIX_Zone_VR_LIN06:127, compu {phys=raw for raw 0..100, 127=Cx7f_Fehler, 126=Cx7e_Init}, range phys 0..100, raw 0..127, transfer-property=PENDING  # Klemme 58xs Suchbeleuchtung
          signal KPHe_QBit_Steigung_XIX_KPHe_02_XIX_Zone_VR_LIN06: start 47, 1 bit, little-endian, data-type-policy=OVERRIDE, i-signal-type=PRIMITIVE, init-value=1, base-type=BT_KPHe_QBit_Steigung, compu {1=Cx1_Ersatz_Init_oder_Fehlerwert, 0=Cx0_gueltiger_Wert}, range raw 0..1, transfer-property=PENDING  # Q-Bit für Fzg-Steigung
          signal KPHe_Funktion_Defrost_XIX_KPHe_02_XIX_Zone_VR_LIN06: start 59, 1 bit, little-endian, data-type-policy=OVERRIDE, i-signal-type=PRIMITIVE, init-value=0, base-type=BT_KPHe_Funktion_Defrost, compu {1=Cx1_aktiv, 0=Cx0_inaktiv}, range raw 0..1, transfer-property=PENDING  # Funktion Defrost aktiv
          signal KPHe_Geblaese_Begrenzung_XIX_KPHe_02_XIX_Zone_VR_LIN06: start 60, 1 bit, little-endian, data-type-policy=OVERRIDE, i-signal-type=PRIMITIVE, init-value=0, base-type=BT_KPHe_Geblaese_Begrenzung, compu {1=Cx1_begrenzung_aktiv, 0=Cx0_keine_begrenzung}, range raw 0..1, transfer-property=PENDING  # Steuerung der Begrenzung der Geblaesestufen im KPH, z.B. Bei KL15 ein ohne Motorlauf, Start/Stop, o.ä.
          signal KPHe_Geblaese_Auto_re_XIX_KPHe_02_XIX_Zone_VR_LIN06: start 61, 1 bit, little-endian, data-type-policy=OVERRIDE, i-signal-type=PRIMITIVE, init-value=0, base-type=BT_KPHe_Geblaese_Auto_re, compu {0=Cx0_inaktiv, 1=Cx1_aktiv}, range raw 0..1, transfer-property=PENDING  # Status für Gebläse Auto rechts
          signal KPHe_Geblaese_Auto_li_XIX_KPHe_02_XIX_Zone_VR_LIN06: start 62, 1 bit, little-endian, data-type-policy=OVERRIDE, i-signal-type=PRIMITIVE, init-value=0, base-type=BT_KPHe_Geblaese_Auto_li, compu {0=Cx0_inaktiv, 1=Cx1_aktiv}, range raw 0..1, transfer-property=PENDING  # Status für Gebläse Auto links
          signal KPHe_Auto_Toggle_XIX_KPHe_02_XIX_Zone_VR_LIN06: start 63, 1 bit, little-endian, data-type-policy=OVERRIDE, i-signal-type=PRIMITIVE, init-value=0, base-type=BT_KPHe_Auto_Toggle, compu {1=Cx1_aktiv, 0=Cx0_inaktiv}, range raw 0..1, transfer-property=PENDING  # Status der Konfiguration der Auto-Toggle-Funktion (Parametrierung im BCM)
      frame KPHs_01_XIX_Zone_VR_LIN06: id 0xC, to Zone_VR, frame-length=8, lin-checksum=ENHANCED
        pdu KPHs_01_XIX_Zone_VR_LIN06: length=8, unused-bit-pattern=0
          signal KPH_Off_XIX_KPHs_01_XIX_Zone_VR_LIN06: start 0, 1 bit, little-endian, data-type-policy=OVERRIDE, i-signal-type=PRIMITIVE, init-value=0, base-type=BT_KPH_Off, compu {1=Cx1_betaetigt, 0=Cx0_nicht_betaetigt}, range raw 0..1, transfer-property=PENDING, to Zone_VR(timeout 3.5 s)  # Auswahl der Funktion Off
          signal KPH_01_Init_XIX_KPHs_01_XIX_Zone_VR_LIN06: start 1, 1 bit, little-endian, data-type-policy=OVERRIDE, i-signal-type=PRIMITIVE, init-value=1, base-type=BT_KPH_01_Init, compu {0=Cx0_Normal_Betrieb, 1=Cx1_Init}, range raw 0..1, transfer-property=PENDING  # KPH_01_Init zeigt eine Initialisierung / Reset des KPHs an
          signal KPH_Umluft_XIX_KPHs_01_XIX_Zone_VR_LIN06: start 2, 1 bit, little-endian, data-type-policy=OVERRIDE, i-signal-type=PRIMITIVE, init-value=0, base-type=BT_KPH_Umluft, compu {1=Cx1_betaetigt, 0=Cx0_nicht_betaetigt}, range raw 0..1, transfer-property=PENDING, to Zone_VR(timeout 3.5 s)  # Auswahl der Funktion Umluft
          signal KPH_AC_XIX_KPHs_01_XIX_Zone_VR_LIN06: start 3, 1 bit, little-endian, data-type-policy=OVERRIDE, i-signal-type=PRIMITIVE, init-value=0, base-type=BT_KPH_AC, compu {1=Cx1_betaetigt, 0=Cx0_nicht_betaetigt}, range raw 0..1, transfer-property=PENDING, to Zone_VR(timeout 3.5 s)  # Auswahl der Funktion AC
          signal KPH_AC_max_XIX_KPHs_01_XIX_Zone_VR_LIN06: start 4, 1 bit, little-endian, data-type-policy=OVERRIDE, i-signal-type=PRIMITIVE, init-value=0, base-type=BT_KPH_AC_max, compu {1=Cx1_betaetigt, 0=Cx0_nicht_betaetigt}, range raw 0..1, transfer-property=PENDING, to Zone_VR(timeout 3.5 s)  # Auswahl der Funktion AC max
          signal KPH_ECO_XIX_KPHs_01_XIX_Zone_VR_LIN06: start 5, 1 bit, little-endian, data-type-policy=OVERRIDE, i-signal-type=PRIMITIVE, init-value=0, base-type=BT_KPH_ECO, compu {1=Cx1_betaetigt, 0=Cx0_nicht_betaetigt}, range raw 0..1, transfer-property=PENDING, to Zone_VR(timeout 3.5 s)  # Auswahl der Funktion ECO
          signal KPH_Auto_li_XIX_KPHs_01_XIX_Zone_VR_LIN06: start 7, 1 bit, little-endian, data-type-policy=OVERRIDE, i-signal-type=PRIMITIVE, init-value=0, base-type=BT_KPH_Auto_li, compu {1=Cx1_betaetigt, 0=Cx0_nicht_betaetigt}, range raw 0..1, transfer-property=PENDING, to Zone_VR(timeout 3.5 s)  # Auswahl der Funktion Auto links
          signal KPH_Auto_re_XIX_KPHs_01_XIX_Zone_VR_LIN06: start 8, 1 bit, little-endian, data-type-policy=OVERRIDE, i-signal-type=PRIMITIVE, init-value=0, base-type=BT_KPH_Auto_re, compu {1=Cx1_betaetigt, 0=Cx0_nicht_betaetigt}, range raw 0..1, transfer-property=PENDING, to Zone_VR(timeout 3.5 s)  # Auswahl der Funktion Auto rechts
          signal KPH_ECO_links_XIX_KPHs_01_XIX_Zone_VR_LIN06: start 9, 1 bit, little-endian, data-type-policy=OVERRIDE, i-signal-type=PRIMITIVE, init-value=0, base-type=BT_KPH_ECO_links, compu {0=Cx0_inaktiv, 1=Cx1_aktiv}, range raw 0..1, transfer-property=PENDING, to Zone_VR(timeout 3.5 s)  # Zustand der Funktion sitzplatzselektive Klimatisierung in Klimapanel hinten links
          signal KPH_ECO_rechts_XIX_KPHs_01_XIX_Zone_VR_LIN06: start 10, 1 bit, little-endian, data-type-policy=OVERRIDE, i-signal-type=PRIMITIVE, init-value=0, base-type=BT_KPH_ECO_rechts, compu {0=Cx0_inaktiv, 1=Cx1_aktiv}, range raw 0..1, transfer-property=PENDING, to Zone_VR(timeout 3.5 s)  # Zustand der Funktion sitzplatzselektive Klimatisierung in Klimapanel hinten rechts
          signal KPH_Ionisator_XIX_KPHs_01_XIX_Zone_VR_LIN06: start 12, 1 bit, little-endian, data-type-policy=OVERRIDE, i-signal-type=PRIMITIVE, init-value=0, base-type=BT_KPH_Ionisator, compu {1=Cx1_betaetigt, 0=Cx0_nicht_betaetigt}, range raw 0..1, transfer-property=PENDING, to Zone_VR(timeout 3.5 s)  # Auswahl der Funktion Ionisator
          signal KPH_Beduftung_XIX_KPHs_01_XIX_Zone_VR_LIN06: start 13, 1 bit, little-endian, data-type-policy=OVERRIDE, i-signal-type=PRIMITIVE, init-value=0, base-type=BT_KPH_Beduftung, compu {1=Cx1_betaetigt, 0=Cx0_nicht_betaetigt}, range raw 0..1, transfer-property=PENDING, to Zone_VR(timeout 3.5 s)  # Auswahl der Funktion Beduftung
          signal KPH_Flaechenheizung_XIX_KPHs_01_XIX_Zone_VR_LIN06: start 14, 1 bit, little-endian, data-type-policy=OVERRIDE, i-signal-type=PRIMITIVE, init-value=0, base-type=BT_KPH_Flaechenheizung, compu {1=Cx1_betaetigt, 0=Cx0_nicht_betaetigt}, range raw 0..1, transfer-property=PENDING, to Zone_VR(timeout 3.5 s)  # Auswahl der Funktion Flaechenheizung
          signal KPH_Sitzlueftung_li_XIX_KPHs_01_XIX_Zone_VR_LIN06: start 16, 3 bit, little-endian, data-type-policy=OVERRIDE, i-signal-type=PRIMITIVE, init-value=0, base-type=BT_KPH_Sitzlueftung_li, compu {1=Cx1_Stufe_1, 2=Cx2_Stufe_2, 4=Cx4_Stufe_4, 5=Cx5_Stufe_5, 6=Cx6_Stufe_6, 0=Cx0_Stufe_0, 3=Cx3_Stufe_3}, range raw 0..6, transfer-property=PENDING, to Zone_VR(timeout 3.5 s)  # Auswahl der Funktion Sitzlueftung links
          signal KPH_Sitzlueftung_re_XIX_KPHs_01_XIX_Zone_VR_LIN06: start 19, 3 bit, little-endian, data-type-policy=OVERRIDE, i-signal-type=PRIMITIVE, init-value=0, base-type=BT_KPH_Sitzlueftung_re, compu {1=Cx1_Stufe_1, 4=Cx4_Stufe_4, 6=Cx6_Stufe_6, 3=Cx3_Stufe_3, 0=Cx0_Stufe_0, 5=Cx5_Stufe_5, 2=Cx2_Stufe_2}, range raw 0..6, transfer-property=PENDING, to Zone_VR(timeout 3.5 s)  # Auswahl der Funktion Sitzlueftung rechts
          signal KPH_Neigungssensor_XIX_KPHs_01_XIX_Zone_VR_LIN06: start 22, 2 bit, little-endian, data-type-policy=OVERRIDE, i-signal-type=PRIMITIVE, init-value=0, base-type=BT_KPH_Neigungssensor, invalid-value=Invalid_KPH_Neigungssensor_XIX_KPHs_01_XIX_Zone_VR_LIN06:2, compu {2=Cx2_Fehler, 1=Cx1_Position_senkrecht_erkannt, 3=Cx3_nicht_verbaut, 0=Cx0_Position_waagrecht_erkannt}, range raw 0..3, transfer-property=PENDING, to Zone_VR(timeout 3.5 s)  # Status Neigungssensor
          signal KPH_Status_Spannung_XIX_KPHs_01_XIX_Zone_VR_LIN06: start 24, 2 bit, little-endian, data-type-policy=OVERRIDE, i-signal-type=PRIMITIVE, init-value=1, base-type=BT_KPH_Status_Spannung, compu {1=Cx1_Init_ungetestet, 3=Cx3_Ueberspannung, 2=Cx2_Unterspannung, 0=Cx0_OK}, range raw 0..3, transfer-property=PENDING, to Zone_VR(timeout 3.5 s)  # Status der Bordnetzspannung (KL30) am Klima Panel Hinten
          signal KPH_Tasten_Fehler_XIX_KPHs_01_XIX_Zone_VR_LIN06: start 26, 1 bit, little-endian, data-type-policy=OVERRIDE, i-signal-type=PRIMITIVE, init-value=0, base-type=BT_KPH_Tasten_Fehler, invalid-value=Invalid_KPH_Tasten_Fehler_XIX_KPHs_01_XIX_Zone_VR_LIN06:1, compu {1=Cx1_Fehler, 0=Cx0_kein_Fehler}, range raw 0..1, transfer-property=PENDING, to Zone_VR(timeout 3.5 s)
          signal KPH_Sync_XIX_KPHs_01_XIX_Zone_VR_LIN06: start 31, 1 bit, little-endian, data-type-policy=OVERRIDE, i-signal-type=PRIMITIVE, init-value=0, base-type=BT_KPH_Sync, compu {1=Cx1_betaetigt, 0=Cx0_nicht_betaetigt}, range raw 0..1, transfer-property=PENDING, to Zone_VR(timeout 3.5 s)  # Auswahl der Funktion Sync
          signal KPH_Luftverteilung_Oben_li_XIX_KPHs_01_XIX_Zone_VR_LIN06: start 32, 1 bit, little-endian, data-type-policy=OVERRIDE, i-signal-type=PRIMITIVE, init-value=0, base-type=BT_KPH_Luftverteilung_Oben_li, compu {1=Cx1_betaetigt, 0=Cx0_nicht_betaetigt}, range raw 0..1, transfer-property=PENDING, to Zone_VR(timeout 3.5 s)  # Auswahl der Funktion Luftverteilung Oben links
          signal KPH_Luftverteilung_Mitte_li_XIX_KPHs_01_XIX_Zone_VR_LIN06: start 33, 1 bit, little-endian, data-type-policy=OVERRIDE, i-signal-type=PRIMITIVE, init-value=0, base-type=BT_KPH_Luftverteilung_Mitte_li, compu {1=Cx1_betaetigt, 0=Cx0_nicht_betaetigt}, range raw 0..1, transfer-property=PENDING, to Zone_VR(timeout 3.5 s)  # Auswahl der Funktion Luftverteilung Mitte links
          signal KPH_Luftverteilung_Unten_li_XIX_KPHs_01_XIX_Zone_VR_LIN06: start 34, 1 bit, little-endian, data-type-policy=OVERRIDE, i-signal-type=PRIMITIVE, init-value=0, base-type=BT_KPH_Luftverteilung_Unten_li, compu {1=Cx1_betaetigt, 0=Cx0_nicht_betaetigt}, range raw 0..1, transfer-property=PENDING, to Zone_VR(timeout 3.5 s)  # Auswahl der Funktion Luftverteilung Unten links
          signal KPH_Luftverteilung_Auto_li_XIX_KPHs_01_XIX_Zone_VR_LIN06: start 35, 1 bit, little-endian, data-type-policy=OVERRIDE, i-signal-type=PRIMITIVE, init-value=0, base-type=BT_KPH_Luftverteilung_Auto_li, compu {0=Cx0_inaktiv, 1=Cx1_aktiv}, range raw 0..1, transfer-property=PENDING, to Zone_VR(timeout 3.5 s)  # Auswahl der Funktion Luftverteilung Auto links
          signal KPH_Luftverteilung_Oben_re_XIX_KPHs_01_XIX_Zone_VR_LIN06: start 36, 1 bit, little-endian, data-type-policy=OVERRIDE, i-signal-type=PRIMITIVE, init-value=0, base-type=BT_KPH_Luftverteilung_Oben_re, compu {1=Cx1_betaetigt, 0=Cx0_nicht_betaetigt}, range raw 0..1, transfer-property=PENDING, to Zone_VR(timeout 3.5 s)  # Auswahl der Funktion Luftverteilung Oben rechts
          signal KPH_Luftverteilung_Mitte_re_XIX_KPHs_01_XIX_Zone_VR_LIN06: start 37, 1 bit, little-endian, data-type-policy=OVERRIDE, i-signal-type=PRIMITIVE, init-value=0, base-type=BT_KPH_Luftverteilung_Mitte_re, compu {1=Cx1_betaetigt, 0=Cx0_nicht_betaetigt}, range raw 0..1, transfer-property=PENDING, to Zone_VR(timeout 3.5 s)  # Auswahl der Funktion Luftverteilung Mitte rechts
          signal KPH_Luftverteilung_Unten_re_XIX_KPHs_01_XIX_Zone_VR_LIN06: start 38, 1 bit, little-endian, data-type-policy=OVERRIDE, i-signal-type=PRIMITIVE, init-value=0, base-type=BT_KPH_Luftverteilung_Unten_re, compu {1=Cx1_betaetigt, 0=Cx0_nicht_betaetigt}, range raw 0..1, transfer-property=PENDING, to Zone_VR(timeout 3.5 s)  # Auswahl der Funktion Luftverteilung Unten rechts
          signal KPH_Luftverteilung_Auto_re_XIX_KPHs_01_XIX_Zone_VR_LIN06: start 39, 1 bit, little-endian, data-type-policy=OVERRIDE, i-signal-type=PRIMITIVE, init-value=0, base-type=BT_KPH_Luftverteilung_Auto_re, compu {0=Cx0_inaktiv, 1=Cx1_aktiv}, range raw 0..1, transfer-property=PENDING, to Zone_VR(timeout 3.5 s)  # Auswahl der Funktion Luftverteilung Auto rechts
          signal KPH_Sitzheizung_li_XIX_KPHs_01_XIX_Zone_VR_LIN06: start 40, 3 bit, little-endian, data-type-policy=OVERRIDE, i-signal-type=PRIMITIVE, init-value=0, base-type=BT_KPH_Sitzheizung_li, compu {3=Cx3_Stufe_3, 5=Cx5_Stufe_5, 1=Cx1_Stufe_1, 2=Cx2_Stufe_2, 6=Cx6_Stufe_6, 4=Cx4_Stufe_4, 0=Cx0_Stufe_0}, range raw 0..6, transfer-property=PENDING, to Zone_VR(timeout 3.5 s)  # Auswahl der Funktion Sitzheizung links
          signal KPH_Sitzheizung_re_XIX_KPHs_01_XIX_Zone_VR_LIN06: start 43, 3 bit, little-endian, data-type-policy=OVERRIDE, i-signal-type=PRIMITIVE, init-value=0, base-type=BT_KPH_Sitzheizung_re, compu {5=Cx5_Stufe_5, 3=Cx3_Stufe_3, 4=Cx4_Stufe_4, 1=Cx1_Stufe_1, 0=Cx0_Stufe_0, 6=Cx6_Stufe_6, 2=Cx2_Stufe_2}, range raw 0..6, transfer-property=PENDING, to Zone_VR(timeout 3.5 s)  # Auswahl der Funktion Sitzheizung rechts
          signal KPH_Lautsprecher_XIX_KPHs_01_XIX_Zone_VR_LIN06: start 46, 2 bit, little-endian, data-type-policy=OVERRIDE, i-signal-type=PRIMITIVE, init-value=0, base-type=BT_KPH_Lautsprecher, invalid-value=Invalid_KPH_Lautsprecher_XIX_KPHs_01_XIX_Zone_VR_LIN06:2, compu {2=Cx2_Fehler, 0=Cx0_nicht_aktiv, 1=Cx1_aktiv, 3=Cx3_nicht_verbaut}, range raw 0..3, transfer-property=PENDING, to Zone_VR(timeout 3.5 s)  # Status Lautsprecher
          signal KPH_Temp_li_XIX_KPHs_01_XIX_Zone_VR_LIN06: start 48, 8 bit, little-endian, data-type-policy=OVERRIDE, i-signal-type=PRIMITIVE, init-value=0, base-type=BT_KPH_Temp_li, invalid-value=Invalid_KPH_Temp_li_XIX_KPHs_01_XIX_Zone_VR_LIN06:255, compu {phys=raw*0.1+10 for raw 0..254, 255=Cxff_Fehler; unit Unit_DegreCelsi}, range phys 10..35.4 Unit_DegreCelsi, raw 0..255, unit=Unit_DegreCelsi, transfer-property=PENDING, to Zone_VR(timeout 3.5 s)  # Eingestellte Temperatur links
          signal KPH_Temp_re_XIX_KPHs_01_XIX_Zone_VR_LIN06: start 56, 8 bit, little-endian, data-type-policy=OVERRIDE, i-signal-type=PRIMITIVE, init-value=0, base-type=BT_KPH_Temp_re, invalid-value=Invalid_KPH_Temp_re_XIX_KPHs_01_XIX_Zone_VR_LIN06:255, compu {phys=raw*0.1+10 for raw 0..254, 255=Cxff_Fehler; unit Unit_DegreCelsi}, range phys 10..35.4 Unit_DegreCelsi, raw 0..255, unit=Unit_DegreCelsi, transfer-property=PENDING, to Zone_VR(timeout 3.5 s)  # Eingestellte Temperatur rechts
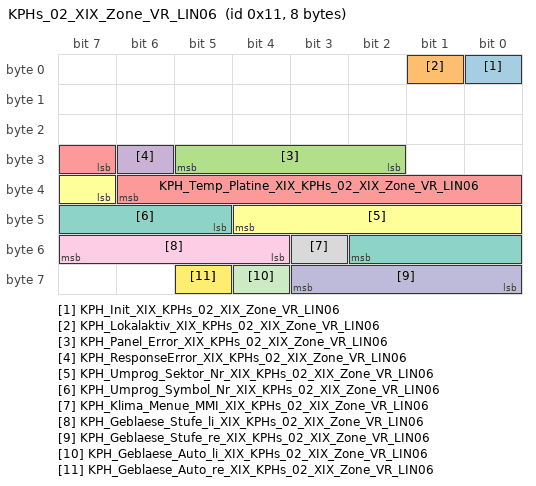
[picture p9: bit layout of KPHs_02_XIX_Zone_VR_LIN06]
      frame KPHs_02_XIX_Zone_VR_LIN06: id 0x11, to Zone_VR, frame-length=8, lin-checksum=ENHANCED
        pdu KPHs_02_XIX_Zone_VR_LIN06: length=8, unused-bit-pattern=0
          signal KPH_Init_XIX_KPHs_02_XIX_Zone_VR_LIN06: start 0, 1 bit, little-endian, data-type-policy=OVERRIDE, i-signal-type=PRIMITIVE, init-value=1, base-type=BT_KPH_Init, compu {0=Cx0_Normal_Betrieb, 1=Cx1_Init}, range raw 0..1, transfer-property=PENDING, to Zone_VR(timeout 3.5 s)  # KPH_Init zeigt eine Initialisierung / Reset des KPHs an
          signal KPH_Lokalaktiv_XIX_KPHs_02_XIX_Zone_VR_LIN06: start 1, 1 bit, little-endian, data-type-policy=OVERRIDE, i-signal-type=PRIMITIVE, init-value=0, base-type=BT_KPH_Lokalaktiv, compu {0=Cx0_war_nicht_lokal_aktiv, 1=Cx1_war_lokal_aktiv}, range raw 0..1, transfer-property=PENDING, to Zone_VR(timeout 3.5 s)
          signal KPH_Panel_Error_XIX_KPHs_02_XIX_Zone_VR_LIN06: start 26, 4 bit, little-endian, data-type-policy=OVERRIDE, i-signal-type=PRIMITIVE, init-value=0, base-type=BT_KPH_Panel_Error, compu {0=Cx0_kein_Fehler}, range raw 0, transfer-property=PENDING, to Zone_VR(timeout 3.5 s)
          signal KPH_ResponseError_XIX_KPHs_02_XIX_Zone_VR_LIN06: start 30, 1 bit, little-endian, data-type-policy=OVERRIDE, i-signal-type=PRIMITIVE, init-value=0, base-type=BT_KPH_ResponseError, invalid-value=Invalid_KPH_ResponseError_XIX_KPHs_02_XIX_Zone_VR_LIN06:1, compu {1=Cx1_Fehler, 0=Cx0_normal}, range raw 0..1, transfer-property=PENDING, to Zone_VR(timeout 3.5 s)
          signal KPH_Temp_Platine_XIX_KPHs_02_XIX_Zone_VR_LIN06: start 31, 8 bit, little-endian, data-type-policy=OVERRIDE, i-signal-type=PRIMITIVE, init-value=254, base-type=BT_KPH_Temp_Platine, invalid-value=Invalid_KPH_Temp_Platine_XIX_KPHs_02_XIX_Zone_VR_LIN06:255, compu {phys=raw-50 for raw 0..180, 255=Cxff_Fehler, 254=Cxfe_Init; unit Unit_DegreCelsi}, range phys -50..130 Unit_DegreCelsi, raw 0..255, unit=Unit_DegreCelsi, transfer-property=PENDING, to Zone_VR(timeout 3.5 s)
          signal KPH_Umprog_Sektor_Nr_XIX_KPHs_02_XIX_Zone_VR_LIN06: start 39, 6 bit, little-endian, data-type-policy=OVERRIDE, i-signal-type=PRIMITIVE, init-value=0, base-type=BT_KPH_Umprog_Sektor_Nr, compu {phys=raw for raw 0..63; unit Unit_None}, range phys 0..63 Unit_None, raw 0..63, unit=Unit_None, transfer-property=PENDING  # "Nummer des zu umpragrammierenden Sektors. 0= kein Sektor"
          signal KPH_Umprog_Symbol_Nr_XIX_KPHs_02_XIX_Zone_VR_LIN06: start 45, 6 bit, little-endian, data-type-policy=OVERRIDE, i-signal-type=PRIMITIVE, init-value=0, base-type=BT_KPH_Umprog_Symbol_Nr, compu {phys=raw for raw 0..63; unit Unit_None}, range phys 0..63 Unit_None, raw 0..63, unit=Unit_None, transfer-property=PENDING  # "Nummer des Symbols aus lok Up Table für den umprogrammierenden Sektor 0= leeres symbol"
          signal KPH_Klima_Menue_MMI_XIX_KPHs_02_XIX_Zone_VR_LIN06: start 51, 1 bit, little-endian, data-type-policy=OVERRIDE, i-signal-type=PRIMITIVE, init-value=0, base-type=BT_KPH_Klima_Menue_MMI, compu {1=Cx1_betaetigt, 0=Cx0_nicht_betaetigt}, range raw 0..1, transfer-property=PENDING, to Zone_VR(timeout 3.5 s)  # Auswahl der Funktion Klima Menue MMI
          signal KPH_Geblaese_Stufe_li_XIX_KPHs_02_XIX_Zone_VR_LIN06: start 52, 4 bit, little-endian, data-type-policy=OVERRIDE, i-signal-type=PRIMITIVE, init-value=0, base-type=BT_KPH_Geblaese_Stufe_li, compu {0=Cx0_Geblaese_Stufe_0, 6=Cx6_Geblaese_Stufe_6, 4=Cx4_Geblaese_Stufe_4, 5=Cx5_Geblaese_Stufe_5, 12=Cxc_Geblaese_Stufe_12, 2=Cx2_Geblaese_Stufe_2, 8=Cx8_Geblaese_Stufe_8, 3=Cx3_Geblaese_Stufe_3, 1=Cx1_Geblaese_Stufe_1, 11=Cxb_Geblaese_Stufe_11, 9=Cx9_Geblaese_Stufe_9, 7=Cx7_Geblaese_Stufe_7, 10=Cxa_Geblaese_Stufe_10}, range raw 0..12, transfer-property=PENDING, to Zone_VR(timeout 3.5 s)  # Auswahl der Geblaese Stufe links am Klimapanel
          signal KPH_Geblaese_Stufe_re_XIX_KPHs_02_XIX_Zone_VR_LIN06: start 56, 4 bit, little-endian, data-type-policy=OVERRIDE, i-signal-type=PRIMITIVE, init-value=0, base-type=BT_KPH_Geblaese_Stufe_re, compu {12=Cxc_Geblaese_Stufe_12, 2=Cx2_Geblaese_Stufe_2, 5=Cx5_Geblaese_Stufe_5, 11=Cxb_Geblaese_Stufe_11, 9=Cx9_Geblaese_Stufe_9, 7=Cx7_Geblaese_Stufe_7, 1=Cx1_Geblaese_Stufe_1, 8=Cx8_Geblaese_Stufe_8, 3=Cx3_Geblaese_Stufe_3, 6=Cx6_Geblaese_Stufe_6, 4=Cx4_Geblaese_Stufe_4, 10=Cxa_Geblaese_Stufe_10, 0=Cx0_Geblaese_Stufe_0}, range raw 0..12, transfer-property=PENDING, to Zone_VR(timeout 3.5 s)  # Auswahl der Geblaese Stufe rechts am Klimapanel
          signal KPH_Geblaese_Auto_li_XIX_KPHs_02_XIX_Zone_VR_LIN06: start 60, 1 bit, little-endian, data-type-policy=OVERRIDE, i-signal-type=PRIMITIVE, init-value=0, base-type=BT_KPH_Geblaese_Auto_li, compu {0=Cx0_inaktiv, 1=Cx1_aktiv}, range raw 0..1, transfer-property=PENDING, to Zone_VR(timeout 3.5 s)  # Statusanzeige der Funktion Gebläse Auto links
          signal KPH_Geblaese_Auto_re_XIX_KPHs_02_XIX_Zone_VR_LIN06: start 61, 1 bit, little-endian, data-type-policy=OVERRIDE, i-signal-type=PRIMITIVE, init-value=0, base-type=BT_KPH_Geblaese_Auto_re, compu {0=Cx0_inaktiv, 1=Cx1_aktiv}, range raw 0..1, transfer-property=PENDING, to Zone_VR(timeout 3.5 s)  # Statusanzeige der Funktion Gebläse Auto rechts
      frame MasterReq_XIX_Zone_VR_LIN06: id 0x3C, from Zone_VR, frame-length=8, lin-checksum=CLASSIC
        n pdu MasterReq_XIX_Zone_VR_LIN06: length=8
      frame SlaveResp_XIX_Zone_VR_LIN06: id 0x3D, to Zone_VR, frame-length=8, lin-checksum=CLASSIC
        n pdu SlaveResp_XIX_Zone_VR_LIN06: length=8
      5 x lin schedule table, all with resume-position=CONTINUE-AT-IT-POSITION:
        ST1: run-mode=RUN-CONTINUOUS
          table-entrys:
            delay=0.01, position-in-table=0, frame-triggering=FT_KPHe_01
            delay=0.01, position-in-table=1, frame-triggering=FT_KPHe_02
            delay=0.01, position-in-table=2, frame-triggering=FT_KPHs_01
            delay=0.01, position-in-table=3, frame-triggering=FT_KPHs_02
        DiagRequest: run-mode=RUN-ONCE, application-entry{delay=0.01, position-in-table=0, frame-triggering=CHNL/FT_MasterReq}
        DiagResponse: run-mode=RUN-ONCE, application-entry{delay=0.01, position-in-table=0, frame-triggering=CHNL/FT_SlaveResp}
        FlashRequest: run-mode=RUN-CONTINUOUS
        FlashResponse: run-mode=RUN-CONTINUOUS
  ethernet cluster ETH_Cluster_E3_20: protocol-name=Ethernet, protocol-version=802.3
    ethernet physical channel VLAN_FAS: comm-connectors=CN_VLAN_FAS
      pdu triggering PT_KN_Zone_VR: pdu=KN_Zone_VR_XIX_VLAN_FAS, from Zone_VR
      pdu triggering PT_ClampControl_KL_01: pdu=ClampControl_KL_01_XIX_VLAN_FAS, to Zone_VR
      pdu triggering PT_ClimateControl_01: pdu=ClimateControl_01_XIX_VLAN_FAS, to Zone_VR
      pdu triggering PT_ClimateControl_02: pdu=ClimateControl_02_XIX_VLAN_FAS, from Zone_VR
      pdu triggering PT_TME_01: pdu=TME_01_XIX_VLAN_FAS, from Zone_VR
      5 x network endpoint:
        NE_fd53_7cb8_0383_0002_0000_0000_0000_0ffa: network-endpoint-addresses=ipv-6-configuration={ip-address-prefix-length=64, ipv-6-address=fd53:7cb8:0383:0002:0000:0000:0000:0ffa, ipv-6-address-source=FIXED}
        NE_ff14_0000_0000_0000_0000_0000_0000_0005: network-endpoint-addresses=ipv-6-configuration={ipv-6-address=ff14:0000:0000:0000:0000:0000:0000:0005, ipv-6-address-source=FIXED}
        NE_fd53_7cb8_0383_0005_0000_0000_0000_0ff4: network-endpoint-addresses=ipv-6-configuration={default-router=fd53:7cb8:0383:0002:0000:0000:0000:fc10, ip-address-prefix-length=64, ipv-6-address=fd53:7cb8:0383:0005:0000:0000:0000:0ff4, ipv-6-address-source=FIXED}
        NE_ff14_0000_0000_0000_0000_0000_0000_0061: network-endpoint-addresses=ipv-6-configuration={ipv-6-address=ff14:0000:0000:0000:0000:0000:0000:0061, ipv-6-address-source=FIXED}
        NE_ff14_0000_0000_0000_0000_0000_0000_0062: network-endpoint-addresses=ipv-6-configuration={ipv-6-address=ff14:0000:0000:0000:0000:0000:0000:0062, ipv-6-address-source=FIXED}
      so-ad-config:
        socket connection bundle SCB_SA_Tx_fd53_7cb8_0383_0002_0000_0000_0000_0ffa_42994_UDP_4: server-port=SA_Tx_fd53_7cb8_0383_0002_0000_0000_0000_0ffa_42994_UDP_4
          bundled-connections:
            {client-ip-addr-from-connection-request=false, client-port-from-connection-request=false, client-port=SA_Rx_ff14_0000_0000_0000_0000_0000_0000_0005_42557_UDP_4, pdus=socket-connection-ipdu-identifier={header-id=1359940614, pdu-collection-semantics=QUEUED, pdu-collection-trigger=NEVER, pdu-triggering=PT_KN_Zone_VR}, pdu-collection-max-buffer-size=1452, runtime-ip-address-configuration=NONE, runtime-port-configuration=NONE, short-label=SC_Architekturinfos_Zone_VR}
            {client-ip-addr-from-connection-request=false, client-port-from-connection-request=false, client-port=SA_Rx_ff14_0000_0000_0000_0000_0000_0000_0062_42557_UDP_4, pdus=[{header-id=1359941629, pdu-collection-pdu-timeout=0.005, pdu-collection-semantics=QUEUED, pdu-collection-trigger=NEVER, pdu-triggering=PT_ClimateControl_02}, {header-id=1713, pdu-collection-semantics=QUEUED, pdu-collection-trigger=NEVER, pdu-triggering=PT_TME_01}], pdu-collection-max-buffer-size=1452, pdu-collection-timeout=0.005, runtime-ip-address-configuration=NONE, runtime-port-configuration=NONE, short-label=SC_SK_Zone_VR_01}
        socket connection bundle SCB_SA_Tx_fd53_7cb8_0383_0005_0000_0000_0000_0ff4_42994_UDP_4: socket-connection{client-ip-addr-from-connection-request=false, client-port-from-connection-request=false, client-port=SA_Rx_ff14_0000_0000_0000_0000_0000_0000_0061_42557_UDP_4, pdus=[{header-id=1359941631, pdu-collection-semantics=QUEUED, pdu-collection-trigger=NEVER, pdu-triggering=PT_ClampControl_KL_01}, {header-id=1359941630, pdu-collection-semantics=QUEUED, pdu-collection-trigger=NEVER, pdu-triggering=PT_ClimateControl_01}], pdu-collection-timeout=0.005, runtime-ip-address-configuration=NONE, runtime-port-configuration=NONE, short-label=SC_SK_VCP_Body_01}, server-port=SA_Tx_fd53_7cb8_0383_0005_0000_0000_0000_0ff4_42994_UDP_4
        5 x socket address:
          SA_Tx_fd53_7cb8_0383_0002_0000_0000_0000_0ffa_42994_UDP_4
            application endpoint AE_42994_UDP: network-endpoint=NE_fd53_7cb8_0383_0002_0000_0000_0000_0ffa, priority=4, tp-configuration=udp-tp=udp-tp-port={dynamically-assigned=false, port-number=42994}
          SA_Rx_ff14_0000_0000_0000_0000_0000_0000_0005_42557_UDP_4
            application endpoint AE_42557_UDP: network-endpoint=NE_ff14_0000_0000_0000_0000_0000_0000_0005, priority=4, tp-configuration=udp-tp=udp-tp-port={dynamically-assigned=false, port-number=42557}
          SA_Tx_fd53_7cb8_0383_0005_0000_0000_0000_0ff4_42994_UDP_4
            application endpoint AE_42994_UDP: network-endpoint=NE_fd53_7cb8_0383_0005_0000_0000_0000_0ff4, priority=4, tp-configuration=udp-tp=udp-tp-port={dynamically-assigned=false, port-number=42994}
          SA_Rx_ff14_0000_0000_0000_0000_0000_0000_0061_42557_UDP_4: multicast-connector=CN_VLAN_FAS
            application endpoint AE_42557_UDP: network-endpoint=NE_ff14_0000_0000_0000_0000_0000_0000_0061, priority=4, tp-configuration=udp-tp=udp-tp-port={dynamically-assigned=false, port-number=42557}
          SA_Rx_ff14_0000_0000_0000_0000_0000_0000_0062_42557_UDP_4
            application endpoint AE_42557_UDP: network-endpoint=NE_ff14_0000_0000_0000_0000_0000_0000_0062, priority=4, tp-configuration=udp-tp=udp-tp-port={dynamically-assigned=false, port-number=42557}
      vlan VC_VLAN_FAS: vlan-identifier=2
    mac multicast group MAC_33_33_00_00_00_61: mac-multicast-address=33:33:00:00:00:61
    mac multicast group MAC_33_33_00_00_00_62: mac-multicast-address=33:33:00:00:00:62
    mac multicast group MAC_33_33_00_00_00_05: mac-multicast-address=33:33:00:00:00:05
package /NmConfig
  nm config NmConfig
